VERSION ""

NS_ :

BS_:

BU_: SBZA_R_LS SBZA_L_LS VIS2_LS SDM_LS PEPS_LS UPA_LS PTM_LS MSM_LS HFP_LS EOCM_F_LS ECC_LS DCAC_LS CGM_LS BSM_LS BCM_LS AOS_LS

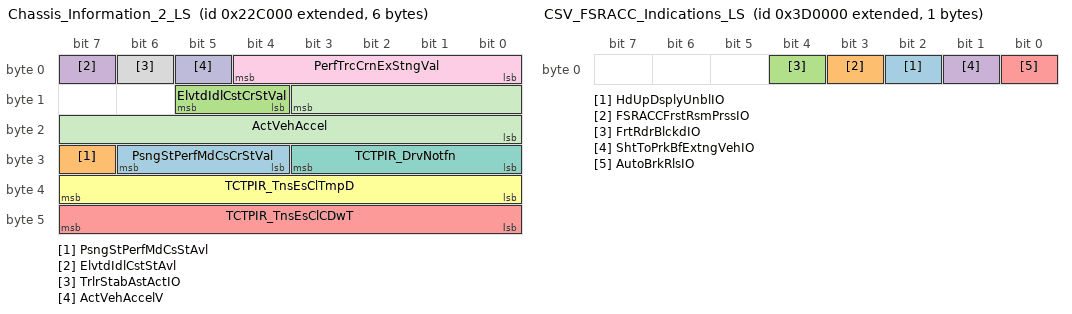
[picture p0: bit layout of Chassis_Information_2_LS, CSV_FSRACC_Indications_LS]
BO_ 2149761024 Chassis_Information_2_LS: 6 BCM_LS
 SG_ PsngStPerfMdCsCrStVal : 30|3@0+ (1,0) [0|7] ""  CGM_LS
 SG_ PsngStPerfMdCsStAvl : 31|1@0+ (1,0) [0|1] ""  CGM_LS
 SG_ ElvtdIdlCstCrStVal : 13|2@0+ (1,0) [0|3] ""  CGM_LS
 SG_ ElvtdIdlCstStAvl : 7|1@0+ (1,0) [0|1] ""  CGM_LS
 SG_ TCTPIR_TnsEsClCDwT : 47|8@0+ (0.392157,0) [0|100.000035] "%"  CGM_LS
 SG_ TCTPIR_TnsEsClTmpD : 39|8@0+ (0.392157,0) [0|100.000035] "%"  CGM_LS
 SG_ TCTPIR_DrvNotfn : 27|4@0+ (1,0) [0|15] ""  CGM_LS
 SG_ TrlrStabAstActIO : 6|1@0+ (1,0) [0|1] ""  CGM_LS
 SG_ PerfTrcCrnExStngVal : 4|5@0+ (1,0) [0|31] ""  CGM_LS
 SG_ ActVehAccelV : 5|1@0+ (1,0) [0|1] ""  CGM_LS
 SG_ ActVehAccel : 11|12@0- (0.01,0) [-20.48|20.47] "m/s^2"  CGM_LS

BO_ 2151481344 CSV_FSRACC_Indications_LS: 1 EOCM_F_LS
 SG_ HdUpDsplyUnblIO : 2|1@0+ (1,0) [0|1] ""  CGM_LS
 SG_ FSRACCFrstRsmPrssIO : 3|1@0+ (1,0) [0|1] ""  CGM_LS
 SG_ FrtRdrBlckdIO : 4|1@0+ (1,0) [0|1] ""  CGM_LS
 SG_ ShtToPrkBfExtngVehIO : 1|1@0+ (1,0) [0|1] ""  CGM_LS
 SG_ AutoBrkRlsIO : 0|1@0+ (1,0) [0|1] ""  CGM_LS

BO_ 2151432192 ACC_Drv_Seat_Vib_Req_IO_LS: 1 EOCM_F_LS
 SG_ ACCHptcStVbnRqSeqN : 1|2@0+ (1,0) [0|3] ""  MSM_LS,CGM_LS
 SG_ ACCHptcStVbnReq : 7|6@0+ (1,0) [0|63] ""  MSM_LS,CGM_LS

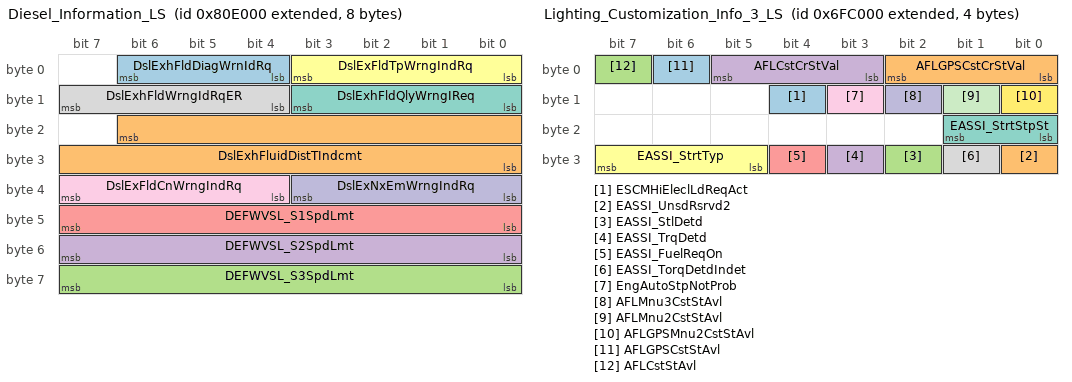
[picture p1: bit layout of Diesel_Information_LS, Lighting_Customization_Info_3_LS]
BO_ 2155929600 Diesel_Information_LS: 8 BCM_LS
 SG_ DslExhFldDiagWrnIdRq : 6|3@0+ (1,0) [0|7] ""  CGM_LS
 SG_ DslExhFluidDistTIndcmt : 22|15@0+ (2,0) [0|65534] "km"  CGM_LS
 SG_ DEFWVSL_S3SpdLmt : 63|8@0+ (1,0) [0|255] "km / h"  CGM_LS
 SG_ DEFWVSL_S2SpdLmt : 55|8@0+ (1,0) [0|255] "km / h"  CGM_LS
 SG_ DEFWVSL_S1SpdLmt : 47|8@0+ (1,0) [0|255] "km / h"  CGM_LS
 SG_ DslExFldTpWrngIndRq : 3|4@0+ (1,0) [0|15] ""  CGM_LS
 SG_ DslExhFldQlyWrngIReq : 11|4@0+ (1,0) [0|15] ""  CGM_LS
 SG_ DslExhFldWrngIdRqER : 15|4@0+ (1,0) [0|15] ""  CGM_LS
 SG_ DslExFldCnWrngIndRq : 39|4@0+ (1,0) [0|15] ""  CGM_LS
 SG_ DslExNxEmWrngIndRq : 35|4@0+ (1,0) [0|15] ""  CGM_LS

BO_ 2154807296 Lighting_Customization_Info_3_LS: 4 BCM_LS
 SG_ ESCMHiEleclLdReqAct : 12|1@0+ (1,0) [0|1] ""  ECC_LS,CGM_LS
 SG_ EASSI_UnsdRsrvd2 : 24|1@0+ (1,0) [0|1] ""  ECC_LS,CGM_LS
 SG_ EASSI_StlDetd : 26|1@0+ (1,0) [0|1] ""  ECC_LS,CGM_LS
 SG_ EASSI_TrqDetd : 27|1@0+ (1,0) [0|1] ""  ECC_LS,CGM_LS
 SG_ EASSI_FuelReqOn : 28|1@0+ (1,0) [0|1] ""  ECC_LS,CGM_LS
 SG_ EASSI_StrtTyp : 31|3@0+ (1,0) [0|7] ""  ECC_LS,CGM_LS
 SG_ EASSI_StrtStpSt : 17|2@0+ (1,0) [0|3] ""  ECC_LS,CGM_LS
 SG_ EASSI_TorqDetdIndet : 25|1@0+ (1,0) [0|1] ""  ECC_LS,CGM_LS
 SG_ EngAutoStpNotProb : 11|1@0+ (1,0) [0|1] ""  ECC_LS,CGM_LS
 SG_ AFLMnu3CstStAvl : 10|1@0+ (1,0) [0|1] ""  CGM_LS
 SG_ AFLMnu2CstStAvl : 9|1@0+ (1,0) [0|1] ""  CGM_LS
 SG_ AFLGPSMnu2CstStAvl : 8|1@0+ (1,0) [0|1] ""  CGM_LS
 SG_ AFLGPSCstStAvl : 6|1@0+ (1,0) [0|1] ""  CGM_LS
 SG_ AFLGPSCstCrStVal : 2|3@0+ (1,0) [0|7] ""  CGM_LS
 SG_ AFLCstStAvl : 7|1@0+ (1,0) [0|1] ""  CGM_LS
 SG_ AFLCstCrStVal : 5|3@0+ (1,0) [0|7] ""  CGM_LS

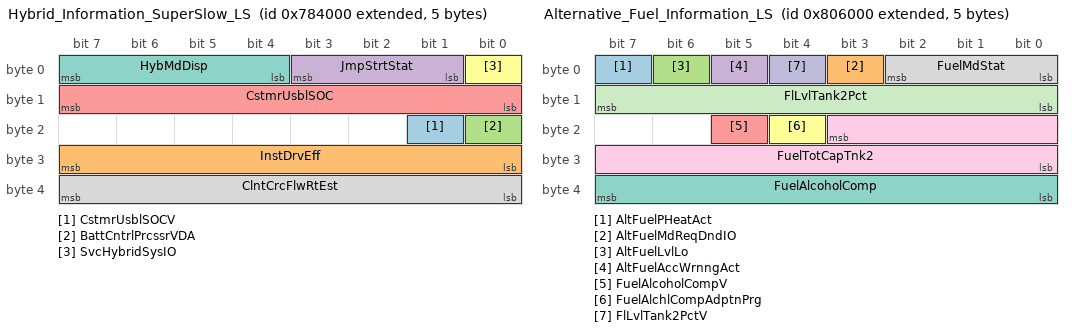
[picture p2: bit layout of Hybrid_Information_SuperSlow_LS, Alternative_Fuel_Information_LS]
BO_ 2155364352 Hybrid_Information_SuperSlow_LS: 5 BCM_LS
 SG_ CstmrUsblSOCV : 17|1@0+ (1,0) [0|1] ""  CGM_LS,BCM_LS
 SG_ InstDrvEff : 31|8@0- (0.78125,0) [-100|99.21875] "%"  CGM_LS
 SG_ BattCntrlPrcssrVDA : 16|1@0+ (1,0) [0|1] ""  CGM_LS
 SG_ JmpStrtStat : 3|3@0+ (1,0) [0|7] ""  CGM_LS
 SG_ CstmrUsblSOC : 15|8@0+ (0.39216,0) [0|100.0008] "%"  CGM_LS,BCM_LS
 SG_ SvcHybridSysIO : 0|1@0+ (1,0) [0|1] ""  CGM_LS
 SG_ HybMdDisp : 7|4@0+ (1,0) [0|15] ""  CGM_LS
 SG_ ClntCrcFlwRtEst : 39|8@0+ (0.392157,0) [0|100.000035] "%"  ECC_LS,CGM_LS

BO_ 2155896832 Alternative_Fuel_Information_LS: 5 BCM_LS
 SG_ AltFuelPHeatAct : 7|1@0+ (1,0) [0|1] ""  CGM_LS
 SG_ AltFuelMdReqDndIO : 3|1@0+ (1,0) [0|1] ""  CGM_LS
 SG_ AltFuelLvlLo : 6|1@0+ (1,0) [0|1] ""  CGM_LS
 SG_ AltFuelAccWrnngAct : 5|1@0+ (1,0) [0|1] ""  CGM_LS
 SG_ FuelAlcoholCompV : 21|1@0+ (1,0) [0|1] ""  CGM_LS
 SG_ FuelAlchlCompAdptnPrg : 20|1@0+ (1,0) [0|1] ""  CGM_LS
 SG_ FuelAlcoholComp : 39|8@0+ (0.392157,0) [0|100.000035] "%"  CGM_LS
 SG_ FuelMdStat : 2|3@0+ (1,0) [0|7] ""  CGM_LS
 SG_ FuelTotCapTnk2 : 19|12@0+ (0.125,0) [0|511.875] "liters"  CGM_LS
 SG_ FlLvlTank2PctV : 4|1@0+ (1,0) [0|1] ""  CGM_LS
 SG_ FlLvlTank2Pct : 15|8@0+ (0.392157,0) [0|100.000035] "%"  CGM_LS

BO_ 2153390080 Manual_Liftgate_Control_LS: 1 BCM_LS
 SG_ RrClosOpenSwAct_2D1V : 3|1@0+ (1,0) [0|1] ""  CGM_LS
 SG_ RrClosOpenSwAct_2D1 : 1|1@0+ (1,0) [0|1] ""  CGM_LS

BO_ 2155175936 CruiseControlGapSwitch_LS: 1 BCM_LS
 SG_ AdptCrsLKALDWSwAct : 2|1@0+ (1,0) [0|1] ""  CGM_LS
 SG_ AdptCrsGapSwAct : 1|2@0+ (1,0) [0|3] ""  CGM_LS

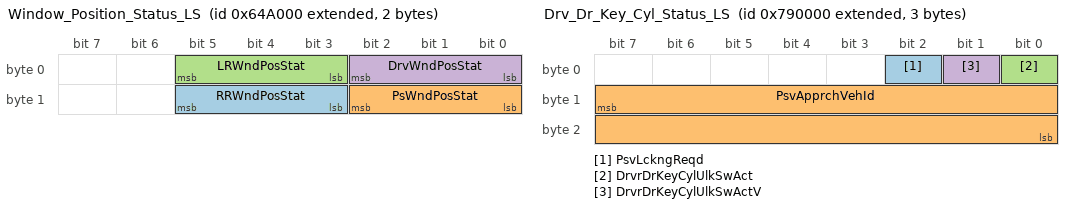
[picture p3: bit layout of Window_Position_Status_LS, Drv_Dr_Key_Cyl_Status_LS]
BO_ 2154078208 Window_Position_Status_LS: 2 BCM_LS
 SG_ RRWndPosStat : 13|3@0+ (1,0) [0|7] ""  PTM_LS,CGM_LS
 SG_ PsWndPosStat : 10|3@0+ (1,0) [0|7] ""  PTM_LS,CGM_LS
 SG_ LRWndPosStat : 5|3@0+ (1,0) [0|7] ""  PTM_LS,CGM_LS
 SG_ DrvWndPosStat : 2|3@0+ (1,0) [0|7] ""  PTM_LS,CGM_LS

BO_ 2155495424 Remote_Start_Seat_Request_LS: 1 BCM_LS
 SG_ RmStrHtdStEnRq : 1|1@0+ (1,0) [0|1] ""  MSM_LS,ECC_LS,CGM_LS
 SG_ RmStrCldStEnReq : 0|1@0+ (1,0) [0|1] ""  MSM_LS,CGM_LS

BO_ 2155413504 Drv_Dr_Key_Cyl_Status_LS: 3 BCM_LS
 SG_ PsvLckngReqd : 2|1@0+ (1,0) [0|1] ""  PEPS_LS,CGM_LS
 SG_ PsvApprchVehId : 15|16@0+ (1,0) [0|65535] ""  PEPS_LS,CGM_LS
 SG_ DrvrDrKeyCylUlkSwAct : 0|1@0+ (1,0) [0|1] ""  PEPS_LS,CGM_LS
 SG_ DrvrDrKeyCylUlkSwActV : 1|1@0+ (1,0) [0|1] ""  PEPS_LS,CGM_LS

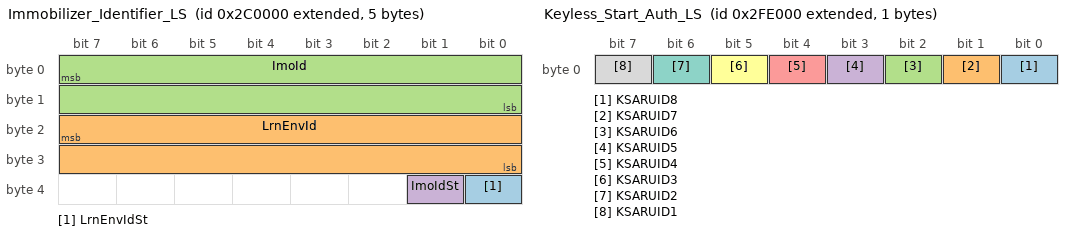
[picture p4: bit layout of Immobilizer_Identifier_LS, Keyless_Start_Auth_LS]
BO_ 2150367232 Immobilizer_Identifier_LS: 5 BCM_LS
 SG_ LrnEnvIdSt : 32|1@0+ (1,0) [0|1] ""  SDM_LS,ECC_LS,CGM_LS
 SG_ LrnEnvId : 23|16@0+ (1,0) [0|65535] ""  SDM_LS,ECC_LS,CGM_LS
 SG_ ImoId : 7|16@0+ (1,0) [0|65535] ""  SDM_LS,ECC_LS,CGM_LS
 SG_ ImoIdSt : 33|1@0+ (1,0) [0|1] ""  SDM_LS,ECC_LS,CGM_LS

BO_ 2150621184 Keyless_Start_Auth_LS: 1 BCM_LS
 SG_ KSARUID8 : 0|1@0+ (1,0) [0|1] ""  PEPS_LS,CGM_LS
 SG_ KSARUID7 : 1|1@0+ (1,0) [0|1] ""  PEPS_LS,CGM_LS
 SG_ KSARUID6 : 2|1@0+ (1,0) [0|1] ""  PEPS_LS,CGM_LS
 SG_ KSARUID5 : 3|1@0+ (1,0) [0|1] ""  PEPS_LS,CGM_LS
 SG_ KSARUID4 : 4|1@0+ (1,0) [0|1] ""  PEPS_LS,CGM_LS
 SG_ KSARUID3 : 5|1@0+ (1,0) [0|1] ""  PEPS_LS,CGM_LS
 SG_ KSARUID2 : 6|1@0+ (1,0) [0|1] ""  PEPS_LS,CGM_LS
 SG_ KSARUID1 : 7|1@0+ (1,0) [0|1] ""  PEPS_LS,CGM_LS

BO_ 2151309312 Inflatable_Restraints_Key_Id_LS: 2 BCM_LS
 SG_ InflRestId : 7|16@0+ (1,0) [0|39321] ""  SDM_LS,CGM_LS

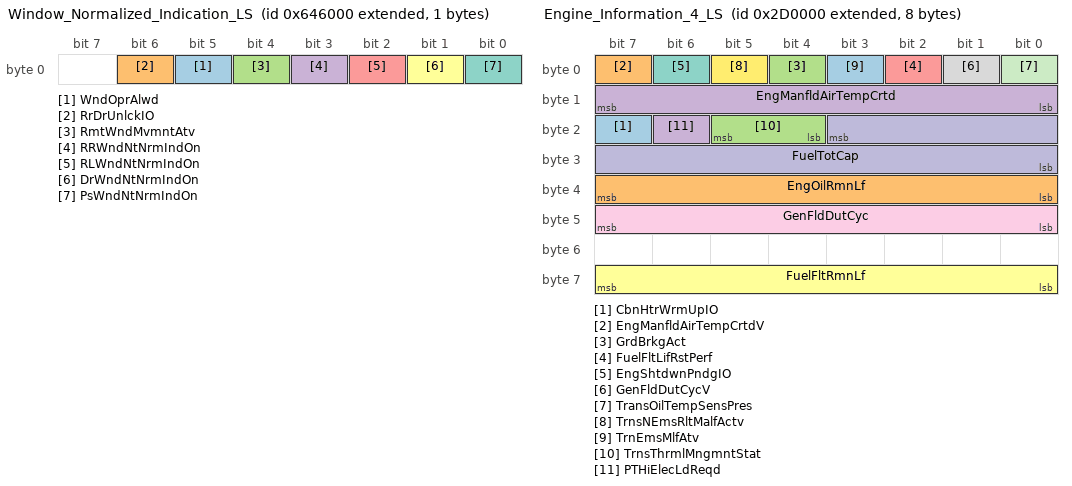
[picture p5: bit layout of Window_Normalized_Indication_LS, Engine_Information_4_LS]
BO_ 2154061824 Window_Normalized_Indication_LS: 1 BCM_LS
 SG_ WndOprAlwd : 5|1@0+ (1,0) [0|1] ""  CGM_LS
 SG_ RrDrUnlckIO : 6|1@0+ (1,0) [0|1] ""  CGM_LS
 SG_ RmtWndMvmntAtv : 4|1@0+ (1,0) [0|1] ""  CGM_LS
 SG_ RRWndNtNrmIndOn : 3|1@0+ (1,0) [0|1] ""  CGM_LS
 SG_ RLWndNtNrmIndOn : 2|1@0+ (1,0) [0|1] ""  CGM_LS
 SG_ DrWndNtNrmIndOn : 1|1@0+ (1,0) [0|1] ""  CGM_LS
 SG_ PsWndNtNrmIndOn : 0|1@0+ (1,0) [0|1] ""  CGM_LS

BO_ 2154512384 Rear_Closure_Rel_Sw_Sta_LS: 1 BCM_LS
 SG_ RrClosRelSwActV : 1|1@0+ (1,0) [0|1] ""  PEPS_LS,CGM_LS
 SG_ RrClosRelSwAct : 0|1@0+ (1,0) [0|1] ""  PEPS_LS,CGM_LS

BO_ 2155347968 HS_Indications_Slow_LS: 8 BCM_LS
 SG_ DrvrStPerfMdCsCrStVal : 62|3@0+ (1,0) [0|7] ""  CGM_LS
 SG_ DrvrStPerfMdCsStAvl : 63|1@0+ (1,0) [0|1] ""  CGM_LS
 SG_ ACCPerfMdCsCrStVal : 58|3@0+ (1,0) [0|7] ""  CGM_LS
 SG_ ACCPerfMdCsStAvl : 59|1@0+ (1,0) [0|1] ""  CGM_LS
 SG_ VehRollAngleV : 55|1@0+ (1,0) [0|1] ""  CGM_LS
 SG_ VehRollAngle : 54|7@0+ (0.703125,-45) [-45|44.296875] "deg"  CGM_LS
 SG_ ActVbnCtrlMlfIO : 0|1@0+ (1,0) [0|1] ""  CGM_LS
 SG_ HillDesCtrlRedVehSpIO : 47|1@0+ (1,0) [0|1] ""  CGM_LS
 SG_ FourWhlDrvIndReq : 42|3@0+ (1,0) [0|7] ""  CGM_LS
 SG_ PedtrnProtVDA : 35|1@0+ (1,0) [0|1] ""  CGM_LS
 SG_ EngRecDwnshftIO : 43|1@0+ (1,0) [0|1] ""  CGM_LS
 SG_ AppCltchAutSrtIO : 36|1@0+ (1,0) [0|1] ""  CGM_LS
 SG_ CPSUnblIO : 32|1@0+ (1,0) [0|1] ""  CGM_LS
 SG_ StBltTgtSetAvl : 37|1@0+ (1,0) [0|1] ""  CGM_LS
 SG_ StBltTgtCrtSetVal : 46|3@0+ (1,0) [0|7] ""  CGM_LS
 SG_ PedtrnProtSysDisbld : 34|1@0+ (1,0) [0|1] ""  CGM_LS
 SG_ PedtrnProtSysDpl : 1|1@0+ (1,0) [0|1] ""  CGM_LS
 SG_ SrvPedtrnProtSysIO : 33|1@0+ (1,0) [0|1] ""  CGM_LS
 SG_ CPSOffIO : 31|1@0+ (1,0) [0|1] ""  CGM_LS
 SG_ SecAxlTmpInhIO : 24|1@0+ (1,0) [0|1] ""  CGM_LS
 SG_ CPSFldIO : 30|1@0+ (1,0) [0|1] ""  CGM_LS
 SG_ CPSAlrtOnlIO : 25|1@0+ (1,0) [0|1] ""  CGM_LS
 SG_ RrAxlTmpInhIO : 23|1@0+ (1,0) [0|1] ""  CGM_LS
 SG_ TirePrsLowIO : 2|1@0+ (1,0) [0|1] ""  SDM_LS,CGM_LS
 SG_ EPBSysStatIndReq : 27|2@0+ (1,0) [0|3] ""  CGM_LS
 SG_ EngOilStrvtnIO : 5|1@0+ (1,0) [0|1] ""  CGM_LS
 SG_ SrvSuspSysIO : 12|1@0+ (1,0) [0|1] ""  CGM_LS
 SG_ ServAdpCrsCtrlIndOn : 11|1@0+ (1,0) [0|1] ""  CGM_LS
 SG_ EngRecmndUpshftIO : 10|1@0+ (1,0) [0|1] ""  CGM_LS
 SG_ BrkSysMalFuncIndOn : 15|1@0+ (1,0) [0|1] ""  VIS2_LS,CGM_LS
 SG_ SecAxlNonEmMalfIO : 6|1@0+ (1,0) [0|1] ""  CGM_LS
 SG_ BrkFldLvlLw : 7|1@0+ (1,0) [0|1] ""  CGM_LS
 SG_ ACCUnavlbleDTWthrIO : 3|1@0+ (1,0) [0|1] ""  CGM_LS
 SG_ ACCTmpUnavlbleIO : 9|1@0+ (1,0) [0|1] ""  CGM_LS
 SG_ EngEmsRelMalfIndReq : 18|3@0+ (1,0) [0|7] ""  CGM_LS
 SG_ DrShftCntrlReqDndIO : 20|1@0+ (1,0) [0|1] ""  CGM_LS
 SG_ BrkPadWrnIO : 13|1@0+ (1,0) [0|1] ""  CGM_LS
 SG_ RrAxlMalfIO : 19|1@0+ (1,0) [0|1] ""  CGM_LS
 SG_ EPBSysWrnIndReq : 29|2@0+ (1,0) [0|3] ""  CGM_LS
 SG_ CompOvrhtIndOn : 21|1@0+ (1,0) [0|1] ""  CGM_LS
 SG_ BrkFldLvlLwV : 4|1@0+ (1,0) [0|1] ""  CGM_LS
 SG_ ACCSnsClnRqdIO : 8|1@0+ (1,0) [0|1] ""  CGM_LS
 SG_ TrnsSkpShftIO : 22|1@0+ (1,0) [0|1] ""  CGM_LS

BO_ 2150432768 Engine_Information_4_LS: 8 BCM_LS
 SG_ CbnHtrWrmUpIO : 23|1@0+ (1,0) [0|1] ""  CGM_LS
 SG_ EngManfldAirTempCrtdV : 7|1@0+ (1,0) [0|1] ""  ECC_LS,CGM_LS
 SG_ GrdBrkgAct : 4|1@0+ (1,0) [0|1] ""  CGM_LS
 SG_ EngManfldAirTempCrtd : 15|8@0+ (1,-40) [-40|215] "deg C"  ECC_LS,CGM_LS
 SG_ FuelFltLifRstPerf : 2|1@0+ (1,0) [0|1] ""  CGM_LS
 SG_ FuelFltRmnLf : 63|8@0+ (0.392157,0) [0|100.000035] "%"  CGM_LS
 SG_ EngShtdwnPndgIO : 6|1@0+ (1,0) [0|1] ""  CGM_LS
 SG_ GenFldDutCycV : 1|1@0+ (1,0) [0|1] ""  ECC_LS,CGM_LS
 SG_ GenFldDutCyc : 47|8@0+ (0.392157,0) [0|100.000035] "%"  ECC_LS,CGM_LS
 SG_ FuelTotCap : 19|12@0+ (0.125,0) [0|511.875] "liters"  CGM_LS
 SG_ TransOilTempSensPres : 0|1@0+ (1,0) [0|1] ""  CGM_LS
 SG_ TrnsNEmsRltMalfActv : 5|1@0+ (1,0) [0|1] ""  CGM_LS
 SG_ TrnEmsMlfAtv : 3|1@0+ (1,0) [0|1] ""  CGM_LS
 SG_ EngOilRmnLf : 39|8@0+ (0.392157,0) [0|100.000035] "%"  CGM_LS
 SG_ TrnsThrmlMngmntStat : 21|2@0+ (1,0) [0|3] ""  CGM_LS
 SG_ PTHiElecLdReqd : 22|1@0+ (1,0) [0|1] ""  ECC_LS,CGM_LS

BO_ 2154938368 Fob_Programming_Mode_Status_LS: 1 BCM_LS
 SG_ FobProgMdStat : 1|2@0+ (1,0) [0|3] ""  CGM_LS

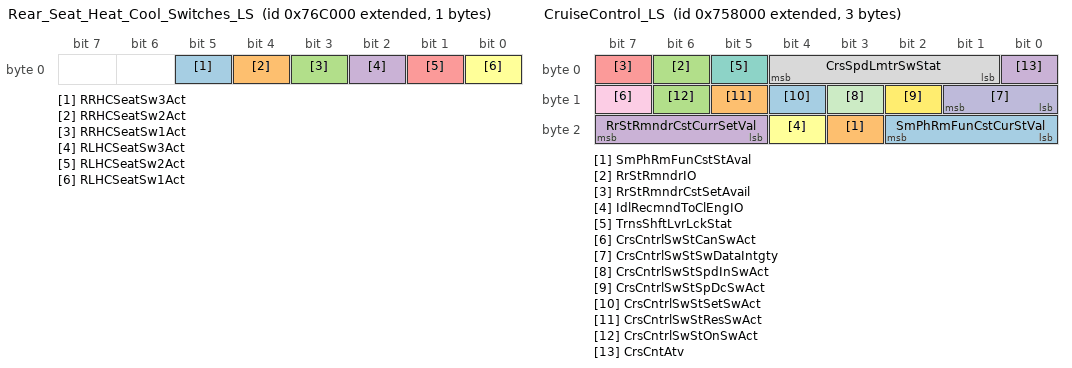
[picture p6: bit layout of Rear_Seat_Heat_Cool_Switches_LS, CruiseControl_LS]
BO_ 2155266048 Rear_Seat_Heat_Cool_Switches_LS: 1 BCM_LS
 SG_ RRHCSeatSw3Act : 5|1@0+ (1,0) [0|1] ""  BCM_LS,CGM_LS
 SG_ RRHCSeatSw2Act : 4|1@0+ (1,0) [0|1] ""  BCM_LS,CGM_LS
 SG_ RRHCSeatSw1Act : 3|1@0+ (1,0) [0|1] ""  BCM_LS,CGM_LS
 SG_ RLHCSeatSw3Act : 2|1@0+ (1,0) [0|1] ""  BCM_LS,CGM_LS
 SG_ RLHCSeatSw2Act : 1|1@0+ (1,0) [0|1] ""  BCM_LS,CGM_LS
 SG_ RLHCSeatSw1Act : 0|1@0+ (1,0) [0|1] ""  BCM_LS,CGM_LS

BO_ 2155249664 Rear_Seat_Heat_Cool_Control_LS: 4 BCM_LS
 SG_ RRHCSMInd3 : 8|1@0+ (1,0) [0|1] ""  ECC_LS,CGM_LS,BCM_LS
 SG_ RRHCSMInd2 : 9|1@0+ (1,0) [0|1] ""  ECC_LS,CGM_LS,BCM_LS
 SG_ RRHCSMInd1 : 10|1@0+ (1,0) [0|1] ""  ECC_LS,CGM_LS,BCM_LS
 SG_ RRHCSMIndReq : 12|2@0+ (1,0) [0|3] ""  ECC_LS,CGM_LS,BCM_LS
 SG_ RRHCSLSeatLev5 : 24|1@0+ (1,0) [0|1] ""  ECC_LS,CGM_LS,BCM_LS
 SG_ RRHCSLSeatLev4 : 25|1@0+ (1,0) [0|1] ""  ECC_LS,CGM_LS,BCM_LS
 SG_ RRHCSLSeatLev3 : 26|1@0+ (1,0) [0|1] ""  ECC_LS,CGM_LS,BCM_LS
 SG_ RRHCSLSeatLev2 : 27|1@0+ (1,0) [0|1] ""  ECC_LS,CGM_LS,BCM_LS
 SG_ RRHCSLSeatLev1 : 28|1@0+ (1,0) [0|1] ""  ECC_LS,CGM_LS,BCM_LS
 SG_ RRHCSLIndReq : 30|2@0+ (1,0) [0|3] ""  ECC_LS,CGM_LS,BCM_LS
 SG_ RLHCSMInd3 : 0|1@0+ (1,0) [0|1] ""  ECC_LS,CGM_LS,BCM_LS
 SG_ RLHCSMInd2 : 1|1@0+ (1,0) [0|1] ""  ECC_LS,CGM_LS,BCM_LS
 SG_ RLHCSMInd1 : 2|1@0+ (1,0) [0|1] ""  ECC_LS,CGM_LS,BCM_LS
 SG_ RLHCSMIndReq : 4|2@0+ (1,0) [0|3] ""  ECC_LS,CGM_LS,BCM_LS
 SG_ RLHCSLSeatLev5 : 16|1@0+ (1,0) [0|1] ""  ECC_LS,CGM_LS,BCM_LS
 SG_ RLHCSLSeatLev4 : 17|1@0+ (1,0) [0|1] ""  ECC_LS,CGM_LS,BCM_LS
 SG_ RLHCSLSeatLev3 : 18|1@0+ (1,0) [0|1] ""  ECC_LS,CGM_LS,BCM_LS
 SG_ RLHCSLSeatLev2 : 19|1@0+ (1,0) [0|1] ""  ECC_LS,CGM_LS,BCM_LS
 SG_ RLHCSLSeatLev1 : 20|1@0+ (1,0) [0|1] ""  ECC_LS,CGM_LS,BCM_LS
 SG_ RLHCSLIndReq : 22|2@0+ (1,0) [0|3] ""  ECC_LS,CGM_LS,BCM_LS

BO_ 2155184128 CruiseControl_LS: 3 BCM_LS
 SG_ SmPhRmFunCstCurStVal : 18|3@0+ (1,0) [0|7] ""  CGM_LS
 SG_ SmPhRmFunCstStAval : 19|1@0+ (1,0) [0|1] ""  CGM_LS
 SG_ RrStRmndrIO : 6|1@0+ (1,0) [0|1] ""  CGM_LS
 SG_ RrStRmndrCstCurrSetVal : 23|3@0+ (1,0) [0|7] ""  CGM_LS
 SG_ RrStRmndrCstSetAvail : 7|1@0+ (1,0) [0|1] ""  CGM_LS
 SG_ IdlRecmndToClEngIO : 20|1@0+ (1,0) [0|1] ""  CGM_LS
 SG_ TrnsShftLvrLckStat : 5|1@0+ (1,0) [0|1] ""  CGM_LS
 SG_ CrsSpdLmtrSwStat : 4|4@0+ (1,0) [0|15] ""  SDM_LS,CGM_LS
 SG_ CrsCntrlSwStCanSwAct : 15|1@0+ (1,0) [0|1] ""  SDM_LS,CGM_LS
 SG_ CrsCntrlSwStSwDataIntgty : 9|2@0+ (1,0) [0|3] ""  SDM_LS,CGM_LS
 SG_ CrsCntrlSwStSpdInSwAct : 11|1@0+ (1,0) [0|1] ""  SDM_LS,CGM_LS
 SG_ CrsCntrlSwStSpDcSwAct : 10|1@0+ (1,0) [0|1] ""  SDM_LS,CGM_LS
 SG_ CrsCntrlSwStSetSwAct : 12|1@0+ (1,0) [0|1] ""  SDM_LS,CGM_LS
 SG_ CrsCntrlSwStResSwAct : 13|1@0+ (1,0) [0|1] ""  SDM_LS,CGM_LS
 SG_ CrsCntrlSwStOnSwAct : 14|1@0+ (1,0) [0|1] ""  SDM_LS,CGM_LS
 SG_ CrsCntAtv : 0|1@0+ (1,0) [0|1] ""  VIS2_LS,SDM_LS,CGM_LS

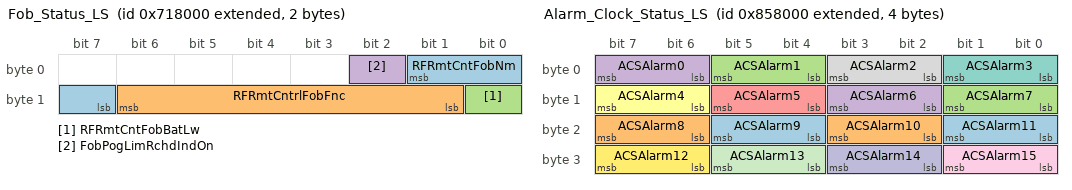
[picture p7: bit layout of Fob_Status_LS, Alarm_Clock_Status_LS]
BO_ 2154921984 Fob_Status_LS: 2 BCM_LS
 SG_ RFRmtCntFobNm : 1|3@0+ (1,0) [0|7] ""  PTM_LS,PEPS_LS,MSM_LS,BSM_LS,CGM_LS
 SG_ RFRmtCntrlFobFnc : 14|6@0+ (1,0) [0|63] ""  PTM_LS,PEPS_LS,MSM_LS,BSM_LS,CGM_LS
 SG_ RFRmtCntFobBatLw : 8|1@0+ (1,0) [0|1] ""  PTM_LS,PEPS_LS,MSM_LS,BSM_LS,CGM_LS
 SG_ FobPogLimRchdIndOn : 2|1@0+ (1,0) [0|1] ""  CGM_LS

BO_ 2154962944 Front_Seat_Heat_Cool_Control_LS: 4 BCM_LS
 SG_ PassHCSMInd3 : 8|1@0+ (1,0) [0|1] ""  ECC_LS,CGM_LS
 SG_ PassHCSMInd2 : 9|1@0+ (1,0) [0|1] ""  ECC_LS,CGM_LS
 SG_ PassHCSMInd1 : 10|1@0+ (1,0) [0|1] ""  ECC_LS,CGM_LS
 SG_ PassHCSMIndReq : 12|2@0+ (1,0) [0|3] ""  ECC_LS,CGM_LS
 SG_ PassHCSLSeatLev5 : 24|1@0+ (1,0) [0|1] ""  ECC_LS,CGM_LS
 SG_ PassHCSLSeatLev4 : 25|1@0+ (1,0) [0|1] ""  ECC_LS,CGM_LS
 SG_ PassHCSLSeatLev3 : 26|1@0+ (1,0) [0|1] ""  ECC_LS,CGM_LS
 SG_ PassHCSLSeatLev2 : 27|1@0+ (1,0) [0|1] ""  ECC_LS,CGM_LS
 SG_ PassHCSLSeatLev1 : 28|1@0+ (1,0) [0|1] ""  ECC_LS,CGM_LS
 SG_ PassHCSLIndReq : 30|2@0+ (1,0) [0|3] ""  ECC_LS,CGM_LS
 SG_ DrvHCSMInd1 : 2|1@0+ (1,0) [0|1] ""  ECC_LS,CGM_LS
 SG_ DrvHCSMIndReq : 4|2@0+ (1,0) [0|3] ""  ECC_LS,CGM_LS
 SG_ DrvHCSMInd3 : 0|1@0+ (1,0) [0|1] ""  ECC_LS,CGM_LS
 SG_ DrvHCSMInd2 : 1|1@0+ (1,0) [0|1] ""  ECC_LS,CGM_LS
 SG_ DrvHCSLSeatLev5 : 16|1@0+ (1,0) [0|1] ""  ECC_LS,CGM_LS
 SG_ DrvHCSLSeatLev4 : 17|1@0+ (1,0) [0|1] ""  ECC_LS,CGM_LS
 SG_ DrvHCSLSeatLev3 : 18|1@0+ (1,0) [0|1] ""  ECC_LS,CGM_LS
 SG_ DrvHCSLSeatLev2 : 19|1@0+ (1,0) [0|1] ""  ECC_LS,CGM_LS
 SG_ DrvHCSLSeatLev1 : 20|1@0+ (1,0) [0|1] ""  ECC_LS,CGM_LS
 SG_ DrvHCSLIndReq : 22|2@0+ (1,0) [0|3] ""  ECC_LS,CGM_LS

BO_ 2156232704 Alarm_Clock_Status_LS: 4 BCM_LS
 SG_ ACSAlarm9 : 21|2@0+ (1,0) [0|3] ""  PTM_LS,ECC_LS,CGM_LS
 SG_ ACSAlarm8 : 23|2@0+ (1,0) [0|3] ""  PTM_LS,ECC_LS,CGM_LS
 SG_ ACSAlarm7 : 9|2@0+ (1,0) [0|3] ""  PTM_LS,ECC_LS,CGM_LS
 SG_ ACSAlarm6 : 11|2@0+ (1,0) [0|3] ""  PTM_LS,ECC_LS,CGM_LS
 SG_ ACSAlarm5 : 13|2@0+ (1,0) [0|3] ""  PTM_LS,ECC_LS,CGM_LS
 SG_ ACSAlarm4 : 15|2@0+ (1,0) [0|3] ""  PTM_LS,ECC_LS,CGM_LS
 SG_ ACSAlarm3 : 1|2@0+ (1,0) [0|3] ""  PTM_LS,ECC_LS,CGM_LS
 SG_ ACSAlarm2 : 3|2@0+ (1,0) [0|3] ""  PTM_LS,ECC_LS,CGM_LS
 SG_ ACSAlarm15 : 25|2@0+ (1,0) [0|3] ""  PTM_LS,ECC_LS,CGM_LS
 SG_ ACSAlarm14 : 27|2@0+ (1,0) [0|3] ""  PTM_LS,ECC_LS,CGM_LS
 SG_ ACSAlarm13 : 29|2@0+ (1,0) [0|3] ""  PTM_LS,ECC_LS,CGM_LS
 SG_ ACSAlarm12 : 31|2@0+ (1,0) [0|3] ""  PTM_LS,ECC_LS,CGM_LS
 SG_ ACSAlarm11 : 17|2@0+ (1,0) [0|3] ""  PTM_LS,ECC_LS,CGM_LS
 SG_ ACSAlarm10 : 19|2@0+ (1,0) [0|3] ""  PTM_LS,ECC_LS,CGM_LS
 SG_ ACSAlarm1 : 5|2@0+ (1,0) [0|3] ""  PTM_LS,ECC_LS,CGM_LS
 SG_ ACSAlarm0 : 7|2@0+ (1,0) [0|3] ""  PTM_LS,ECC_LS,CGM_LS

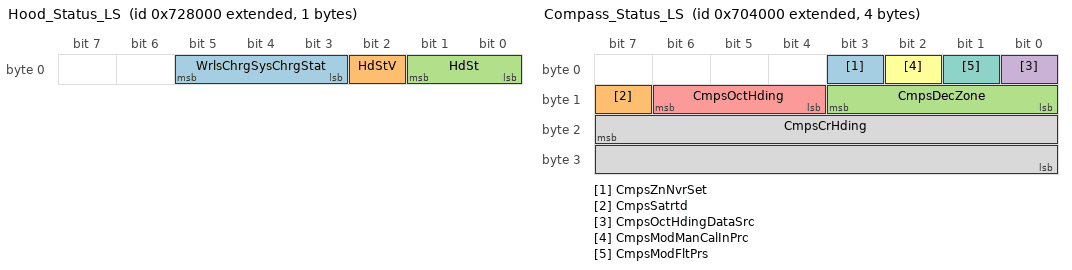
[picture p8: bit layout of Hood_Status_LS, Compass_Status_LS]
BO_ 2154987520 Hood_Status_LS: 1 BCM_LS
 SG_ WrlsChrgSysChrgStat : 5|3@0+ (1,0) [0|7] ""  CGM_LS
 SG_ HdStV : 2|1@0+ (1,0) [0|1] ""  CGM_LS
 SG_ HdSt : 1|2@0+ (1,0) [0|3] ""  CGM_LS

BO_ 2154840064 Compass_Status_LS: 4 BCM_LS
 SG_ CmpsZnNvrSet : 3|1@0+ (1,0) [0|1] ""  CGM_LS
 SG_ CmpsSatrtd : 15|1@0+ (1,0) [0|1] ""  CGM_LS
 SG_ CmpsDecZone : 11|4@0+ (1,0) [0|15] ""  CGM_LS
 SG_ CmpsOctHdingDataSrc : 0|1@0+ (1,0) [0|1] ""  CGM_LS
 SG_ CmpsOctHding : 14|3@0+ (1,0) [0|7] ""  CGM_LS
 SG_ CmpsModManCalInPrc : 2|1@0+ (1,0) [0|1] ""  CGM_LS
 SG_ CmpsModFltPrs : 1|1@0+ (1,0) [0|1] ""  CGM_LS
 SG_ CmpsCrHding : 23|16@0+ (0.0054932,0) [0|359.996862] "deg"  CGM_LS

BO_ 2154905600 Driver_Identifier_LS: 1 BCM_LS
 SG_ DrvSeatPrsMemID : 5|3@0+ (1,0) [0|7] ""  MSM_LS,CGM_LS
 SG_ DrId : 2|3@0+ (1,0) [0|7] ""  VIS2_LS,MSM_LS,EOCM_F_LS,ECC_LS,CGM_LS

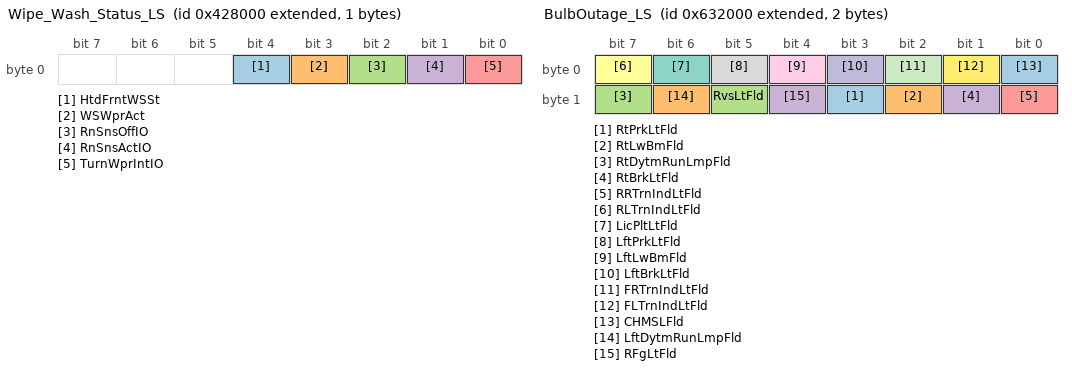
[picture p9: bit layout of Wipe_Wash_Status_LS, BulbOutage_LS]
BO_ 2151841792 Wipe_Wash_Status_LS: 1 BCM_LS
 SG_ HtdFrntWSSt : 4|1@0+ (1,0) [0|1] ""  CGM_LS
 SG_ WSWprAct : 3|1@0+ (1,0) [0|1] ""  SBZA_R_LS,SBZA_L_LS,VIS2_LS,CGM_LS
 SG_ RnSnsOffIO : 2|1@0+ (1,0) [0|1] ""  SBZA_R_LS,SBZA_L_LS,CGM_LS
 SG_ RnSnsActIO : 1|1@0+ (1,0) [0|1] ""  SBZA_R_LS,SBZA_L_LS,CGM_LS
 SG_ TurnWprIntIO : 0|1@0+ (1,0) [0|1] ""  SBZA_R_LS,SBZA_L_LS,CGM_LS

BO_ 2154094592 Adjustable_Pedal_Motion_Inh_LS: 8 BCM_LS
 SG_ IDCTA_ClrTyp21Avl : 49|1@0+ (1,0) [0|1] ""  CGM_LS
 SG_ IDCTA_ClrTyp20Avl : 50|1@0+ (1,0) [0|1] ""  CGM_LS
 SG_ IDCTA_ClrTyp19Avl : 51|1@0+ (1,0) [0|1] ""  CGM_LS
 SG_ IDCTA_ClrTyp18Avl : 52|1@0+ (1,0) [0|1] ""  CGM_LS
 SG_ IDCTA_ClrTyp17Avl : 53|1@0+ (1,0) [0|1] ""  CGM_LS
 SG_ IDCTA_ClrTyp16Avl : 54|1@0+ (1,0) [0|1] ""  CGM_LS
 SG_ IDCTA_ClrTyp15Avl : 55|1@0+ (1,0) [0|1] ""  CGM_LS
 SG_ IDCTA_ClrTyp14Avl : 40|1@0+ (1,0) [0|1] ""  CGM_LS
 SG_ IDCTA_ClrTyp13Avl : 41|1@0+ (1,0) [0|1] ""  CGM_LS
 SG_ IDCTA_ClrTyp12Avl : 42|1@0+ (1,0) [0|1] ""  CGM_LS
 SG_ IDCTA_ClrTyp11Avl : 43|1@0+ (1,0) [0|1] ""  CGM_LS
 SG_ IDCTA_ClrTyp10Avl : 44|1@0+ (1,0) [0|1] ""  CGM_LS
 SG_ IDCTA_ClrTyp9Avl : 45|1@0+ (1,0) [0|1] ""  CGM_LS
 SG_ IDCTA_ClrTyp8Avl : 46|1@0+ (1,0) [0|1] ""  CGM_LS
 SG_ IDCTA_ClrTyp7Avl : 47|1@0+ (1,0) [0|1] ""  CGM_LS
 SG_ IDCTA_ClrTyp6Avl : 32|1@0+ (1,0) [0|1] ""  CGM_LS
 SG_ IDCTA_ClrTyp5Avl : 33|1@0+ (1,0) [0|1] ""  CGM_LS
 SG_ IDCTA_ClrTyp4Avl : 34|1@0+ (1,0) [0|1] ""  CGM_LS
 SG_ IDCTA_ClrTyp3Avl : 35|1@0+ (1,0) [0|1] ""  CGM_LS
 SG_ IDCTA_ClrTyp2Avl : 36|1@0+ (1,0) [0|1] ""  CGM_LS
 SG_ IDCTA_ClrTyp1Avl : 37|1@0+ (1,0) [0|1] ""  CGM_LS
 SG_ IDCTA_OffAvl : 38|1@0+ (1,0) [0|1] ""  CGM_LS
 SG_ IDATA_AnmTyp14Avl : 24|1@0+ (1,0) [0|1] ""  CGM_LS
 SG_ IDATA_AnmTyp13Avl : 25|1@0+ (1,0) [0|1] ""  CGM_LS
 SG_ IDATA_AnmTyp12Avl : 26|1@0+ (1,0) [0|1] ""  CGM_LS
 SG_ IDATA_AnmTyp11Avl : 27|1@0+ (1,0) [0|1] ""  CGM_LS
 SG_ IDATA_AnmTyp10Avl : 28|1@0+ (1,0) [0|1] ""  CGM_LS
 SG_ IDATA_AnmTyp9Avl : 29|1@0+ (1,0) [0|1] ""  CGM_LS
 SG_ IDATA_AnmTyp8Avl : 30|1@0+ (1,0) [0|1] ""  CGM_LS
 SG_ IDATA_AnmTyp7Avl : 31|1@0+ (1,0) [0|1] ""  CGM_LS
 SG_ IDATA_AnmTyp6Avl : 16|1@0+ (1,0) [0|1] ""  CGM_LS
 SG_ IDATA_AnmTyp5Avl : 17|1@0+ (1,0) [0|1] ""  CGM_LS
 SG_ IDATA_AnmTyp4Avl : 18|1@0+ (1,0) [0|1] ""  CGM_LS
 SG_ IDATA_AnmTyp3Avl : 19|1@0+ (1,0) [0|1] ""  CGM_LS
 SG_ IDATA_AnmTyp2Avl : 20|1@0+ (1,0) [0|1] ""  CGM_LS
 SG_ IDATA_AnmTyp1Avl : 21|1@0+ (1,0) [0|1] ""  CGM_LS
 SG_ IDATA_OffAvl : 22|1@0+ (1,0) [0|1] ""  CGM_LS
 SG_ AdjPdlMotInhbtd : 0|1@0+ (1,0) [0|1] ""  MSM_LS,CGM_LS
 SG_ IntDimSeldClrTypStVal : 12|5@0+ (1,0) [0|31] ""  CGM_LS
 SG_ IntDimSeldAnmTypStVal : 4|4@0+ (1,0) [0|15] ""  CGM_LS
 SG_ IDCTA_ClrTyp30Avl : 56|1@0+ (1,0) [0|1] ""  CGM_LS
 SG_ IDCTA_ClrTyp29Avl : 57|1@0+ (1,0) [0|1] ""  CGM_LS
 SG_ IDCTA_ClrTyp28Avl : 58|1@0+ (1,0) [0|1] ""  CGM_LS
 SG_ IDCTA_ClrTyp27Avl : 59|1@0+ (1,0) [0|1] ""  CGM_LS
 SG_ IDCTA_ClrTyp26Avl : 60|1@0+ (1,0) [0|1] ""  CGM_LS
 SG_ IDCTA_ClrTyp25Avl : 61|1@0+ (1,0) [0|1] ""  CGM_LS
 SG_ IDCTA_ClrTyp24Avl : 62|1@0+ (1,0) [0|1] ""  CGM_LS
 SG_ IDCTA_ClrTyp23Avl : 63|1@0+ (1,0) [0|1] ""  CGM_LS
 SG_ IDCTA_ClrTyp22Avl : 48|1@0+ (1,0) [0|1] ""  CGM_LS

BO_ 2153979904 BulbOutage_LS: 2 BCM_LS
 SG_ RtPrkLtFld : 11|1@0+ (1,0) [0|1] ""  CGM_LS
 SG_ RtLwBmFld : 10|1@0+ (1,0) [0|1] ""  CGM_LS
 SG_ RtDytmRunLmpFld : 15|1@0+ (1,0) [0|1] ""  CGM_LS
 SG_ RtBrkLtFld : 9|1@0+ (1,0) [0|1] ""  CGM_LS
 SG_ RRTrnIndLtFld : 8|1@0+ (1,0) [0|1] ""  CGM_LS
 SG_ RLTrnIndLtFld : 7|1@0+ (1,0) [0|1] ""  CGM_LS
 SG_ LicPltLtFld : 6|1@0+ (1,0) [0|1] ""  CGM_LS
 SG_ LftPrkLtFld : 5|1@0+ (1,0) [0|1] ""  CGM_LS
 SG_ LftLwBmFld : 4|1@0+ (1,0) [0|1] ""  CGM_LS
 SG_ LftBrkLtFld : 3|1@0+ (1,0) [0|1] ""  CGM_LS
 SG_ FRTrnIndLtFld : 2|1@0+ (1,0) [0|1] ""  CGM_LS
 SG_ FLTrnIndLtFld : 1|1@0+ (1,0) [0|1] ""  CGM_LS
 SG_ CHMSLFld : 0|1@0+ (1,0) [0|1] ""  CGM_LS
 SG_ LftDytmRunLmpFld : 14|1@0+ (1,0) [0|1] ""  CGM_LS
 SG_ RvsLtFld : 13|1@0+ (1,0) [0|1] ""  CGM_LS
 SG_ RFgLtFld : 12|1@0+ (1,0) [0|1] ""  CGM_LS

BO_ 2150154240 Passive_Entry_Reply_LS: 8 BCM_LS
 SG_ PsvEntVehIdExt : 7|32@0+ (1,0) [0|4294967295] ""  PEPS_LS,CGM_LS
 SG_ PsvEntChlngRply : 39|32@0+ (1,0) [0|4294967295] "passwrd"  PEPS_LS,CGM_LS

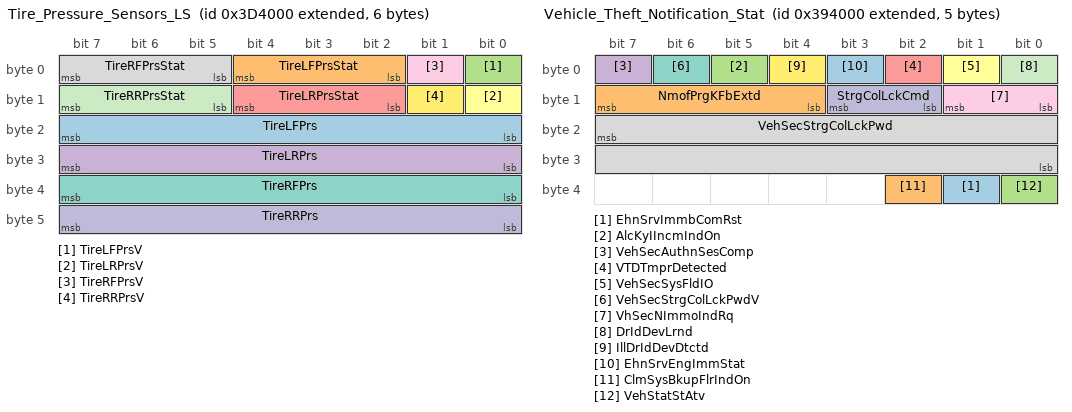
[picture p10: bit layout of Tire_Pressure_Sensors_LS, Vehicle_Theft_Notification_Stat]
BO_ 2151497728 Tire_Pressure_Sensors_LS: 6 BCM_LS
 SG_ TireLFPrs : 23|8@0+ (4,0) [0|1020] "kPaG"  CGM_LS
 SG_ TireLFPrsStat : 4|3@0+ (1,0) [0|7] ""  CGM_LS
 SG_ TireLFPrsV : 0|1@0+ (1,0) [0|1] ""  CGM_LS
 SG_ TireLRPrs : 31|8@0+ (4,0) [0|1020] "kPaG"  CGM_LS
 SG_ TireLRPrsStat : 12|3@0+ (1,0) [0|7] ""  CGM_LS
 SG_ TireLRPrsV : 8|1@0+ (1,0) [0|1] ""  CGM_LS
 SG_ TireRFPrs : 39|8@0+ (4,0) [0|1020] "kPaG"  CGM_LS
 SG_ TireRFPrsStat : 7|3@0+ (1,0) [0|7] ""  CGM_LS
 SG_ TireRFPrsV : 1|1@0+ (1,0) [0|1] ""  CGM_LS
 SG_ TireRRPrs : 47|8@0+ (4,0) [0|1020] "kPaG"  CGM_LS
 SG_ TireRRPrsStat : 15|3@0+ (1,0) [0|7] ""  CGM_LS
 SG_ TireRRPrsV : 9|1@0+ (1,0) [0|1] ""  CGM_LS

BO_ 2151219200 Remote_Start_Status: 1 BCM_LS
 SG_ RemStrtSt : 0|1@0+ (1,0) [0|1] ""  PTM_LS,MSM_LS,ECC_LS,CGM_LS
 SG_ RmVehStrRq : 1|1@0+ (1,0) [0|1] ""  PTM_LS,CGM_LS

BO_ 2151235584 Vehicle_Theft_Notification_Stat: 5 BCM_LS
 SG_ EhnSrvImmbComRst : 33|1@0+ (1,0) [0|1] ""  CGM_LS
 SG_ NmofPrgKFbExtd : 15|4@0+ (1,0) [0|15] ""  PEPS_LS,CGM_LS
 SG_ AlcKyIIncmIndOn : 5|1@0+ (1,0) [0|1] ""  CGM_LS
 SG_ VehSecAuthnSesComp : 7|1@0+ (1,0) [0|1] ""  CGM_LS
 SG_ VTDTmprDetected : 2|1@0+ (1,0) [0|1] ""  CGM_LS
 SG_ VehSecSysFldIO : 1|1@0+ (1,0) [0|1] ""  CGM_LS
 SG_ VehSecStrgColLckPwdV : 6|1@0+ (1,0) [0|1] ""  CGM_LS
 SG_ VehSecStrgColLckPwd : 23|16@0+ (1,0) [0|65535] ""  CGM_LS
 SG_ VhSecNImmoIndRq : 9|2@0+ (1,0) [0|3] ""  CGM_LS
 SG_ StrgColLckCmd : 11|2@0+ (1,0) [0|3] ""  CGM_LS
 SG_ DrIdDevLrnd : 0|1@0+ (1,0) [0|1] ""  CGM_LS
 SG_ IllDrIdDevDtctd : 4|1@0+ (1,0) [0|1] ""  CGM_LS
 SG_ EhnSrvEngImmStat : 3|1@0+ (1,0) [0|1] ""  CGM_LS
 SG_ ClmSysBkupFlrIndOn : 34|1@0+ (1,0) [0|1] ""  CGM_LS
 SG_ VehStatStAtv : 32|1@0+ (1,0) [0|1] ""  PEPS_LS,CGM_LS

BO_TX_BU_ 2155364352 : BSM_LS,BCM_LS;
BO_TX_BU_ 2154512384 : PTM_LS,BCM_LS;
BO_TX_BU_ 2155266048 : ECC_LS,BCM_LS;
BO_TX_BU_ 2154962944 : MSM_LS,BCM_LS;
BO_TX_BU_ 2154840064 : CGM_LS,BCM_LS;
CM_ SG_ 2154840064 CmpsCrHding "i.e., adjusted for declination zone, hysterisis, and filtering)";
CM_ SG_ 2154905600 DrId "Driver 8 changed to Unknown on 3/30/99";
BA_DEF_ SG_  "VNSigDiagnostic" ENUM  "No","Yes","DLCLS","DLCHS","DLCCE","DLCFO";
BA_DEF_ SG_  "VNSigUnused_4" ENUM  "No","Yes","DLCLS","DLCHS","DLCCE","DLCFO";
BA_DEF_ SG_  "VNSigIntermediate" ENUM  "No","Yes","DLCLS","DLCHS","DLCCE","DLCFO";
BA_DEF_ SG_  "VNSigParkedVehicle" ENUM  "No","Yes","DLCLS","DLCHS","DLCCE","DLCFO";
BA_DEF_ SG_  "VNSigRemoteDiagnostics" ENUM  "No","Yes","DLCLS","DLCHS","DLCCE","DLCFO";
BA_DEF_ SG_  "GenSigSendOnInit" ENUM  "Not Initialized","Application","Handler","DLCLS","DLCHS","DLCCE","DLCFO";
BA_DEF_ SG_  "GenSigSendType" ENUM  "not used","not used","not used","not used","not used","not used","not used","NoSigSendType","not used","not used","OnAnyChange","OnChangeIfActive","OnDelta","DLCLS","DLCHS","DLCCE","DLCFO";
BA_DEF_ SG_  "GenSigInactiveValue" INT 0 0;
BA_DEF_ SG_  "GenSigDeltaValue" INT 0 0;
BA_DEF_ SG_  "VNSigAllNodes" ENUM  "No","Yes","DLCLS","DLCHS","DLCCE","DLCFO";
BA_DEF_ SG_  "SignalType" STRING ;
BA_DEF_ SG_  "PacketOrder" INT 0 65535;
BA_DEF_ SG_  "SignalLongName" STRING ;
BA_DEF_ SG_  "GenSigStartValue" INT 0 65535;
BA_DEF_ SG_  "TxSignalSendOnInit" ENUM  "Not Initialized","Application","Handler";
BA_DEF_ BO_  "GenMsgILSupport" ENUM  "No","Yes","DLCLS","DLCHS","DLCCE","DLCFO";
BA_DEF_ BO_  "TpApplType" STRING ;
BA_DEF_ BO_  "Prio" INT 0 7;
BA_DEF_ BO_  "MessageSubnet" ENUM  "LS","MS","HS","CE","PE","HV","FO","S1","HE","LE","HE2","DLCLS","DLCHS","DLCCE","DLCFO","vector_leerstring";
BA_DEF_ BO_  "DiagState" ENUM  "No","Yes";
BA_DEF_ BO_  "GenMsgIlSupport" ENUM  "No","Yes";
BA_DEF_ BO_  "GenMsgStartDelayTime" INT 0 100000;
BA_DEF_ BO_  "GenMsgDelayTime" INT 0 100000;
BA_DEF_ BO_  "GenMsgCycleTime" INT 0 100000;
BA_DEF_ BO_  "GenMsgSendType" ENUM  "cyclicX","spontanX","cyclicIfActiveX","spontanWithDelay","cyclicAndSpontanX","cyclicAndSpontanWithDelay","spontanWithRepitition","cyclicIfActiveAndSpontanWD";
BA_DEF_ BO_  "DiagResponse" ENUM  "No","Yes";
BA_DEF_ BO_  "DiagRequest" ENUM  "No","Yes";
BA_DEF_ BO_  "NmMessage" ENUM  "No","Yes";
BA_DEF_REL_ BU_SG_REL_  "GenSigSuprvResp" ENUM  "None","Notify App","Substitute Default","DLCLS","DLCHS","DLCCE","DLCFO";
BA_DEF_REL_ BU_SG_REL_  "GenSigSuprvRespSubValue" INT 0 65535;
BA_DEF_REL_ BU_SG_REL_  "GenSigRxStartValue" STRING ;
BA_DEF_REL_ BU_SG_REL_  "GenSigVDAFailResp" ENUM  "No","Yes","DLCLS","DLCHS","DLCCE","DLCFO";
BA_DEF_REL_ BU_SG_REL_  "GenSigVDAFailComment" STRING ;
BA_DEF_REL_ BU_SG_REL_  "GenSigVBitRespComment" STRING ;
BA_DEF_REL_ BU_SG_REL_  "GenSigVBitResp" ENUM  "No","Yes","DLCLS","DLCHS","DLCCE","DLCFO";
BA_DEF_REL_ BU_SG_REL_  "GenSigSuprvRespComment" STRING ;
BA_DEF_REL_ BU_SG_REL_  "GenSigTimeoutTime" INT 0 5000;
BA_DEF_DEF_  "VNSigDiagnostic" "No";
BA_DEF_DEF_  "VNSigUnused_4" "No";
BA_DEF_DEF_  "VNSigIntermediate" "No";
BA_DEF_DEF_  "VNSigParkedVehicle" "No";
BA_DEF_DEF_  "VNSigRemoteDiagnostics" "No";
BA_DEF_DEF_  "GenSigSendOnInit" "Not Initialized";
BA_DEF_DEF_  "GenSigSendType" "NoSigSendType";
BA_DEF_DEF_  "GenSigInactiveValue" 0;
BA_DEF_DEF_  "GenSigDeltaValue" 0;
BA_DEF_DEF_  "VNSigAllNodes" "No";
BA_DEF_DEF_  "SignalType" "";
BA_DEF_DEF_  "PacketOrder" 0;
BA_DEF_DEF_  "SignalLongName" "";
BA_DEF_DEF_  "GenSigStartValue" 0;
BA_DEF_DEF_  "TxSignalSendOnInit" "Not Initialized";
BA_DEF_DEF_  "GenMsgILSupport" "Yes";
BA_DEF_DEF_  "TpApplType" "";
BA_DEF_DEF_  "Prio" 0;
BA_DEF_DEF_  "MessageSubnet" "LS";
BA_DEF_DEF_  "DiagState" "No";
BA_DEF_DEF_  "GenMsgIlSupport" "Yes";
BA_DEF_DEF_  "GenMsgStartDelayTime" 0;
BA_DEF_DEF_  "GenMsgDelayTime" 0;
BA_DEF_DEF_  "GenMsgCycleTime" 0;
BA_DEF_DEF_  "GenMsgSendType" "spontanX";
BA_DEF_DEF_  "DiagResponse" "No";
BA_DEF_DEF_  "DiagRequest" "No";
BA_DEF_DEF_  "NmMessage" "No";
BA_DEF_DEF_REL_ "GenSigSuprvResp" "None";
BA_DEF_DEF_REL_ "GenSigSuprvRespSubValue" 0;
BA_DEF_DEF_REL_ "GenSigRxStartValue" "";
BA_DEF_DEF_REL_ "GenSigVDAFailResp" "No";
BA_DEF_DEF_REL_ "GenSigVDAFailComment" "";
BA_DEF_DEF_REL_ "GenSigVBitRespComment" "";
BA_DEF_DEF_REL_ "GenSigVBitResp" "No";
BA_DEF_DEF_REL_ "GenSigSuprvRespComment" "";
BA_DEF_DEF_REL_ "GenSigTimeoutTime" 0;
BA_ "Prio" BO_ 2149761024 4;
BA_ "GenMsgStartDelayTime" BO_ 2149761024 110;
BA_ "GenMsgCycleTime" BO_ 2149761024 250;
BA_ "GenMsgSendType" BO_ 2149761024 0;
BA_ "Prio" BO_ 2151481344 4;
BA_ "GenMsgCycleTime" BO_ 2151481344 200;
BA_ "GenMsgSendType" BO_ 2151481344 0;
BA_ "Prio" BO_ 2151432192 4;
BA_ "GenMsgCycleTime" BO_ 2151432192 200;
BA_ "GenMsgSendType" BO_ 2151432192 0;
BA_ "Prio" BO_ 2155929600 4;
BA_ "GenMsgCycleTime" BO_ 2155929600 1000;
BA_ "GenMsgSendType" BO_ 2155929600 0;
BA_ "Prio" BO_ 2154807296 4;
BA_ "GenMsgDelayTime" BO_ 2154807296 100;
BA_ "Prio" BO_ 2155364352 4;
BA_ "GenMsgStartDelayTime" BO_ 2155364352 10;
BA_ "GenMsgDelayTime" BO_ 2155364352 100;
BA_ "GenMsgCycleTime" BO_ 2155364352 250;
BA_ "GenMsgSendType" BO_ 2155364352 0;
BA_ "Prio" BO_ 2155896832 4;
BA_ "GenMsgStartDelayTime" BO_ 2155896832 170;
BA_ "GenMsgCycleTime" BO_ 2155896832 500;
BA_ "GenMsgSendType" BO_ 2155896832 0;
BA_ "Prio" BO_ 2153390080 4;
BA_ "GenMsgDelayTime" BO_ 2153390080 500;
BA_ "Prio" BO_ 2155175936 4;
BA_ "GenMsgDelayTime" BO_ 2155175936 200;
BA_ "Prio" BO_ 2154078208 4;
BA_ "GenMsgDelayTime" BO_ 2154078208 200;
BA_ "Prio" BO_ 2155495424 4;
BA_ "GenMsgDelayTime" BO_ 2155495424 500;
BA_ "Prio" BO_ 2155413504 4;
BA_ "GenMsgDelayTime" BO_ 2155413504 100;
BA_ "Prio" BO_ 2150367232 4;
BA_ "GenMsgStartDelayTime" BO_ 2150367232 170;
BA_ "GenMsgCycleTime" BO_ 2150367232 300;
BA_ "GenMsgSendType" BO_ 2150367232 0;
BA_ "Prio" BO_ 2150621184 3;
BA_ "GenMsgDelayTime" BO_ 2150621184 100;
BA_ "Prio" BO_ 2151309312 4;
BA_ "GenMsgDelayTime" BO_ 2151309312 100;
BA_ "Prio" BO_ 2154061824 4;
BA_ "GenMsgDelayTime" BO_ 2154061824 100;
BA_ "Prio" BO_ 2154512384 3;
BA_ "GenMsgDelayTime" BO_ 2154512384 100;
BA_ "Prio" BO_ 2155347968 4;
BA_ "GenMsgStartDelayTime" BO_ 2155347968 180;
BA_ "GenMsgCycleTime" BO_ 2155347968 250;
BA_ "GenMsgSendType" BO_ 2155347968 0;
BA_ "Prio" BO_ 2150432768 4;
BA_ "GenMsgStartDelayTime" BO_ 2150432768 150;
BA_ "GenMsgCycleTime" BO_ 2150432768 500;
BA_ "GenMsgSendType" BO_ 2150432768 0;
BA_ "Prio" BO_ 2154938368 4;
BA_ "GenMsgDelayTime" BO_ 2154938368 100;
BA_ "Prio" BO_ 2155266048 4;
BA_ "GenMsgDelayTime" BO_ 2155266048 100;
BA_ "Prio" BO_ 2155249664 4;
BA_ "GenMsgDelayTime" BO_ 2155249664 100;
BA_ "Prio" BO_ 2155184128 4;
BA_ "GenMsgDelayTime" BO_ 2155184128 100;
BA_ "Prio" BO_ 2154921984 3;
BA_ "GenMsgDelayTime" BO_ 2154921984 100;
BA_ "Prio" BO_ 2154962944 4;
BA_ "GenMsgDelayTime" BO_ 2154962944 100;
BA_ "Prio" BO_ 2156232704 4;
BA_ "GenMsgDelayTime" BO_ 2156232704 100;
BA_ "Prio" BO_ 2154987520 4;
BA_ "GenMsgDelayTime" BO_ 2154987520 100;
BA_ "Prio" BO_ 2154840064 4;
BA_ "GenMsgDelayTime" BO_ 2154840064 100;
BA_ "Prio" BO_ 2154905600 3;
BA_ "GenMsgDelayTime" BO_ 2154905600 100;
BA_ "Prio" BO_ 2151841792 4;
BA_ "GenMsgDelayTime" BO_ 2151841792 100;
BA_ "Prio" BO_ 2154094592 4;
BA_ "GenMsgDelayTime" BO_ 2154094592 100;
BA_ "Prio" BO_ 2153979904 4;
BA_ "GenMsgDelayTime" BO_ 2153979904 100;
BA_ "Prio" BO_ 2150154240 3;
BA_ "GenMsgDelayTime" BO_ 2150154240 100;
BA_ "Prio" BO_ 2151497728 4;
BA_ "GenMsgDelayTime" BO_ 2151497728 100;
BA_ "Prio" BO_ 2151219200 4;
BA_ "GenMsgDelayTime" BO_ 2151219200 100;
BA_ "Prio" BO_ 2151235584 3;
BA_ "GenMsgDelayTime" BO_ 2151235584 100;
BA_ "VNSigAllNodes" SG_ 2149761024 PsngStPerfMdCsCrStVal 1;
BA_ "SignalType" SG_ 2149761024 PsngStPerfMdCsCrStVal "ENM";
BA_ "SignalLongName" SG_ 2149761024 PsngStPerfMdCsCrStVal "Passenger Seat Performance Mode Customization Current Setting Value";
BA_ "VNSigAllNodes" SG_ 2149761024 PsngStPerfMdCsStAvl 1;
BA_ "SignalType" SG_ 2149761024 PsngStPerfMdCsStAvl "BLN";
BA_ "SignalLongName" SG_ 2149761024 PsngStPerfMdCsStAvl "Passenger Seat Performance Mode Customization Setting Available";
BA_ "VNSigAllNodes" SG_ 2149761024 ElvtdIdlCstCrStVal 1;
BA_ "SignalType" SG_ 2149761024 ElvtdIdlCstCrStVal "ENM";
BA_ "SignalLongName" SG_ 2149761024 ElvtdIdlCstCrStVal "Elevated Idle Customization Current Setting Value";
BA_ "VNSigAllNodes" SG_ 2149761024 ElvtdIdlCstStAvl 1;
BA_ "SignalType" SG_ 2149761024 ElvtdIdlCstStAvl "BLN";
BA_ "SignalLongName" SG_ 2149761024 ElvtdIdlCstStAvl "Elevated Idle Customization Setting Available";
BA_ "VNSigAllNodes" SG_ 2149761024 TCTPIR_TnsEsClCDwT 1;
BA_ "SignalType" SG_ 2149761024 TCTPIR_TnsEsClCDwT "UNM";
BA_ "PacketOrder" SG_ 2149761024 TCTPIR_TnsEsClCDwT 3;
BA_ "SignalLongName" SG_ 2149761024 TCTPIR_TnsEsClCDwT "Transmission Clutch Thermal Protection Indication Request : Transmission Estimated Clutch Cool-down Temperature Target Display";
BA_ "VNSigAllNodes" SG_ 2149761024 TCTPIR_TnsEsClTmpD 1;
BA_ "SignalType" SG_ 2149761024 TCTPIR_TnsEsClTmpD "UNM";
BA_ "PacketOrder" SG_ 2149761024 TCTPIR_TnsEsClTmpD 2;
BA_ "SignalLongName" SG_ 2149761024 TCTPIR_TnsEsClTmpD "Transmission Clutch Thermal Protection Indication Request : Transmission Estimated Clutch Temperature Display";
BA_ "VNSigAllNodes" SG_ 2149761024 TCTPIR_DrvNotfn 1;
BA_ "SignalType" SG_ 2149761024 TCTPIR_DrvNotfn "ENM";
BA_ "PacketOrder" SG_ 2149761024 TCTPIR_DrvNotfn 1;
BA_ "SignalLongName" SG_ 2149761024 TCTPIR_DrvNotfn "Transmission Clutch Thermal Protection Indication Request : Driver Notification";
BA_ "VNSigAllNodes" SG_ 2149761024 TrlrStabAstActIO 1;
BA_ "SignalType" SG_ 2149761024 TrlrStabAstActIO "BLN";
BA_ "SignalLongName" SG_ 2149761024 TrlrStabAstActIO "Trailer Stability Assist Active Indication On";
BA_ "VNSigAllNodes" SG_ 2149761024 PerfTrcCrnExStngVal 1;
BA_ "SignalType" SG_ 2149761024 PerfTrcCrnExStngVal "ENM";
BA_ "SignalLongName" SG_ 2149761024 PerfTrcCrnExStngVal "Performance Traction Corner Exit Setting Value";
BA_ "VNSigAllNodes" SG_ 2149761024 ActVehAccelV 1;
BA_ "SignalType" SG_ 2149761024 ActVehAccelV "ENM";
BA_ "SignalLongName" SG_ 2149761024 ActVehAccelV "Actual Vehicle Acceleration Validity";
BA_ "VNSigAllNodes" SG_ 2149761024 ActVehAccel 1;
BA_ "SignalType" SG_ 2149761024 ActVehAccel "SNM";
BA_ "SignalLongName" SG_ 2149761024 ActVehAccel "Actual Vehicle Acceleration";
BA_ "GenSigSendType" SG_ 2151481344 HdUpDsplyUnblIO 10;
BA_ "VNSigAllNodes" SG_ 2151481344 HdUpDsplyUnblIO 1;
BA_ "SignalType" SG_ 2151481344 HdUpDsplyUnblIO "BLN";
BA_ "SignalLongName" SG_ 2151481344 HdUpDsplyUnblIO "Head Up Display Unavailable Indication On";
BA_ "GenSigSendType" SG_ 2151481344 FSRACCFrstRsmPrssIO 10;
BA_ "VNSigAllNodes" SG_ 2151481344 FSRACCFrstRsmPrssIO 1;
BA_ "SignalType" SG_ 2151481344 FSRACCFrstRsmPrssIO "BLN";
BA_ "SignalLongName" SG_ 2151481344 FSRACCFrstRsmPrssIO "Full Speed Range Adaptive Cruise Control First Resume Press Indication On";
BA_ "GenSigSendType" SG_ 2151481344 FrtRdrBlckdIO 10;
BA_ "VNSigAllNodes" SG_ 2151481344 FrtRdrBlckdIO 1;
BA_ "SignalType" SG_ 2151481344 FrtRdrBlckdIO "BLN";
BA_ "SignalLongName" SG_ 2151481344 FrtRdrBlckdIO "Front Radar Blocked Indication On";
BA_ "GenSigSendType" SG_ 2151481344 ShtToPrkBfExtngVehIO 10;
BA_ "VNSigAllNodes" SG_ 2151481344 ShtToPrkBfExtngVehIO 1;
BA_ "SignalType" SG_ 2151481344 ShtToPrkBfExtngVehIO "BLN";
BA_ "SignalLongName" SG_ 2151481344 ShtToPrkBfExtngVehIO "Shift to Park Before Exiting Vehicle Indication On";
BA_ "GenSigSendType" SG_ 2151481344 AutoBrkRlsIO 10;
BA_ "VNSigAllNodes" SG_ 2151481344 AutoBrkRlsIO 1;
BA_ "SignalType" SG_ 2151481344 AutoBrkRlsIO "BLN";
BA_ "SignalLongName" SG_ 2151481344 AutoBrkRlsIO "Autonomous Brake Release Indication On";
BA_ "VNSigAllNodes" SG_ 2151432192 ACCHptcStVbnRqSeqN 1;
BA_ "SignalType" SG_ 2151432192 ACCHptcStVbnRqSeqN "UNM";
BA_ "SignalLongName" SG_ 2151432192 ACCHptcStVbnRqSeqN "Adaptive Cruise Control Haptic Seat Vibration Request Sequence Number";
BA_ "VNSigAllNodes" SG_ 2151432192 ACCHptcStVbnReq 1;
BA_ "SignalType" SG_ 2151432192 ACCHptcStVbnReq "UNM";
BA_ "SignalLongName" SG_ 2151432192 ACCHptcStVbnReq "Adaptive Cruise Control Haptic Seat Vibration Request";
BA_ "VNSigAllNodes" SG_ 2155929600 DslExhFldDiagWrnIdRq 1;
BA_ "SignalType" SG_ 2155929600 DslExhFldDiagWrnIdRq "ENM";
BA_ "SignalLongName" SG_ 2155929600 DslExhFldDiagWrnIdRq "Diesel Exhaust Fluid System Diagnostic Warning Indication Request";
BA_ "VNSigAllNodes" SG_ 2155929600 DslExhFluidDistTIndcmt 1;
BA_ "SignalType" SG_ 2155929600 DslExhFluidDistTIndcmt "UNM";
BA_ "SignalLongName" SG_ 2155929600 DslExhFluidDistTIndcmt "Diesel Exhaust Fluid Distance to Inducement";
BA_ "VNSigAllNodes" SG_ 2155929600 DEFWVSL_S3SpdLmt 1;
BA_ "SignalType" SG_ 2155929600 DEFWVSL_S3SpdLmt "UNM";
BA_ "PacketOrder" SG_ 2155929600 DEFWVSL_S3SpdLmt 3;
BA_ "SignalLongName" SG_ 2155929600 DEFWVSL_S3SpdLmt "Diesel Exhaust Fluid Warning Vehicle Speed Limit : Stage 3 Vehicle Speed Limit";
BA_ "VNSigAllNodes" SG_ 2155929600 DEFWVSL_S2SpdLmt 1;
BA_ "SignalType" SG_ 2155929600 DEFWVSL_S2SpdLmt "UNM";
BA_ "PacketOrder" SG_ 2155929600 DEFWVSL_S2SpdLmt 2;
BA_ "SignalLongName" SG_ 2155929600 DEFWVSL_S2SpdLmt "Diesel Exhaust Fluid Warning Vehicle Speed Limit : Stage 2 Vehicle Speed Limit";
BA_ "VNSigAllNodes" SG_ 2155929600 DEFWVSL_S1SpdLmt 1;
BA_ "SignalType" SG_ 2155929600 DEFWVSL_S1SpdLmt "UNM";
BA_ "PacketOrder" SG_ 2155929600 DEFWVSL_S1SpdLmt 1;
BA_ "SignalLongName" SG_ 2155929600 DEFWVSL_S1SpdLmt "Diesel Exhaust Fluid Warning Vehicle Speed Limit : Stage 1 Vehicle Speed Limit";
BA_ "VNSigAllNodes" SG_ 2155929600 DslExFldTpWrngIndRq 1;
BA_ "SignalType" SG_ 2155929600 DslExFldTpWrngIndRq "ENM";
BA_ "SignalLongName" SG_ 2155929600 DslExFldTpWrngIndRq "Diesel Exhaust Fluid Tampering Warning Indication Request";
BA_ "VNSigAllNodes" SG_ 2155929600 DslExhFldQlyWrngIReq 1;
BA_ "SignalType" SG_ 2155929600 DslExhFldQlyWrngIReq "ENM";
BA_ "SignalLongName" SG_ 2155929600 DslExhFldQlyWrngIReq "Diesel Exhaust Fluid Quality Warning Indication Request";
BA_ "VNSigAllNodes" SG_ 2155929600 DslExhFldWrngIdRqER 1;
BA_ "SignalType" SG_ 2155929600 DslExhFldWrngIdRqER "ENM";
BA_ "SignalLongName" SG_ 2155929600 DslExhFldWrngIdRqER "Diesel Exhaust Fluid Level Warning Indication Request Extended Range";
BA_ "VNSigAllNodes" SG_ 2155929600 DslExFldCnWrngIndRq 1;
BA_ "SignalType" SG_ 2155929600 DslExFldCnWrngIndRq "ENM";
BA_ "SignalLongName" SG_ 2155929600 DslExFldCnWrngIndRq "Diesel Exhaust Fluid Consumption Monitoring Warning Indication Request";
BA_ "VNSigAllNodes" SG_ 2155929600 DslExNxEmWrngIndRq 1;
BA_ "SignalType" SG_ 2155929600 DslExNxEmWrngIndRq "ENM";
BA_ "SignalLongName" SG_ 2155929600 DslExNxEmWrngIndRq "Diesel Exhaust NOx Emissions Too High Warning Indication Request";
BA_ "GenSigSendType" SG_ 2154807296 ESCMHiEleclLdReqAct 10;
BA_ "VNSigAllNodes" SG_ 2154807296 ESCMHiEleclLdReqAct 1;
BA_ "SignalType" SG_ 2154807296 ESCMHiEleclLdReqAct "BLN";
BA_ "SignalLongName" SG_ 2154807296 ESCMHiEleclLdReqAct "Energy Storage Control Module High Electrical Load Request Active";
BA_ "GenSigSendType" SG_ 2154807296 EASSI_UnsdRsrvd2 10;
BA_ "VNSigAllNodes" SG_ 2154807296 EASSI_UnsdRsrvd2 1;
BA_ "SignalType" SG_ 2154807296 EASSI_UnsdRsrvd2 "BLN";
BA_ "PacketOrder" SG_ 2154807296 EASSI_UnsdRsrvd2 7;
BA_ "SignalLongName" SG_ 2154807296 EASSI_UnsdRsrvd2 "Engine Auto Start Stop Information : Unused and Reserved 2";
BA_ "GenSigSendType" SG_ 2154807296 EASSI_StlDetd 10;
BA_ "VNSigAllNodes" SG_ 2154807296 EASSI_StlDetd 1;
BA_ "SignalType" SG_ 2154807296 EASSI_StlDetd "BLN";
BA_ "PacketOrder" SG_ 2154807296 EASSI_StlDetd 5;
BA_ "SignalLongName" SG_ 2154807296 EASSI_StlDetd "Engine Auto Start Stop Information : Stall Detected";
BA_ "GenSigSendType" SG_ 2154807296 EASSI_TrqDetd 10;
BA_ "VNSigAllNodes" SG_ 2154807296 EASSI_TrqDetd 1;
BA_ "SignalType" SG_ 2154807296 EASSI_TrqDetd "BLN";
BA_ "PacketOrder" SG_ 2154807296 EASSI_TrqDetd 4;
BA_ "SignalLongName" SG_ 2154807296 EASSI_TrqDetd "Engine Auto Start Stop Information : Torque Detected";
BA_ "GenSigSendType" SG_ 2154807296 EASSI_FuelReqOn 10;
BA_ "VNSigAllNodes" SG_ 2154807296 EASSI_FuelReqOn 1;
BA_ "SignalType" SG_ 2154807296 EASSI_FuelReqOn "BLN";
BA_ "PacketOrder" SG_ 2154807296 EASSI_FuelReqOn 3;
BA_ "SignalLongName" SG_ 2154807296 EASSI_FuelReqOn "Engine Auto Start Stop Information : Fuel Requested On";
BA_ "GenSigSendType" SG_ 2154807296 EASSI_StrtTyp 10;
BA_ "VNSigAllNodes" SG_ 2154807296 EASSI_StrtTyp 1;
BA_ "SignalType" SG_ 2154807296 EASSI_StrtTyp "ENM";
BA_ "PacketOrder" SG_ 2154807296 EASSI_StrtTyp 2;
BA_ "SignalLongName" SG_ 2154807296 EASSI_StrtTyp "Engine Auto Start Stop Information : Start Type";
BA_ "GenSigSendType" SG_ 2154807296 EASSI_StrtStpSt 10;
BA_ "VNSigAllNodes" SG_ 2154807296 EASSI_StrtStpSt 1;
BA_ "SignalType" SG_ 2154807296 EASSI_StrtStpSt "ENM";
BA_ "PacketOrder" SG_ 2154807296 EASSI_StrtStpSt 1;
BA_ "SignalLongName" SG_ 2154807296 EASSI_StrtStpSt "Engine Auto Start Stop Information : Start Stop State";
BA_ "GenSigSendType" SG_ 2154807296 EASSI_TorqDetdIndet 10;
BA_ "VNSigAllNodes" SG_ 2154807296 EASSI_TorqDetdIndet 1;
BA_ "SignalType" SG_ 2154807296 EASSI_TorqDetdIndet "BLN";
BA_ "PacketOrder" SG_ 2154807296 EASSI_TorqDetdIndet 6;
BA_ "SignalLongName" SG_ 2154807296 EASSI_TorqDetdIndet "Engine Auto Start Stop Information : Torque Detected Indeterminate";
BA_ "GenSigSendType" SG_ 2154807296 EngAutoStpNotProb 10;
BA_ "VNSigAllNodes" SG_ 2154807296 EngAutoStpNotProb 1;
BA_ "SignalType" SG_ 2154807296 EngAutoStpNotProb "BLN";
BA_ "SignalLongName" SG_ 2154807296 EngAutoStpNotProb "Engine Auto Stop Not Probable";
BA_ "GenSigSendOnInit" SG_ 2154807296 AFLMnu3CstStAvl 2;
BA_ "GenSigSendType" SG_ 2154807296 AFLMnu3CstStAvl 10;
BA_ "VNSigAllNodes" SG_ 2154807296 AFLMnu3CstStAvl 1;
BA_ "SignalType" SG_ 2154807296 AFLMnu3CstStAvl "BLN";
BA_ "SignalLongName" SG_ 2154807296 AFLMnu3CstStAvl "Adaptive Forward Lighting Menu 3 Customization Setting Available";
BA_ "GenSigSendOnInit" SG_ 2154807296 AFLMnu2CstStAvl 2;
BA_ "GenSigSendType" SG_ 2154807296 AFLMnu2CstStAvl 10;
BA_ "VNSigAllNodes" SG_ 2154807296 AFLMnu2CstStAvl 1;
BA_ "SignalType" SG_ 2154807296 AFLMnu2CstStAvl "BLN";
BA_ "SignalLongName" SG_ 2154807296 AFLMnu2CstStAvl "Adaptive Forward Lighting Menu 2 Customization Setting Available";
BA_ "GenSigSendOnInit" SG_ 2154807296 AFLGPSMnu2CstStAvl 2;
BA_ "GenSigSendType" SG_ 2154807296 AFLGPSMnu2CstStAvl 10;
BA_ "VNSigAllNodes" SG_ 2154807296 AFLGPSMnu2CstStAvl 1;
BA_ "SignalType" SG_ 2154807296 AFLGPSMnu2CstStAvl "BLN";
BA_ "SignalLongName" SG_ 2154807296 AFLGPSMnu2CstStAvl "Adaptive Forward Lighting With GPS Menu 2 Customization Setting Avail";
BA_ "GenSigSendOnInit" SG_ 2154807296 AFLGPSCstStAvl 2;
BA_ "GenSigSendType" SG_ 2154807296 AFLGPSCstStAvl 10;
BA_ "VNSigAllNodes" SG_ 2154807296 AFLGPSCstStAvl 1;
BA_ "SignalType" SG_ 2154807296 AFLGPSCstStAvl "BLN";
BA_ "SignalLongName" SG_ 2154807296 AFLGPSCstStAvl "Adaptive Forward Lighting With GPS Customization Setting Available";
BA_ "GenSigSendOnInit" SG_ 2154807296 AFLGPSCstCrStVal 2;
BA_ "GenSigSendType" SG_ 2154807296 AFLGPSCstCrStVal 10;
BA_ "VNSigAllNodes" SG_ 2154807296 AFLGPSCstCrStVal 1;
BA_ "SignalType" SG_ 2154807296 AFLGPSCstCrStVal "ENM";
BA_ "SignalLongName" SG_ 2154807296 AFLGPSCstCrStVal "Adaptive Forward Lighting With GPS Customization Current Setting Value";
BA_ "GenSigSendOnInit" SG_ 2154807296 AFLCstStAvl 2;
BA_ "GenSigSendType" SG_ 2154807296 AFLCstStAvl 10;
BA_ "VNSigAllNodes" SG_ 2154807296 AFLCstStAvl 1;
BA_ "SignalType" SG_ 2154807296 AFLCstStAvl "BLN";
BA_ "SignalLongName" SG_ 2154807296 AFLCstStAvl "Adaptive Forward Lighting Customization Setting Available";
BA_ "GenSigSendOnInit" SG_ 2154807296 AFLCstCrStVal 2;
BA_ "GenSigSendType" SG_ 2154807296 AFLCstCrStVal 10;
BA_ "VNSigAllNodes" SG_ 2154807296 AFLCstCrStVal 1;
BA_ "SignalType" SG_ 2154807296 AFLCstCrStVal "ENM";
BA_ "SignalLongName" SG_ 2154807296 AFLCstCrStVal "Adaptive Forward Lighting Customization Current Setting Value";
BA_ "GenSigSendOnInit" SG_ 2155364352 CstmrUsblSOCV 1;
BA_ "GenSigSendType" SG_ 2155364352 CstmrUsblSOCV 10;
BA_ "VNSigAllNodes" SG_ 2155364352 CstmrUsblSOCV 1;
BA_ "SignalType" SG_ 2155364352 CstmrUsblSOCV "ENM";
BA_ "SignalLongName" SG_ 2155364352 CstmrUsblSOCV "Customer Usable State of Charge Validity";
BA_ "GenSigSendOnInit" SG_ 2155364352 InstDrvEff 1;
BA_ "GenSigSendType" SG_ 2155364352 InstDrvEff 12;
BA_ "GenSigDeltaValue" SG_ 2155364352 InstDrvEff 1;
BA_ "VNSigAllNodes" SG_ 2155364352 InstDrvEff 1;
BA_ "SignalType" SG_ 2155364352 InstDrvEff "SNM";
BA_ "SignalLongName" SG_ 2155364352 InstDrvEff "Instantaneous Drive Efficiency";
BA_ "GenSigSendOnInit" SG_ 2155364352 BattCntrlPrcssrVDA 1;
BA_ "GenSigSendType" SG_ 2155364352 BattCntrlPrcssrVDA 10;
BA_ "VNSigAllNodes" SG_ 2155364352 BattCntrlPrcssrVDA 1;
BA_ "SignalType" SG_ 2155364352 BattCntrlPrcssrVDA "ENM";
BA_ "SignalLongName" SG_ 2155364352 BattCntrlPrcssrVDA "Battery Control Processor Virtual Device Availability";
BA_ "GenSigStartValue" SG_ 2155364352 BattCntrlPrcssrVDA 1;
BA_ "GenSigSendOnInit" SG_ 2155364352 JmpStrtStat 1;
BA_ "GenSigSendType" SG_ 2155364352 JmpStrtStat 10;
BA_ "VNSigAllNodes" SG_ 2155364352 JmpStrtStat 1;
BA_ "SignalType" SG_ 2155364352 JmpStrtStat "ENM";
BA_ "SignalLongName" SG_ 2155364352 JmpStrtStat "Jump Start Status";
BA_ "GenSigSendOnInit" SG_ 2155364352 CstmrUsblSOC 1;
BA_ "GenSigSendType" SG_ 2155364352 CstmrUsblSOC 12;
BA_ "GenSigDeltaValue" SG_ 2155364352 CstmrUsblSOC 1;
BA_ "VNSigAllNodes" SG_ 2155364352 CstmrUsblSOC 1;
BA_ "SignalType" SG_ 2155364352 CstmrUsblSOC "UNM";
BA_ "SignalLongName" SG_ 2155364352 CstmrUsblSOC "Customer Usable State of Charge";
BA_ "GenSigSendOnInit" SG_ 2155364352 SvcHybridSysIO 1;
BA_ "GenSigSendType" SG_ 2155364352 SvcHybridSysIO 10;
BA_ "VNSigAllNodes" SG_ 2155364352 SvcHybridSysIO 1;
BA_ "SignalType" SG_ 2155364352 SvcHybridSysIO "BLN";
BA_ "SignalLongName" SG_ 2155364352 SvcHybridSysIO "Service Hybrid System Indication On";
BA_ "GenSigSendOnInit" SG_ 2155364352 HybMdDisp 1;
BA_ "GenSigSendType" SG_ 2155364352 HybMdDisp 10;
BA_ "VNSigAllNodes" SG_ 2155364352 HybMdDisp 1;
BA_ "SignalType" SG_ 2155364352 HybMdDisp "ENM";
BA_ "SignalLongName" SG_ 2155364352 HybMdDisp "Hybrid Mode Display";
BA_ "GenSigSendOnInit" SG_ 2155364352 ClntCrcFlwRtEst 1;
BA_ "GenSigSendType" SG_ 2155364352 ClntCrcFlwRtEst 12;
BA_ "GenSigDeltaValue" SG_ 2155364352 ClntCrcFlwRtEst 1;
BA_ "VNSigAllNodes" SG_ 2155364352 ClntCrcFlwRtEst 1;
BA_ "SignalType" SG_ 2155364352 ClntCrcFlwRtEst "UNM";
BA_ "SignalLongName" SG_ 2155364352 ClntCrcFlwRtEst "Coolant Circulation Flow Rate Estimated";
BA_ "VNSigAllNodes" SG_ 2155896832 AltFuelPHeatAct 1;
BA_ "SignalType" SG_ 2155896832 AltFuelPHeatAct "BLN";
BA_ "SignalLongName" SG_ 2155896832 AltFuelPHeatAct "Alternative Fuel Pre-heating Active";
BA_ "VNSigAllNodes" SG_ 2155896832 AltFuelMdReqDndIO 1;
BA_ "SignalType" SG_ 2155896832 AltFuelMdReqDndIO "BLN";
BA_ "SignalLongName" SG_ 2155896832 AltFuelMdReqDndIO "Alternative Fuel Mode Request Denied Indication On";
BA_ "VNSigAllNodes" SG_ 2155896832 AltFuelLvlLo 1;
BA_ "SignalType" SG_ 2155896832 AltFuelLvlLo "BLN";
BA_ "SignalLongName" SG_ 2155896832 AltFuelLvlLo "Alternative Fuel Level Low";
BA_ "VNSigAllNodes" SG_ 2155896832 AltFuelAccWrnngAct 1;
BA_ "SignalType" SG_ 2155896832 AltFuelAccWrnngAct "BLN";
BA_ "SignalLongName" SG_ 2155896832 AltFuelAccWrnngAct "Alternative Fuel Acceleration Warning Active";
BA_ "VNSigAllNodes" SG_ 2155896832 FuelAlcoholCompV 1;
BA_ "SignalType" SG_ 2155896832 FuelAlcoholCompV "ENM";
BA_ "SignalLongName" SG_ 2155896832 FuelAlcoholCompV "Fuel Alcohol Composition Validity";
BA_ "VNSigAllNodes" SG_ 2155896832 FuelAlchlCompAdptnPrg 1;
BA_ "SignalType" SG_ 2155896832 FuelAlchlCompAdptnPrg "BLN";
BA_ "SignalLongName" SG_ 2155896832 FuelAlchlCompAdptnPrg "Fuel Alcohol Composition Adaptation in Progress";
BA_ "VNSigAllNodes" SG_ 2155896832 FuelAlcoholComp 1;
BA_ "SignalType" SG_ 2155896832 FuelAlcoholComp "UNM";
BA_ "SignalLongName" SG_ 2155896832 FuelAlcoholComp "Fuel Alcohol Composition";
BA_ "VNSigAllNodes" SG_ 2155896832 FuelMdStat 1;
BA_ "SignalType" SG_ 2155896832 FuelMdStat "ENM";
BA_ "SignalLongName" SG_ 2155896832 FuelMdStat "Fuel Mode Status";
BA_ "VNSigAllNodes" SG_ 2155896832 FuelTotCapTnk2 1;
BA_ "SignalType" SG_ 2155896832 FuelTotCapTnk2 "UNM";
BA_ "SignalLongName" SG_ 2155896832 FuelTotCapTnk2 "Fuel Total Capacity Tank 2";
BA_ "VNSigAllNodes" SG_ 2155896832 FlLvlTank2PctV 1;
BA_ "SignalType" SG_ 2155896832 FlLvlTank2PctV "ENM";
BA_ "SignalLongName" SG_ 2155896832 FlLvlTank2PctV "Fuel Level Tank 2 Percent Validity";
BA_ "VNSigAllNodes" SG_ 2155896832 FlLvlTank2Pct 1;
BA_ "SignalType" SG_ 2155896832 FlLvlTank2Pct "UNM";
BA_ "SignalLongName" SG_ 2155896832 FlLvlTank2Pct "Fuel Level Tank 2 Percent";
BA_ "GenSigSendType" SG_ 2153390080 RrClosOpenSwAct_2D1V 10;
BA_ "VNSigAllNodes" SG_ 2153390080 RrClosOpenSwAct_2D1V 1;
BA_ "SignalType" SG_ 2153390080 RrClosOpenSwAct_2D1V "ENM";
BA_ "SignalLongName" SG_ 2153390080 RrClosOpenSwAct_2D1V "Rear Closure Open Switch Active 2D1 Validity";
BA_ "GenSigSendOnInit" SG_ 2153390080 RrClosOpenSwAct_2D1 2;
BA_ "GenSigSendType" SG_ 2153390080 RrClosOpenSwAct_2D1 10;
BA_ "VNSigAllNodes" SG_ 2153390080 RrClosOpenSwAct_2D1 1;
BA_ "SignalType" SG_ 2153390080 RrClosOpenSwAct_2D1 "BLN";
BA_ "SignalLongName" SG_ 2153390080 RrClosOpenSwAct_2D1 "Rear Closure Open Switch Active 2D1";
BA_ "GenSigSendType" SG_ 2155175936 AdptCrsLKALDWSwAct 10;
BA_ "VNSigAllNodes" SG_ 2155175936 AdptCrsLKALDWSwAct 1;
BA_ "SignalType" SG_ 2155175936 AdptCrsLKALDWSwAct "BLN";
BA_ "SignalLongName" SG_ 2155175936 AdptCrsLKALDWSwAct "Adaptive Cruise LKA LDW Switch Active";
BA_ "GenSigSendType" SG_ 2155175936 AdptCrsGapSwAct 10;
BA_ "VNSigAllNodes" SG_ 2155175936 AdptCrsGapSwAct 1;
BA_ "SignalType" SG_ 2155175936 AdptCrsGapSwAct "ENM";
BA_ "SignalLongName" SG_ 2155175936 AdptCrsGapSwAct "Adaptive Cruise Control Gap Switch Activation";
BA_ "GenSigSendOnInit" SG_ 2154078208 RRWndPosStat 2;
BA_ "GenSigSendType" SG_ 2154078208 RRWndPosStat 10;
BA_ "VNSigAllNodes" SG_ 2154078208 RRWndPosStat 1;
BA_ "SignalType" SG_ 2154078208 RRWndPosStat "ENM";
BA_ "SignalLongName" SG_ 2154078208 RRWndPosStat "Right Rear Window Position Status";
BA_ "GenSigSendOnInit" SG_ 2154078208 PsWndPosStat 2;
BA_ "GenSigSendType" SG_ 2154078208 PsWndPosStat 10;
BA_ "VNSigAllNodes" SG_ 2154078208 PsWndPosStat 1;
BA_ "SignalType" SG_ 2154078208 PsWndPosStat "ENM";
BA_ "SignalLongName" SG_ 2154078208 PsWndPosStat "Passenger Window Position Status";
BA_ "GenSigSendOnInit" SG_ 2154078208 LRWndPosStat 2;
BA_ "GenSigSendType" SG_ 2154078208 LRWndPosStat 10;
BA_ "VNSigAllNodes" SG_ 2154078208 LRWndPosStat 1;
BA_ "SignalType" SG_ 2154078208 LRWndPosStat "ENM";
BA_ "SignalLongName" SG_ 2154078208 LRWndPosStat "Left Rear Window Position Status";
BA_ "GenSigSendOnInit" SG_ 2154078208 DrvWndPosStat 2;
BA_ "GenSigSendType" SG_ 2154078208 DrvWndPosStat 10;
BA_ "VNSigAllNodes" SG_ 2154078208 DrvWndPosStat 1;
BA_ "SignalType" SG_ 2154078208 DrvWndPosStat "ENM";
BA_ "SignalLongName" SG_ 2154078208 DrvWndPosStat "Driver Window Position Status";
BA_ "GenSigSendType" SG_ 2155495424 RmStrHtdStEnRq 10;
BA_ "VNSigAllNodes" SG_ 2155495424 RmStrHtdStEnRq 1;
BA_ "SignalType" SG_ 2155495424 RmStrHtdStEnRq "ENM";
BA_ "SignalLongName" SG_ 2155495424 RmStrHtdStEnRq "Remote Start Heated Seat Enable Request";
BA_ "GenSigSendType" SG_ 2155495424 RmStrCldStEnReq 10;
BA_ "VNSigAllNodes" SG_ 2155495424 RmStrCldStEnReq 1;
BA_ "SignalType" SG_ 2155495424 RmStrCldStEnReq "ENM";
BA_ "SignalLongName" SG_ 2155495424 RmStrCldStEnReq "Remote Start Cooled Seat Enable Request";
BA_ "GenSigSendType" SG_ 2155413504 PsvLckngReqd 10;
BA_ "VNSigAllNodes" SG_ 2155413504 PsvLckngReqd 1;
BA_ "SignalType" SG_ 2155413504 PsvLckngReqd "BLN";
BA_ "SignalLongName" SG_ 2155413504 PsvLckngReqd "Passive Locking Requested";
BA_ "GenSigSendType" SG_ 2155413504 PsvApprchVehId 12;
BA_ "GenSigDeltaValue" SG_ 2155413504 PsvApprchVehId 1;
BA_ "VNSigAllNodes" SG_ 2155413504 PsvApprchVehId 1;
BA_ "SignalType" SG_ 2155413504 PsvApprchVehId "UNM";
BA_ "SignalLongName" SG_ 2155413504 PsvApprchVehId "Passive Approach Vehicle Identifier";
BA_ "GenSigSendType" SG_ 2155413504 DrvrDrKeyCylUlkSwAct 10;
BA_ "VNSigAllNodes" SG_ 2155413504 DrvrDrKeyCylUlkSwAct 1;
BA_ "SignalType" SG_ 2155413504 DrvrDrKeyCylUlkSwAct "BLN";
BA_ "SignalLongName" SG_ 2155413504 DrvrDrKeyCylUlkSwAct "Driver Door Key Cylinder Unlock Switch Active";
BA_ "GenSigSendType" SG_ 2155413504 DrvrDrKeyCylUlkSwActV 10;
BA_ "VNSigAllNodes" SG_ 2155413504 DrvrDrKeyCylUlkSwActV 1;
BA_ "SignalType" SG_ 2155413504 DrvrDrKeyCylUlkSwActV "ENM";
BA_ "SignalLongName" SG_ 2155413504 DrvrDrKeyCylUlkSwActV "Driver Door Key Cylinder Unlock Switch Active Validity";
BA_ "GenSigSendOnInit" SG_ 2150367232 LrnEnvIdSt 2;
BA_ "VNSigAllNodes" SG_ 2150367232 LrnEnvIdSt 1;
BA_ "SignalType" SG_ 2150367232 LrnEnvIdSt "ENM";
BA_ "SignalLongName" SG_ 2150367232 LrnEnvIdSt "Learn Environment Identification Status";
BA_ "GenSigSendOnInit" SG_ 2150367232 LrnEnvId 2;
BA_ "VNSigAllNodes" SG_ 2150367232 LrnEnvId 1;
BA_ "SignalType" SG_ 2150367232 LrnEnvId "UNM";
BA_ "SignalLongName" SG_ 2150367232 LrnEnvId "Learn Environment Identification";
BA_ "GenSigSendOnInit" SG_ 2150367232 ImoId 2;
BA_ "VNSigAllNodes" SG_ 2150367232 ImoId 1;
BA_ "SignalType" SG_ 2150367232 ImoId "UNM";
BA_ "SignalLongName" SG_ 2150367232 ImoId "Immobilizer Identifier";
BA_ "GenSigSendOnInit" SG_ 2150367232 ImoIdSt 2;
BA_ "VNSigAllNodes" SG_ 2150367232 ImoIdSt 1;
BA_ "SignalType" SG_ 2150367232 ImoIdSt "ENM";
BA_ "SignalLongName" SG_ 2150367232 ImoIdSt "Immobilizer Identifier Status";
BA_ "GenSigSendType" SG_ 2150621184 KSARUID8 10;
BA_ "VNSigAllNodes" SG_ 2150621184 KSARUID8 1;
BA_ "SignalType" SG_ 2150621184 KSARUID8 "ENM";
BA_ "PacketOrder" SG_ 2150621184 KSARUID8 8;
BA_ "SignalLongName" SG_ 2150621184 KSARUID8 "Keyless Start Authentification Result : UserIdentity8";
BA_ "GenSigSendType" SG_ 2150621184 KSARUID7 10;
BA_ "VNSigAllNodes" SG_ 2150621184 KSARUID7 1;
BA_ "SignalType" SG_ 2150621184 KSARUID7 "ENM";
BA_ "PacketOrder" SG_ 2150621184 KSARUID7 7;
BA_ "SignalLongName" SG_ 2150621184 KSARUID7 "Keyless Start Authentification Result : UserIdentity7";
BA_ "GenSigSendType" SG_ 2150621184 KSARUID6 10;
BA_ "VNSigAllNodes" SG_ 2150621184 KSARUID6 1;
BA_ "SignalType" SG_ 2150621184 KSARUID6 "ENM";
BA_ "PacketOrder" SG_ 2150621184 KSARUID6 6;
BA_ "SignalLongName" SG_ 2150621184 KSARUID6 "Keyless Start Authentification Result : UserIdentity6";
BA_ "GenSigSendType" SG_ 2150621184 KSARUID5 10;
BA_ "VNSigAllNodes" SG_ 2150621184 KSARUID5 1;
BA_ "SignalType" SG_ 2150621184 KSARUID5 "ENM";
BA_ "PacketOrder" SG_ 2150621184 KSARUID5 5;
BA_ "SignalLongName" SG_ 2150621184 KSARUID5 "Keyless Start Authentification Result : UserIdentity5";
BA_ "GenSigSendType" SG_ 2150621184 KSARUID4 10;
BA_ "VNSigAllNodes" SG_ 2150621184 KSARUID4 1;
BA_ "SignalType" SG_ 2150621184 KSARUID4 "ENM";
BA_ "PacketOrder" SG_ 2150621184 KSARUID4 4;
BA_ "SignalLongName" SG_ 2150621184 KSARUID4 "Keyless Start Authentification Result : UserIdentity4";
BA_ "GenSigSendType" SG_ 2150621184 KSARUID3 10;
BA_ "VNSigAllNodes" SG_ 2150621184 KSARUID3 1;
BA_ "SignalType" SG_ 2150621184 KSARUID3 "ENM";
BA_ "PacketOrder" SG_ 2150621184 KSARUID3 3;
BA_ "SignalLongName" SG_ 2150621184 KSARUID3 "Keyless Start Authentification Result : UserIdentity3";
BA_ "GenSigSendType" SG_ 2150621184 KSARUID2 10;
BA_ "VNSigAllNodes" SG_ 2150621184 KSARUID2 1;
BA_ "SignalType" SG_ 2150621184 KSARUID2 "ENM";
BA_ "PacketOrder" SG_ 2150621184 KSARUID2 2;
BA_ "SignalLongName" SG_ 2150621184 KSARUID2 "Keyless Start Authentification Result : UserIdentity2";
BA_ "GenSigSendType" SG_ 2150621184 KSARUID1 10;
BA_ "VNSigAllNodes" SG_ 2150621184 KSARUID1 1;
BA_ "SignalType" SG_ 2150621184 KSARUID1 "ENM";
BA_ "PacketOrder" SG_ 2150621184 KSARUID1 1;
BA_ "SignalLongName" SG_ 2150621184 KSARUID1 "Keyless Start Authentification Result : UserIdentity1";
BA_ "GenSigSendOnInit" SG_ 2151309312 InflRestId 2;
BA_ "GenSigSendType" SG_ 2151309312 InflRestId 10;
BA_ "VNSigAllNodes" SG_ 2151309312 InflRestId 1;
BA_ "SignalType" SG_ 2151309312 InflRestId "BCD";
BA_ "SignalLongName" SG_ 2151309312 InflRestId "Inflatable Restraints Keying Identifier";
BA_ "GenSigSendType" SG_ 2154061824 WndOprAlwd 10;
BA_ "VNSigAllNodes" SG_ 2154061824 WndOprAlwd 1;
BA_ "SignalType" SG_ 2154061824 WndOprAlwd "BLN";
BA_ "SignalLongName" SG_ 2154061824 WndOprAlwd "Window Operation Allowed";
BA_ "GenSigSendType" SG_ 2154061824 RrDrUnlckIO 10;
BA_ "VNSigAllNodes" SG_ 2154061824 RrDrUnlckIO 1;
BA_ "SignalType" SG_ 2154061824 RrDrUnlckIO "BLN";
BA_ "SignalLongName" SG_ 2154061824 RrDrUnlckIO "Rear Door Unlock Indication On";
BA_ "GenSigSendType" SG_ 2154061824 RmtWndMvmntAtv 10;
BA_ "VNSigAllNodes" SG_ 2154061824 RmtWndMvmntAtv 1;
BA_ "SignalType" SG_ 2154061824 RmtWndMvmntAtv "BLN";
BA_ "SignalLongName" SG_ 2154061824 RmtWndMvmntAtv "Remote Window Movement Active";
BA_ "GenSigSendType" SG_ 2154061824 RRWndNtNrmIndOn 10;
BA_ "VNSigAllNodes" SG_ 2154061824 RRWndNtNrmIndOn 1;
BA_ "SignalType" SG_ 2154061824 RRWndNtNrmIndOn "BLN";
BA_ "SignalLongName" SG_ 2154061824 RRWndNtNrmIndOn "Rear Right Window Not Normalized Indication On";
BA_ "GenSigSendType" SG_ 2154061824 RLWndNtNrmIndOn 10;
BA_ "VNSigAllNodes" SG_ 2154061824 RLWndNtNrmIndOn 1;
BA_ "SignalType" SG_ 2154061824 RLWndNtNrmIndOn "BLN";
BA_ "SignalLongName" SG_ 2154061824 RLWndNtNrmIndOn "Rear Left Window Not Normalized Indication On";
BA_ "GenSigSendOnInit" SG_ 2154061824 DrWndNtNrmIndOn 2;
BA_ "GenSigSendType" SG_ 2154061824 DrWndNtNrmIndOn 10;
BA_ "VNSigAllNodes" SG_ 2154061824 DrWndNtNrmIndOn 1;
BA_ "SignalType" SG_ 2154061824 DrWndNtNrmIndOn "BLN";
BA_ "SignalLongName" SG_ 2154061824 DrWndNtNrmIndOn "Driver Window Not Normalized Indication On";
BA_ "GenSigSendType" SG_ 2154061824 PsWndNtNrmIndOn 10;
BA_ "VNSigAllNodes" SG_ 2154061824 PsWndNtNrmIndOn 1;
BA_ "SignalType" SG_ 2154061824 PsWndNtNrmIndOn "BLN";
BA_ "SignalLongName" SG_ 2154061824 PsWndNtNrmIndOn "Passenger Window Not Normalized Indication On";
BA_ "GenSigSendOnInit" SG_ 2154512384 RrClosRelSwActV 1;
BA_ "GenSigSendType" SG_ 2154512384 RrClosRelSwActV 10;
BA_ "VNSigAllNodes" SG_ 2154512384 RrClosRelSwActV 1;
BA_ "SignalType" SG_ 2154512384 RrClosRelSwActV "ENM";
BA_ "SignalLongName" SG_ 2154512384 RrClosRelSwActV "Rear Closure Release Switch Active Validity";
BA_ "GenSigSendOnInit" SG_ 2154512384 RrClosRelSwAct 1;
BA_ "GenSigSendType" SG_ 2154512384 RrClosRelSwAct 10;
BA_ "VNSigAllNodes" SG_ 2154512384 RrClosRelSwAct 1;
BA_ "SignalType" SG_ 2154512384 RrClosRelSwAct "BLN";
BA_ "SignalLongName" SG_ 2154512384 RrClosRelSwAct "Rear Closure Release Switch Active";
BA_ "VNSigAllNodes" SG_ 2155347968 DrvrStPerfMdCsCrStVal 1;
BA_ "SignalType" SG_ 2155347968 DrvrStPerfMdCsCrStVal "ENM";
BA_ "SignalLongName" SG_ 2155347968 DrvrStPerfMdCsCrStVal "Driver Seat Performance Mode Customization Current Setting Value";
BA_ "VNSigAllNodes" SG_ 2155347968 DrvrStPerfMdCsStAvl 1;
BA_ "SignalType" SG_ 2155347968 DrvrStPerfMdCsStAvl "BLN";
BA_ "SignalLongName" SG_ 2155347968 DrvrStPerfMdCsStAvl "Driver Seat Performance Mode Customization Setting Available";
BA_ "VNSigAllNodes" SG_ 2155347968 ACCPerfMdCsCrStVal 1;
BA_ "SignalType" SG_ 2155347968 ACCPerfMdCsCrStVal "ENM";
BA_ "SignalLongName" SG_ 2155347968 ACCPerfMdCsCrStVal "Adaptive Cruise Control Performance Mode Customization Current Setting Value";
BA_ "VNSigAllNodes" SG_ 2155347968 ACCPerfMdCsStAvl 1;
BA_ "SignalType" SG_ 2155347968 ACCPerfMdCsStAvl "BLN";
BA_ "SignalLongName" SG_ 2155347968 ACCPerfMdCsStAvl "Adaptive Cruise Control Performance Mode Customization Setting Available";
BA_ "VNSigAllNodes" SG_ 2155347968 VehRollAngleV 1;
BA_ "SignalType" SG_ 2155347968 VehRollAngleV "ENM";
BA_ "SignalLongName" SG_ 2155347968 VehRollAngleV "Vehicle Roll Angle Validity";
BA_ "VNSigAllNodes" SG_ 2155347968 VehRollAngle 1;
BA_ "SignalType" SG_ 2155347968 VehRollAngle "UNM";
BA_ "SignalLongName" SG_ 2155347968 VehRollAngle "Vehicle Roll Angle";
BA_ "VNSigAllNodes" SG_ 2155347968 ActVbnCtrlMlfIO 1;
BA_ "SignalType" SG_ 2155347968 ActVbnCtrlMlfIO "BLN";
BA_ "SignalLongName" SG_ 2155347968 ActVbnCtrlMlfIO "Active Vibration Control Malfunction Indication On";
BA_ "VNSigAllNodes" SG_ 2155347968 HillDesCtrlRedVehSpIO 1;
BA_ "SignalType" SG_ 2155347968 HillDesCtrlRedVehSpIO "BLN";
BA_ "SignalLongName" SG_ 2155347968 HillDesCtrlRedVehSpIO "Hill Descent Control Reduce Vehicle Speed Indication On";
BA_ "VNSigAllNodes" SG_ 2155347968 FourWhlDrvIndReq 1;
BA_ "SignalType" SG_ 2155347968 FourWhlDrvIndReq "ENM";
BA_ "SignalLongName" SG_ 2155347968 FourWhlDrvIndReq "Four Wheel Drive Indication Request";
BA_ "VNSigAllNodes" SG_ 2155347968 PedtrnProtVDA 1;
BA_ "SignalType" SG_ 2155347968 PedtrnProtVDA "ENM";
BA_ "SignalLongName" SG_ 2155347968 PedtrnProtVDA "Pedestrian Protection Virtual Device Availability";
BA_ "GenSigStartValue" SG_ 2155347968 PedtrnProtVDA 1;
BA_ "VNSigAllNodes" SG_ 2155347968 EngRecDwnshftIO 1;
BA_ "SignalType" SG_ 2155347968 EngRecDwnshftIO "BLN";
BA_ "SignalLongName" SG_ 2155347968 EngRecDwnshftIO "Engine Recommended Downshift Indication On";
BA_ "VNSigAllNodes" SG_ 2155347968 AppCltchAutSrtIO 1;
BA_ "SignalType" SG_ 2155347968 AppCltchAutSrtIO "BLN";
BA_ "SignalLongName" SG_ 2155347968 AppCltchAutSrtIO "Apply Clutch For Automatic Start Indication On";
BA_ "VNSigAllNodes" SG_ 2155347968 CPSUnblIO 1;
BA_ "SignalType" SG_ 2155347968 CPSUnblIO "BLN";
BA_ "SignalLongName" SG_ 2155347968 CPSUnblIO "Collision Preparation System Unavailable Indication On";
BA_ "VNSigAllNodes" SG_ 2155347968 StBltTgtSetAvl 1;
BA_ "SignalType" SG_ 2155347968 StBltTgtSetAvl "BLN";
BA_ "SignalLongName" SG_ 2155347968 StBltTgtSetAvl "Seat Belt Tightening Settings Available";
BA_ "VNSigAllNodes" SG_ 2155347968 StBltTgtCrtSetVal 1;
BA_ "SignalType" SG_ 2155347968 StBltTgtCrtSetVal "ENM";
BA_ "SignalLongName" SG_ 2155347968 StBltTgtCrtSetVal "Seat Belt Tightening Current Setting Value";
BA_ "VNSigAllNodes" SG_ 2155347968 PedtrnProtSysDisbld 1;
BA_ "SignalType" SG_ 2155347968 PedtrnProtSysDisbld "BLN";
BA_ "SignalLongName" SG_ 2155347968 PedtrnProtSysDisbld "Pedestrian Protection System Disabled";
BA_ "VNSigAllNodes" SG_ 2155347968 PedtrnProtSysDpl 1;
BA_ "SignalType" SG_ 2155347968 PedtrnProtSysDpl "BLN";
BA_ "SignalLongName" SG_ 2155347968 PedtrnProtSysDpl "Pedestrian Protection System Deployed";
BA_ "VNSigAllNodes" SG_ 2155347968 SrvPedtrnProtSysIO 1;
BA_ "SignalType" SG_ 2155347968 SrvPedtrnProtSysIO "BLN";
BA_ "SignalLongName" SG_ 2155347968 SrvPedtrnProtSysIO "Service Pedestrian Protection System Indication On";
BA_ "VNSigAllNodes" SG_ 2155347968 CPSOffIO 1;
BA_ "SignalType" SG_ 2155347968 CPSOffIO "BLN";
BA_ "SignalLongName" SG_ 2155347968 CPSOffIO "Collision Preparation System Off Indication On";
BA_ "VNSigAllNodes" SG_ 2155347968 SecAxlTmpInhIO 1;
BA_ "SignalType" SG_ 2155347968 SecAxlTmpInhIO "BLN";
BA_ "SignalLongName" SG_ 2155347968 SecAxlTmpInhIO "Secondary Axle Temporary Inhibit Indication On";
BA_ "VNSigAllNodes" SG_ 2155347968 CPSFldIO 1;
BA_ "SignalType" SG_ 2155347968 CPSFldIO "BLN";
BA_ "SignalLongName" SG_ 2155347968 CPSFldIO "Collision Preparation System Failed Indication On";
BA_ "VNSigAllNodes" SG_ 2155347968 CPSAlrtOnlIO 1;
BA_ "SignalType" SG_ 2155347968 CPSAlrtOnlIO "BLN";
BA_ "SignalLongName" SG_ 2155347968 CPSAlrtOnlIO "Collision Preparation System Alert Only Indication On";
BA_ "VNSigAllNodes" SG_ 2155347968 RrAxlTmpInhIO 1;
BA_ "SignalType" SG_ 2155347968 RrAxlTmpInhIO "BLN";
BA_ "SignalLongName" SG_ 2155347968 RrAxlTmpInhIO "Rear Axle Temporary Inhibit Indication On";
BA_ "VNSigAllNodes" SG_ 2155347968 TirePrsLowIO 1;
BA_ "SignalType" SG_ 2155347968 TirePrsLowIO "BLN";
BA_ "SignalLongName" SG_ 2155347968 TirePrsLowIO "Tire Pressure Low Indication On";
BA_ "VNSigAllNodes" SG_ 2155347968 EPBSysStatIndReq 1;
BA_ "SignalType" SG_ 2155347968 EPBSysStatIndReq "ENM";
BA_ "SignalLongName" SG_ 2155347968 EPBSysStatIndReq "Electric Park Brake System Status Indication Request";
BA_ "VNSigAllNodes" SG_ 2155347968 EngOilStrvtnIO 1;
BA_ "SignalType" SG_ 2155347968 EngOilStrvtnIO "BLN";
BA_ "SignalLongName" SG_ 2155347968 EngOilStrvtnIO "Engine Oil Starvation Indication On";
BA_ "VNSigAllNodes" SG_ 2155347968 SrvSuspSysIO 1;
BA_ "SignalType" SG_ 2155347968 SrvSuspSysIO "BLN";
BA_ "SignalLongName" SG_ 2155347968 SrvSuspSysIO "Service Suspension System Indication On";
BA_ "VNSigAllNodes" SG_ 2155347968 ServAdpCrsCtrlIndOn 1;
BA_ "SignalType" SG_ 2155347968 ServAdpCrsCtrlIndOn "BLN";
BA_ "SignalLongName" SG_ 2155347968 ServAdpCrsCtrlIndOn "Service Adaptive Cruise Control Indication On";
BA_ "VNSigAllNodes" SG_ 2155347968 EngRecmndUpshftIO 1;
BA_ "SignalType" SG_ 2155347968 EngRecmndUpshftIO "BLN";
BA_ "SignalLongName" SG_ 2155347968 EngRecmndUpshftIO "Engine Recommended Upshift Indication On";
BA_ "VNSigAllNodes" SG_ 2155347968 BrkSysMalFuncIndOn 1;
BA_ "SignalType" SG_ 2155347968 BrkSysMalFuncIndOn "BLN";
BA_ "SignalLongName" SG_ 2155347968 BrkSysMalFuncIndOn "Brake System Malfunction Indication On";
BA_ "VNSigAllNodes" SG_ 2155347968 SecAxlNonEmMalfIO 1;
BA_ "SignalType" SG_ 2155347968 SecAxlNonEmMalfIO "BLN";
BA_ "SignalLongName" SG_ 2155347968 SecAxlNonEmMalfIO "Secondary Axle Non-emissions Malf Ind On";
BA_ "VNSigAllNodes" SG_ 2155347968 BrkFldLvlLw 1;
BA_ "SignalType" SG_ 2155347968 BrkFldLvlLw "BLN";
BA_ "SignalLongName" SG_ 2155347968 BrkFldLvlLw "Brake Fluid Level Low";
BA_ "VNSigAllNodes" SG_ 2155347968 ACCUnavlbleDTWthrIO 1;
BA_ "SignalType" SG_ 2155347968 ACCUnavlbleDTWthrIO "BLN";
BA_ "SignalLongName" SG_ 2155347968 ACCUnavlbleDTWthrIO "Adaptive Cruise Unavailable Due To Weather Indication On";
BA_ "VNSigAllNodes" SG_ 2155347968 ACCTmpUnavlbleIO 1;
BA_ "SignalType" SG_ 2155347968 ACCTmpUnavlbleIO "BLN";
BA_ "SignalLongName" SG_ 2155347968 ACCTmpUnavlbleIO "Adaptive Cruise Control Temporarily Unavailable Indication On";
BA_ "VNSigAllNodes" SG_ 2155347968 EngEmsRelMalfIndReq 1;
BA_ "SignalType" SG_ 2155347968 EngEmsRelMalfIndReq "ENM";
BA_ "SignalLongName" SG_ 2155347968 EngEmsRelMalfIndReq "Engine Emissions Related Malfunction Indication Request";
BA_ "VNSigAllNodes" SG_ 2155347968 DrShftCntrlReqDndIO 1;
BA_ "SignalType" SG_ 2155347968 DrShftCntrlReqDndIO "BLN";
BA_ "SignalLongName" SG_ 2155347968 DrShftCntrlReqDndIO "Driver Shift Control Request Denied Indication On";
BA_ "VNSigAllNodes" SG_ 2155347968 BrkPadWrnIO 1;
BA_ "SignalType" SG_ 2155347968 BrkPadWrnIO "BLN";
BA_ "SignalLongName" SG_ 2155347968 BrkPadWrnIO "Brake Pad Worn Indication On";
BA_ "VNSigAllNodes" SG_ 2155347968 RrAxlMalfIO 1;
BA_ "SignalType" SG_ 2155347968 RrAxlMalfIO "BLN";
BA_ "SignalLongName" SG_ 2155347968 RrAxlMalfIO "Rear Axle Malfunction Indication On";
BA_ "VNSigAllNodes" SG_ 2155347968 EPBSysWrnIndReq 1;
BA_ "SignalType" SG_ 2155347968 EPBSysWrnIndReq "ENM";
BA_ "SignalLongName" SG_ 2155347968 EPBSysWrnIndReq "Electric Park Brake System Warning Indication Request";
BA_ "VNSigAllNodes" SG_ 2155347968 CompOvrhtIndOn 1;
BA_ "SignalType" SG_ 2155347968 CompOvrhtIndOn "BLN";
BA_ "SignalLongName" SG_ 2155347968 CompOvrhtIndOn "Compressor Overheated Indication On";
BA_ "VNSigAllNodes" SG_ 2155347968 BrkFldLvlLwV 1;
BA_ "SignalType" SG_ 2155347968 BrkFldLvlLwV "ENM";
BA_ "SignalLongName" SG_ 2155347968 BrkFldLvlLwV "Brake Fluid Level Low Validity";
BA_ "VNSigAllNodes" SG_ 2155347968 ACCSnsClnRqdIO 1;
BA_ "SignalType" SG_ 2155347968 ACCSnsClnRqdIO "BLN";
BA_ "SignalLongName" SG_ 2155347968 ACCSnsClnRqdIO "Adaptive Cruise Control Sensor Cleaning Required Indication On";
BA_ "VNSigAllNodes" SG_ 2155347968 TrnsSkpShftIO 1;
BA_ "SignalType" SG_ 2155347968 TrnsSkpShftIO "BLN";
BA_ "SignalLongName" SG_ 2155347968 TrnsSkpShftIO "Transmission Skip Shift Indication On";
BA_ "VNSigAllNodes" SG_ 2150432768 CbnHtrWrmUpIO 1;
BA_ "SignalType" SG_ 2150432768 CbnHtrWrmUpIO "BLN";
BA_ "SignalLongName" SG_ 2150432768 CbnHtrWrmUpIO "Cabin Heater Warm Up Indication On";
BA_ "VNSigAllNodes" SG_ 2150432768 EngManfldAirTempCrtdV 1;
BA_ "SignalType" SG_ 2150432768 EngManfldAirTempCrtdV "ENM";
BA_ "SignalLongName" SG_ 2150432768 EngManfldAirTempCrtdV "Engine Manifold Air Temperature Corrected Validity";
BA_ "VNSigAllNodes" SG_ 2150432768 GrdBrkgAct 1;
BA_ "SignalType" SG_ 2150432768 GrdBrkgAct "BLN";
BA_ "SignalLongName" SG_ 2150432768 GrdBrkgAct "Grade Braking Active";
BA_ "VNSigAllNodes" SG_ 2150432768 EngManfldAirTempCrtd 1;
BA_ "SignalType" SG_ 2150432768 EngManfldAirTempCrtd "UNM";
BA_ "SignalLongName" SG_ 2150432768 EngManfldAirTempCrtd "Engine Manifold Air Temperature Corrected";
BA_ "VNSigAllNodes" SG_ 2150432768 FuelFltLifRstPerf 1;
BA_ "SignalType" SG_ 2150432768 FuelFltLifRstPerf "BLN";
BA_ "SignalLongName" SG_ 2150432768 FuelFltLifRstPerf "Fuel Filter Life Reset Performed";
BA_ "VNSigAllNodes" SG_ 2150432768 FuelFltRmnLf 1;
BA_ "SignalType" SG_ 2150432768 FuelFltRmnLf "UNM";
BA_ "SignalLongName" SG_ 2150432768 FuelFltRmnLf "Fuel Filter Remaining Life";
BA_ "VNSigAllNodes" SG_ 2150432768 EngShtdwnPndgIO 1;
BA_ "SignalType" SG_ 2150432768 EngShtdwnPndgIO "BLN";
BA_ "SignalLongName" SG_ 2150432768 EngShtdwnPndgIO "Engine Shutdown Pending Indication On";
BA_ "VNSigAllNodes" SG_ 2150432768 GenFldDutCycV 1;
BA_ "SignalType" SG_ 2150432768 GenFldDutCycV "ENM";
BA_ "SignalLongName" SG_ 2150432768 GenFldDutCycV "Generator Field Duty Cycle Validity";
BA_ "VNSigAllNodes" SG_ 2150432768 GenFldDutCyc 1;
BA_ "SignalType" SG_ 2150432768 GenFldDutCyc "UNM";
BA_ "SignalLongName" SG_ 2150432768 GenFldDutCyc "Generator Field Duty Cycle";
BA_ "GenSigSendOnInit" SG_ 2150432768 FuelTotCap 1;
BA_ "VNSigAllNodes" SG_ 2150432768 FuelTotCap 1;
BA_ "SignalType" SG_ 2150432768 FuelTotCap "UNM";
BA_ "SignalLongName" SG_ 2150432768 FuelTotCap "Fuel Total Capacity";
BA_ "VNSigAllNodes" SG_ 2150432768 TransOilTempSensPres 1;
BA_ "SignalType" SG_ 2150432768 TransOilTempSensPres "BLN";
BA_ "SignalLongName" SG_ 2150432768 TransOilTempSensPres "Transmission Oil Temperature Sensor Present";
BA_ "VNSigAllNodes" SG_ 2150432768 TrnsNEmsRltMalfActv 1;
BA_ "SignalType" SG_ 2150432768 TrnsNEmsRltMalfActv "BLN";
BA_ "SignalLongName" SG_ 2150432768 TrnsNEmsRltMalfActv "Transmission Non Emissions Related Malfunction Active";
BA_ "VNSigAllNodes" SG_ 2150432768 TrnEmsMlfAtv 1;
BA_ "SignalType" SG_ 2150432768 TrnEmsMlfAtv "BLN";
BA_ "SignalLongName" SG_ 2150432768 TrnEmsMlfAtv "Transmission Emissions Related Malfunction Active";
BA_ "VNSigAllNodes" SG_ 2150432768 EngOilRmnLf 1;
BA_ "SignalType" SG_ 2150432768 EngOilRmnLf "UNM";
BA_ "SignalLongName" SG_ 2150432768 EngOilRmnLf "Engine Oil Remaining Life";
BA_ "VNSigAllNodes" SG_ 2150432768 TrnsThrmlMngmntStat 1;
BA_ "SignalType" SG_ 2150432768 TrnsThrmlMngmntStat "ENM";
BA_ "SignalLongName" SG_ 2150432768 TrnsThrmlMngmntStat "Transmission Thermal Management Status";
BA_ "VNSigAllNodes" SG_ 2150432768 PTHiElecLdReqd 1;
BA_ "SignalType" SG_ 2150432768 PTHiElecLdReqd "BLN";
BA_ "SignalLongName" SG_ 2150432768 PTHiElecLdReqd "Powertrain High Electrical Load Requested";
BA_ "GenSigSendType" SG_ 2154938368 FobProgMdStat 10;
BA_ "VNSigAllNodes" SG_ 2154938368 FobProgMdStat 1;
BA_ "SignalType" SG_ 2154938368 FobProgMdStat "ENM";
BA_ "SignalLongName" SG_ 2154938368 FobProgMdStat "Fob Programming Mode Status";
BA_ "GenSigSendOnInit" SG_ 2155266048 RRHCSeatSw3Act 2;
BA_ "GenSigSendType" SG_ 2155266048 RRHCSeatSw3Act 10;
BA_ "VNSigAllNodes" SG_ 2155266048 RRHCSeatSw3Act 1;
BA_ "SignalType" SG_ 2155266048 RRHCSeatSw3Act "BLN";
BA_ "SignalLongName" SG_ 2155266048 RRHCSeatSw3Act "Rear Right Heated/Cooled Seat Switch #3 Active";
BA_ "GenSigSendOnInit" SG_ 2155266048 RRHCSeatSw2Act 2;
BA_ "GenSigSendType" SG_ 2155266048 RRHCSeatSw2Act 10;
BA_ "VNSigAllNodes" SG_ 2155266048 RRHCSeatSw2Act 1;
BA_ "SignalType" SG_ 2155266048 RRHCSeatSw2Act "BLN";
BA_ "SignalLongName" SG_ 2155266048 RRHCSeatSw2Act "Rear Right Heated/Cooled Seat Switch #2 Active";
BA_ "GenSigSendOnInit" SG_ 2155266048 RRHCSeatSw1Act 2;
BA_ "GenSigSendType" SG_ 2155266048 RRHCSeatSw1Act 10;
BA_ "VNSigAllNodes" SG_ 2155266048 RRHCSeatSw1Act 1;
BA_ "SignalType" SG_ 2155266048 RRHCSeatSw1Act "BLN";
BA_ "SignalLongName" SG_ 2155266048 RRHCSeatSw1Act "Rear Right Heated/Cooled Seat Switch #1 Active";
BA_ "GenSigSendOnInit" SG_ 2155266048 RLHCSeatSw3Act 2;
BA_ "GenSigSendType" SG_ 2155266048 RLHCSeatSw3Act 10;
BA_ "VNSigAllNodes" SG_ 2155266048 RLHCSeatSw3Act 1;
BA_ "SignalType" SG_ 2155266048 RLHCSeatSw3Act "BLN";
BA_ "SignalLongName" SG_ 2155266048 RLHCSeatSw3Act "Rear Left Heated/Cooled Seat Switch #3 Active";
BA_ "GenSigSendOnInit" SG_ 2155266048 RLHCSeatSw2Act 2;
BA_ "GenSigSendType" SG_ 2155266048 RLHCSeatSw2Act 10;
BA_ "VNSigAllNodes" SG_ 2155266048 RLHCSeatSw2Act 1;
BA_ "SignalType" SG_ 2155266048 RLHCSeatSw2Act "BLN";
BA_ "SignalLongName" SG_ 2155266048 RLHCSeatSw2Act "Rear Left Heated/Cooled Seat Switch #2 Active";
BA_ "GenSigSendOnInit" SG_ 2155266048 RLHCSeatSw1Act 2;
BA_ "GenSigSendType" SG_ 2155266048 RLHCSeatSw1Act 10;
BA_ "VNSigAllNodes" SG_ 2155266048 RLHCSeatSw1Act 1;
BA_ "SignalType" SG_ 2155266048 RLHCSeatSw1Act "BLN";
BA_ "SignalLongName" SG_ 2155266048 RLHCSeatSw1Act "Rear Left Heated/Cooled Seat Switch #1 Active";
BA_ "GenSigSendOnInit" SG_ 2155249664 RRHCSMInd3 1;
BA_ "GenSigSendType" SG_ 2155249664 RRHCSMInd3 10;
BA_ "VNSigAllNodes" SG_ 2155249664 RRHCSMInd3 1;
BA_ "SignalType" SG_ 2155249664 RRHCSMInd3 "BLN";
BA_ "PacketOrder" SG_ 2155249664 RRHCSMInd3 4;
BA_ "SignalLongName" SG_ 2155249664 RRHCSMInd3 "Rear Right Heated/Cooled Seat Mode Indication Control : Seat Mode Indication 3";
BA_ "GenSigSendOnInit" SG_ 2155249664 RRHCSMInd2 1;
BA_ "GenSigSendType" SG_ 2155249664 RRHCSMInd2 10;
BA_ "VNSigAllNodes" SG_ 2155249664 RRHCSMInd2 1;
BA_ "SignalType" SG_ 2155249664 RRHCSMInd2 "BLN";
BA_ "PacketOrder" SG_ 2155249664 RRHCSMInd2 3;
BA_ "SignalLongName" SG_ 2155249664 RRHCSMInd2 "Rear Right Heated/Cooled Seat Mode Indication Control : Seat Mode Indication 2";
BA_ "GenSigSendOnInit" SG_ 2155249664 RRHCSMInd1 1;
BA_ "GenSigSendType" SG_ 2155249664 RRHCSMInd1 10;
BA_ "VNSigAllNodes" SG_ 2155249664 RRHCSMInd1 1;
BA_ "SignalType" SG_ 2155249664 RRHCSMInd1 "BLN";
BA_ "PacketOrder" SG_ 2155249664 RRHCSMInd1 2;
BA_ "SignalLongName" SG_ 2155249664 RRHCSMInd1 "Rear Right Heated/Cooled Seat Mode Indication Control : Seat Mode Indication 1";
BA_ "GenSigSendOnInit" SG_ 2155249664 RRHCSMIndReq 1;
BA_ "GenSigSendType" SG_ 2155249664 RRHCSMIndReq 10;
BA_ "VNSigAllNodes" SG_ 2155249664 RRHCSMIndReq 1;
BA_ "SignalType" SG_ 2155249664 RRHCSMIndReq "ENM";
BA_ "PacketOrder" SG_ 2155249664 RRHCSMIndReq 1;
BA_ "SignalLongName" SG_ 2155249664 RRHCSMIndReq "Rear Right Heated/Cooled Seat Mode Indication Control : Indication Request";
BA_ "GenSigSendOnInit" SG_ 2155249664 RRHCSLSeatLev5 1;
BA_ "GenSigSendType" SG_ 2155249664 RRHCSLSeatLev5 10;
BA_ "VNSigAllNodes" SG_ 2155249664 RRHCSLSeatLev5 1;
BA_ "SignalType" SG_ 2155249664 RRHCSLSeatLev5 "BLN";
BA_ "PacketOrder" SG_ 2155249664 RRHCSLSeatLev5 6;
BA_ "SignalLongName" SG_ 2155249664 RRHCSLSeatLev5 "Rear Right Heated/Cooled Seat Level Indication Control : Seat Level 5";
BA_ "GenSigSendOnInit" SG_ 2155249664 RRHCSLSeatLev4 1;
BA_ "GenSigSendType" SG_ 2155249664 RRHCSLSeatLev4 10;
BA_ "VNSigAllNodes" SG_ 2155249664 RRHCSLSeatLev4 1;
BA_ "SignalType" SG_ 2155249664 RRHCSLSeatLev4 "BLN";
BA_ "PacketOrder" SG_ 2155249664 RRHCSLSeatLev4 5;
BA_ "SignalLongName" SG_ 2155249664 RRHCSLSeatLev4 "Rear Right Heated/Cooled Seat Level Indication Control : Seat Level 4";
BA_ "GenSigSendOnInit" SG_ 2155249664 RRHCSLSeatLev3 1;
BA_ "GenSigSendType" SG_ 2155249664 RRHCSLSeatLev3 10;
BA_ "VNSigAllNodes" SG_ 2155249664 RRHCSLSeatLev3 1;
BA_ "SignalType" SG_ 2155249664 RRHCSLSeatLev3 "BLN";
BA_ "PacketOrder" SG_ 2155249664 RRHCSLSeatLev3 4;
BA_ "SignalLongName" SG_ 2155249664 RRHCSLSeatLev3 "Rear Right Heated/Cooled Seat Level Indication Control : Seat Level 3";
BA_ "GenSigSendOnInit" SG_ 2155249664 RRHCSLSeatLev2 1;
BA_ "GenSigSendType" SG_ 2155249664 RRHCSLSeatLev2 10;
BA_ "VNSigAllNodes" SG_ 2155249664 RRHCSLSeatLev2 1;
BA_ "SignalType" SG_ 2155249664 RRHCSLSeatLev2 "BLN";
BA_ "PacketOrder" SG_ 2155249664 RRHCSLSeatLev2 3;
BA_ "SignalLongName" SG_ 2155249664 RRHCSLSeatLev2 "Rear Right Heated/Cooled Seat Level Indication Control : Seat Level 2";
BA_ "GenSigSendOnInit" SG_ 2155249664 RRHCSLSeatLev1 1;
BA_ "GenSigSendType" SG_ 2155249664 RRHCSLSeatLev1 10;
BA_ "VNSigAllNodes" SG_ 2155249664 RRHCSLSeatLev1 1;
BA_ "SignalType" SG_ 2155249664 RRHCSLSeatLev1 "BLN";
BA_ "PacketOrder" SG_ 2155249664 RRHCSLSeatLev1 2;
BA_ "SignalLongName" SG_ 2155249664 RRHCSLSeatLev1 "Rear Right Heated/Cooled Seat Level Indication Control : Seat Level 1";
BA_ "GenSigSendOnInit" SG_ 2155249664 RRHCSLIndReq 1;
BA_ "GenSigSendType" SG_ 2155249664 RRHCSLIndReq 10;
BA_ "VNSigAllNodes" SG_ 2155249664 RRHCSLIndReq 1;
BA_ "SignalType" SG_ 2155249664 RRHCSLIndReq "ENM";
BA_ "PacketOrder" SG_ 2155249664 RRHCSLIndReq 1;
BA_ "SignalLongName" SG_ 2155249664 RRHCSLIndReq "Rear Right Heated/Cooled Seat Level Indication Control : Indication Request";
BA_ "GenSigSendOnInit" SG_ 2155249664 RLHCSMInd3 1;
BA_ "GenSigSendType" SG_ 2155249664 RLHCSMInd3 10;
BA_ "VNSigAllNodes" SG_ 2155249664 RLHCSMInd3 1;
BA_ "SignalType" SG_ 2155249664 RLHCSMInd3 "BLN";
BA_ "PacketOrder" SG_ 2155249664 RLHCSMInd3 4;
BA_ "SignalLongName" SG_ 2155249664 RLHCSMInd3 "Rear Left Heated/Cooled Seat Mode Indication Control : Seat Mode Indication 3";
BA_ "GenSigSendOnInit" SG_ 2155249664 RLHCSMInd2 1;
BA_ "GenSigSendType" SG_ 2155249664 RLHCSMInd2 10;
BA_ "VNSigAllNodes" SG_ 2155249664 RLHCSMInd2 1;
BA_ "SignalType" SG_ 2155249664 RLHCSMInd2 "BLN";
BA_ "PacketOrder" SG_ 2155249664 RLHCSMInd2 3;
BA_ "SignalLongName" SG_ 2155249664 RLHCSMInd2 "Rear Left Heated/Cooled Seat Mode Indication Control : Seat Mode Indication 2";
BA_ "GenSigSendOnInit" SG_ 2155249664 RLHCSMInd1 1;
BA_ "GenSigSendType" SG_ 2155249664 RLHCSMInd1 10;
BA_ "VNSigAllNodes" SG_ 2155249664 RLHCSMInd1 1;
BA_ "SignalType" SG_ 2155249664 RLHCSMInd1 "BLN";
BA_ "PacketOrder" SG_ 2155249664 RLHCSMInd1 2;
BA_ "SignalLongName" SG_ 2155249664 RLHCSMInd1 "Rear Left Heated/Cooled Seat Mode Indication Control : Seat Mode Indication 1";
BA_ "GenSigSendOnInit" SG_ 2155249664 RLHCSMIndReq 1;
BA_ "GenSigSendType" SG_ 2155249664 RLHCSMIndReq 10;
BA_ "VNSigAllNodes" SG_ 2155249664 RLHCSMIndReq 1;
BA_ "SignalType" SG_ 2155249664 RLHCSMIndReq "ENM";
BA_ "PacketOrder" SG_ 2155249664 RLHCSMIndReq 1;
BA_ "SignalLongName" SG_ 2155249664 RLHCSMIndReq "Rear Left Heated/Cooled Seat Mode Indication Control : Indication Request";
BA_ "GenSigSendOnInit" SG_ 2155249664 RLHCSLSeatLev5 1;
BA_ "GenSigSendType" SG_ 2155249664 RLHCSLSeatLev5 10;
BA_ "VNSigAllNodes" SG_ 2155249664 RLHCSLSeatLev5 1;
BA_ "SignalType" SG_ 2155249664 RLHCSLSeatLev5 "BLN";
BA_ "PacketOrder" SG_ 2155249664 RLHCSLSeatLev5 6;
BA_ "SignalLongName" SG_ 2155249664 RLHCSLSeatLev5 "Rear Left Heated/Cooled Seat Level Indication Control : Seat Level 5";
BA_ "GenSigSendOnInit" SG_ 2155249664 RLHCSLSeatLev4 1;
BA_ "GenSigSendType" SG_ 2155249664 RLHCSLSeatLev4 10;
BA_ "VNSigAllNodes" SG_ 2155249664 RLHCSLSeatLev4 1;
BA_ "SignalType" SG_ 2155249664 RLHCSLSeatLev4 "BLN";
BA_ "PacketOrder" SG_ 2155249664 RLHCSLSeatLev4 5;
BA_ "SignalLongName" SG_ 2155249664 RLHCSLSeatLev4 "Rear Left Heated/Cooled Seat Level Indication Control : Seat Level 4";
BA_ "GenSigSendOnInit" SG_ 2155249664 RLHCSLSeatLev3 1;
BA_ "GenSigSendType" SG_ 2155249664 RLHCSLSeatLev3 10;
BA_ "VNSigAllNodes" SG_ 2155249664 RLHCSLSeatLev3 1;
BA_ "SignalType" SG_ 2155249664 RLHCSLSeatLev3 "BLN";
BA_ "PacketOrder" SG_ 2155249664 RLHCSLSeatLev3 4;
BA_ "SignalLongName" SG_ 2155249664 RLHCSLSeatLev3 "Rear Left Heated/Cooled Seat Level Indication Control : Seat Level 3";
BA_ "GenSigSendOnInit" SG_ 2155249664 RLHCSLSeatLev2 1;
BA_ "GenSigSendType" SG_ 2155249664 RLHCSLSeatLev2 10;
BA_ "VNSigAllNodes" SG_ 2155249664 RLHCSLSeatLev2 1;
BA_ "SignalType" SG_ 2155249664 RLHCSLSeatLev2 "BLN";
BA_ "PacketOrder" SG_ 2155249664 RLHCSLSeatLev2 3;
BA_ "SignalLongName" SG_ 2155249664 RLHCSLSeatLev2 "Rear Left Heated/Cooled Seat Level Indication Control : Seat Level 2";
BA_ "GenSigSendOnInit" SG_ 2155249664 RLHCSLSeatLev1 1;
BA_ "GenSigSendType" SG_ 2155249664 RLHCSLSeatLev1 10;
BA_ "VNSigAllNodes" SG_ 2155249664 RLHCSLSeatLev1 1;
BA_ "SignalType" SG_ 2155249664 RLHCSLSeatLev1 "BLN";
BA_ "PacketOrder" SG_ 2155249664 RLHCSLSeatLev1 2;
BA_ "SignalLongName" SG_ 2155249664 RLHCSLSeatLev1 "Rear Left Heated/Cooled Seat Level Indication Control : Seat Level 1";
BA_ "GenSigSendOnInit" SG_ 2155249664 RLHCSLIndReq 1;
BA_ "GenSigSendType" SG_ 2155249664 RLHCSLIndReq 10;
BA_ "VNSigAllNodes" SG_ 2155249664 RLHCSLIndReq 1;
BA_ "SignalType" SG_ 2155249664 RLHCSLIndReq "ENM";
BA_ "PacketOrder" SG_ 2155249664 RLHCSLIndReq 1;
BA_ "SignalLongName" SG_ 2155249664 RLHCSLIndReq "Rear Left Heated/Cooled Seat Level Indication Control : Indication Request";
BA_ "GenSigSendOnInit" SG_ 2155184128 SmPhRmFunCstCurStVal 2;
BA_ "GenSigSendType" SG_ 2155184128 SmPhRmFunCstCurStVal 10;
BA_ "VNSigAllNodes" SG_ 2155184128 SmPhRmFunCstCurStVal 1;
BA_ "SignalType" SG_ 2155184128 SmPhRmFunCstCurStVal "ENM";
BA_ "SignalLongName" SG_ 2155184128 SmPhRmFunCstCurStVal "Smart Phone Remote Function Customization Current Setting Value";
BA_ "GenSigSendOnInit" SG_ 2155184128 SmPhRmFunCstStAval 2;
BA_ "GenSigSendType" SG_ 2155184128 SmPhRmFunCstStAval 10;
BA_ "VNSigAllNodes" SG_ 2155184128 SmPhRmFunCstStAval 1;
BA_ "SignalType" SG_ 2155184128 SmPhRmFunCstStAval "BLN";
BA_ "SignalLongName" SG_ 2155184128 SmPhRmFunCstStAval "Smart Phone Remote Function Customization Setting Available";
BA_ "GenSigSendOnInit" SG_ 2155184128 RrStRmndrIO 2;
BA_ "GenSigSendType" SG_ 2155184128 RrStRmndrIO 10;
BA_ "VNSigAllNodes" SG_ 2155184128 RrStRmndrIO 1;
BA_ "SignalType" SG_ 2155184128 RrStRmndrIO "BLN";
BA_ "SignalLongName" SG_ 2155184128 RrStRmndrIO "Rear Seat Reminder Indication On";
BA_ "GenSigSendOnInit" SG_ 2155184128 RrStRmndrCstCurrSetVal 2;
BA_ "GenSigSendType" SG_ 2155184128 RrStRmndrCstCurrSetVal 10;
BA_ "VNSigAllNodes" SG_ 2155184128 RrStRmndrCstCurrSetVal 1;
BA_ "SignalType" SG_ 2155184128 RrStRmndrCstCurrSetVal "ENM";
BA_ "SignalLongName" SG_ 2155184128 RrStRmndrCstCurrSetVal "Rear Seat Reminder Customization Current Setting Value";
BA_ "GenSigSendOnInit" SG_ 2155184128 RrStRmndrCstSetAvail 2;
BA_ "GenSigSendType" SG_ 2155184128 RrStRmndrCstSetAvail 10;
BA_ "VNSigAllNodes" SG_ 2155184128 RrStRmndrCstSetAvail 1;
BA_ "SignalType" SG_ 2155184128 RrStRmndrCstSetAvail "BLN";
BA_ "SignalLongName" SG_ 2155184128 RrStRmndrCstSetAvail "Rear Seat Reminder Customization Setting Available";
BA_ "GenSigSendType" SG_ 2155184128 IdlRecmndToClEngIO 10;
BA_ "VNSigAllNodes" SG_ 2155184128 IdlRecmndToClEngIO 1;
BA_ "SignalType" SG_ 2155184128 IdlRecmndToClEngIO "BLN";
BA_ "SignalLongName" SG_ 2155184128 IdlRecmndToClEngIO "Idle Recommended to Cool Engine Indication On";
BA_ "GenSigSendType" SG_ 2155184128 TrnsShftLvrLckStat 10;
BA_ "VNSigAllNodes" SG_ 2155184128 TrnsShftLvrLckStat 1;
BA_ "SignalType" SG_ 2155184128 TrnsShftLvrLckStat "ENM";
BA_ "SignalLongName" SG_ 2155184128 TrnsShftLvrLckStat "Transmission Shift Lever Lock Status";
BA_ "GenSigSendType" SG_ 2155184128 CrsSpdLmtrSwStat 10;
BA_ "VNSigAllNodes" SG_ 2155184128 CrsSpdLmtrSwStat 1;
BA_ "SignalType" SG_ 2155184128 CrsSpdLmtrSwStat "ENM";
BA_ "SignalLongName" SG_ 2155184128 CrsSpdLmtrSwStat "Cruise and Speed Limiter Switch Status";
BA_ "GenSigSendOnInit" SG_ 2155184128 CrsCntrlSwStCanSwAct 2;
BA_ "GenSigSendType" SG_ 2155184128 CrsCntrlSwStCanSwAct 10;
BA_ "VNSigAllNodes" SG_ 2155184128 CrsCntrlSwStCanSwAct 1;
BA_ "SignalType" SG_ 2155184128 CrsCntrlSwStCanSwAct "BLN";
BA_ "PacketOrder" SG_ 2155184128 CrsCntrlSwStCanSwAct 1;
BA_ "SignalLongName" SG_ 2155184128 CrsCntrlSwStCanSwAct "Cruise Control Switch Status : Cancel Switch Active";
BA_ "GenSigSendOnInit" SG_ 2155184128 CrsCntrlSwStSwDataIntgty 2;
BA_ "GenSigSendType" SG_ 2155184128 CrsCntrlSwStSwDataIntgty 10;
BA_ "VNSigAllNodes" SG_ 2155184128 CrsCntrlSwStSwDataIntgty 1;
BA_ "SignalType" SG_ 2155184128 CrsCntrlSwStSwDataIntgty "ENM";
BA_ "PacketOrder" SG_ 2155184128 CrsCntrlSwStSwDataIntgty 7;
BA_ "SignalLongName" SG_ 2155184128 CrsCntrlSwStSwDataIntgty "Cruise Control Switch Status : Switch Data Integrity";
BA_ "GenSigSendOnInit" SG_ 2155184128 CrsCntrlSwStSpdInSwAct 2;
BA_ "GenSigSendType" SG_ 2155184128 CrsCntrlSwStSpdInSwAct 10;
BA_ "VNSigAllNodes" SG_ 2155184128 CrsCntrlSwStSpdInSwAct 1;
BA_ "SignalType" SG_ 2155184128 CrsCntrlSwStSpdInSwAct "BLN";
BA_ "PacketOrder" SG_ 2155184128 CrsCntrlSwStSpdInSwAct 5;
BA_ "SignalLongName" SG_ 2155184128 CrsCntrlSwStSpdInSwAct "Cruise Control Switch Status : Speed Increase Switch Active";
BA_ "GenSigSendOnInit" SG_ 2155184128 CrsCntrlSwStSpDcSwAct 2;
BA_ "GenSigSendType" SG_ 2155184128 CrsCntrlSwStSpDcSwAct 10;
BA_ "VNSigAllNodes" SG_ 2155184128 CrsCntrlSwStSpDcSwAct 1;
BA_ "SignalType" SG_ 2155184128 CrsCntrlSwStSpDcSwAct "BLN";
BA_ "PacketOrder" SG_ 2155184128 CrsCntrlSwStSpDcSwAct 6;
BA_ "SignalLongName" SG_ 2155184128 CrsCntrlSwStSpDcSwAct "Cruise Control Switch Status : Speed Decrease Switch Active";
BA_ "GenSigSendOnInit" SG_ 2155184128 CrsCntrlSwStSetSwAct 2;
BA_ "GenSigSendType" SG_ 2155184128 CrsCntrlSwStSetSwAct 10;
BA_ "VNSigAllNodes" SG_ 2155184128 CrsCntrlSwStSetSwAct 1;
BA_ "SignalType" SG_ 2155184128 CrsCntrlSwStSetSwAct "BLN";
BA_ "PacketOrder" SG_ 2155184128 CrsCntrlSwStSetSwAct 4;
BA_ "SignalLongName" SG_ 2155184128 CrsCntrlSwStSetSwAct "Cruise Control Switch Status : Set Switch Active";
BA_ "GenSigSendOnInit" SG_ 2155184128 CrsCntrlSwStResSwAct 2;
BA_ "GenSigSendType" SG_ 2155184128 CrsCntrlSwStResSwAct 10;
BA_ "VNSigAllNodes" SG_ 2155184128 CrsCntrlSwStResSwAct 1;
BA_ "SignalType" SG_ 2155184128 CrsCntrlSwStResSwAct "BLN";
BA_ "PacketOrder" SG_ 2155184128 CrsCntrlSwStResSwAct 3;
BA_ "SignalLongName" SG_ 2155184128 CrsCntrlSwStResSwAct "Cruise Control Switch Status : Resume Switch Active";
BA_ "GenSigSendOnInit" SG_ 2155184128 CrsCntrlSwStOnSwAct 2;
BA_ "GenSigSendType" SG_ 2155184128 CrsCntrlSwStOnSwAct 10;
BA_ "VNSigAllNodes" SG_ 2155184128 CrsCntrlSwStOnSwAct 1;
BA_ "SignalType" SG_ 2155184128 CrsCntrlSwStOnSwAct "BLN";
BA_ "PacketOrder" SG_ 2155184128 CrsCntrlSwStOnSwAct 2;
BA_ "SignalLongName" SG_ 2155184128 CrsCntrlSwStOnSwAct "Cruise Control Switch Status : On Switch Active";
BA_ "GenSigSendOnInit" SG_ 2155184128 CrsCntAtv 2;
BA_ "GenSigSendType" SG_ 2155184128 CrsCntAtv 10;
BA_ "VNSigAllNodes" SG_ 2155184128 CrsCntAtv 1;
BA_ "SignalType" SG_ 2155184128 CrsCntAtv "BLN";
BA_ "SignalLongName" SG_ 2155184128 CrsCntAtv "Cruise Control Active";
BA_ "GenSigSendType" SG_ 2154921984 RFRmtCntFobNm 10;
BA_ "VNSigAllNodes" SG_ 2154921984 RFRmtCntFobNm 1;
BA_ "SignalType" SG_ 2154921984 RFRmtCntFobNm "ENM";
BA_ "PacketOrder" SG_ 2154921984 RFRmtCntFobNm 1;
BA_ "SignalLongName" SG_ 2154921984 RFRmtCntFobNm "RFA Function : Remote Control Fob Number";
BA_ "GenSigSendType" SG_ 2154921984 RFRmtCntrlFobFnc 10;
BA_ "VNSigAllNodes" SG_ 2154921984 RFRmtCntrlFobFnc 1;
BA_ "SignalType" SG_ 2154921984 RFRmtCntrlFobFnc "ENM";
BA_ "PacketOrder" SG_ 2154921984 RFRmtCntrlFobFnc 2;
BA_ "SignalLongName" SG_ 2154921984 RFRmtCntrlFobFnc "RFA Function : Remote Control Fob Function";
BA_ "GenSigSendType" SG_ 2154921984 RFRmtCntFobBatLw 10;
BA_ "VNSigAllNodes" SG_ 2154921984 RFRmtCntFobBatLw 1;
BA_ "SignalType" SG_ 2154921984 RFRmtCntFobBatLw "BLN";
BA_ "PacketOrder" SG_ 2154921984 RFRmtCntFobBatLw 3;
BA_ "SignalLongName" SG_ 2154921984 RFRmtCntFobBatLw "RFA Function : Remote Control Fob Battery Low";
BA_ "GenSigSendType" SG_ 2154921984 FobPogLimRchdIndOn 10;
BA_ "VNSigAllNodes" SG_ 2154921984 FobPogLimRchdIndOn 1;
BA_ "SignalType" SG_ 2154921984 FobPogLimRchdIndOn "BLN";
BA_ "SignalLongName" SG_ 2154921984 FobPogLimRchdIndOn "Fob Programming Limit Reached Indication On";
BA_ "GenSigSendOnInit" SG_ 2154962944 PassHCSMInd3 1;
BA_ "GenSigSendType" SG_ 2154962944 PassHCSMInd3 10;
BA_ "VNSigAllNodes" SG_ 2154962944 PassHCSMInd3 1;
BA_ "SignalType" SG_ 2154962944 PassHCSMInd3 "BLN";
BA_ "PacketOrder" SG_ 2154962944 PassHCSMInd3 4;
BA_ "SignalLongName" SG_ 2154962944 PassHCSMInd3 "Passenger Heated/Cooled Seat Mode Indication Control : Seat Mode Indication 3";
BA_ "GenSigSendOnInit" SG_ 2154962944 PassHCSMInd2 1;
BA_ "GenSigSendType" SG_ 2154962944 PassHCSMInd2 10;
BA_ "VNSigAllNodes" SG_ 2154962944 PassHCSMInd2 1;
BA_ "SignalType" SG_ 2154962944 PassHCSMInd2 "BLN";
BA_ "PacketOrder" SG_ 2154962944 PassHCSMInd2 3;
BA_ "SignalLongName" SG_ 2154962944 PassHCSMInd2 "Passenger Heated/Cooled Seat Mode Indication Control : Seat Mode Indication 2";
BA_ "GenSigSendOnInit" SG_ 2154962944 PassHCSMInd1 1;
BA_ "GenSigSendType" SG_ 2154962944 PassHCSMInd1 10;
BA_ "VNSigAllNodes" SG_ 2154962944 PassHCSMInd1 1;
BA_ "SignalType" SG_ 2154962944 PassHCSMInd1 "BLN";
BA_ "PacketOrder" SG_ 2154962944 PassHCSMInd1 2;
BA_ "SignalLongName" SG_ 2154962944 PassHCSMInd1 "Passenger Heated/Cooled Seat Mode Indication Control : Seat Mode Indication 1";
BA_ "GenSigSendOnInit" SG_ 2154962944 PassHCSMIndReq 1;
BA_ "GenSigSendType" SG_ 2154962944 PassHCSMIndReq 10;
BA_ "VNSigAllNodes" SG_ 2154962944 PassHCSMIndReq 1;
BA_ "SignalType" SG_ 2154962944 PassHCSMIndReq "ENM";
BA_ "PacketOrder" SG_ 2154962944 PassHCSMIndReq 1;
BA_ "SignalLongName" SG_ 2154962944 PassHCSMIndReq "Passenger Heated/Cooled Seat Mode Indication Control : Indication Request";
BA_ "GenSigSendOnInit" SG_ 2154962944 PassHCSLSeatLev5 1;
BA_ "GenSigSendType" SG_ 2154962944 PassHCSLSeatLev5 10;
BA_ "VNSigAllNodes" SG_ 2154962944 PassHCSLSeatLev5 1;
BA_ "SignalType" SG_ 2154962944 PassHCSLSeatLev5 "BLN";
BA_ "PacketOrder" SG_ 2154962944 PassHCSLSeatLev5 6;
BA_ "SignalLongName" SG_ 2154962944 PassHCSLSeatLev5 "Passenger Heated/Cooled Seat Level Indication Control : Seat Level 5";
BA_ "GenSigSendOnInit" SG_ 2154962944 PassHCSLSeatLev4 1;
BA_ "GenSigSendType" SG_ 2154962944 PassHCSLSeatLev4 10;
BA_ "VNSigAllNodes" SG_ 2154962944 PassHCSLSeatLev4 1;
BA_ "SignalType" SG_ 2154962944 PassHCSLSeatLev4 "BLN";
BA_ "PacketOrder" SG_ 2154962944 PassHCSLSeatLev4 5;
BA_ "SignalLongName" SG_ 2154962944 PassHCSLSeatLev4 "Passenger Heated/Cooled Seat Level Indication Control : Seat Level 4";
BA_ "GenSigSendOnInit" SG_ 2154962944 PassHCSLSeatLev3 1;
BA_ "GenSigSendType" SG_ 2154962944 PassHCSLSeatLev3 10;
BA_ "VNSigAllNodes" SG_ 2154962944 PassHCSLSeatLev3 1;
BA_ "SignalType" SG_ 2154962944 PassHCSLSeatLev3 "BLN";
BA_ "PacketOrder" SG_ 2154962944 PassHCSLSeatLev3 4;
BA_ "SignalLongName" SG_ 2154962944 PassHCSLSeatLev3 "Passenger Heated/Cooled Seat Level Indication Control : Seat Level 3";
BA_ "GenSigSendOnInit" SG_ 2154962944 PassHCSLSeatLev2 1;
BA_ "GenSigSendType" SG_ 2154962944 PassHCSLSeatLev2 10;
BA_ "VNSigAllNodes" SG_ 2154962944 PassHCSLSeatLev2 1;
BA_ "SignalType" SG_ 2154962944 PassHCSLSeatLev2 "BLN";
BA_ "PacketOrder" SG_ 2154962944 PassHCSLSeatLev2 3;
BA_ "SignalLongName" SG_ 2154962944 PassHCSLSeatLev2 "Passenger Heated/Cooled Seat Level Indication Control : Seat Level 2";
BA_ "GenSigSendOnInit" SG_ 2154962944 PassHCSLSeatLev1 1;
BA_ "GenSigSendType" SG_ 2154962944 PassHCSLSeatLev1 10;
BA_ "VNSigAllNodes" SG_ 2154962944 PassHCSLSeatLev1 1;
BA_ "SignalType" SG_ 2154962944 PassHCSLSeatLev1 "BLN";
BA_ "PacketOrder" SG_ 2154962944 PassHCSLSeatLev1 2;
BA_ "SignalLongName" SG_ 2154962944 PassHCSLSeatLev1 "Passenger Heated/Cooled Seat Level Indication Control : Seat Level 1";
BA_ "GenSigSendOnInit" SG_ 2154962944 PassHCSLIndReq 1;
BA_ "GenSigSendType" SG_ 2154962944 PassHCSLIndReq 10;
BA_ "VNSigAllNodes" SG_ 2154962944 PassHCSLIndReq 1;
BA_ "SignalType" SG_ 2154962944 PassHCSLIndReq "ENM";
BA_ "PacketOrder" SG_ 2154962944 PassHCSLIndReq 1;
BA_ "SignalLongName" SG_ 2154962944 PassHCSLIndReq "Passenger Heated/Cooled Seat Level Indication Control : Indication Request";
BA_ "GenSigSendOnInit" SG_ 2154962944 DrvHCSMInd1 1;
BA_ "GenSigSendType" SG_ 2154962944 DrvHCSMInd1 10;
BA_ "VNSigAllNodes" SG_ 2154962944 DrvHCSMInd1 1;
BA_ "SignalType" SG_ 2154962944 DrvHCSMInd1 "BLN";
BA_ "PacketOrder" SG_ 2154962944 DrvHCSMInd1 2;
BA_ "SignalLongName" SG_ 2154962944 DrvHCSMInd1 "Driver Heated/Cooled Seat Mode Indication Control : Seat Mode Indication 1";
BA_ "GenSigSendOnInit" SG_ 2154962944 DrvHCSMIndReq 1;
BA_ "GenSigSendType" SG_ 2154962944 DrvHCSMIndReq 10;
BA_ "VNSigAllNodes" SG_ 2154962944 DrvHCSMIndReq 1;
BA_ "SignalType" SG_ 2154962944 DrvHCSMIndReq "ENM";
BA_ "PacketOrder" SG_ 2154962944 DrvHCSMIndReq 1;
BA_ "SignalLongName" SG_ 2154962944 DrvHCSMIndReq "Driver Heated/Cooled Seat Mode Indication Control : Indication Request";
BA_ "GenSigSendOnInit" SG_ 2154962944 DrvHCSMInd3 1;
BA_ "GenSigSendType" SG_ 2154962944 DrvHCSMInd3 10;
BA_ "VNSigAllNodes" SG_ 2154962944 DrvHCSMInd3 1;
BA_ "SignalType" SG_ 2154962944 DrvHCSMInd3 "BLN";
BA_ "PacketOrder" SG_ 2154962944 DrvHCSMInd3 4;
BA_ "SignalLongName" SG_ 2154962944 DrvHCSMInd3 "Driver Heated/Cooled Seat Mode Indication Control : Seat Mode Indication 3";
BA_ "GenSigSendOnInit" SG_ 2154962944 DrvHCSMInd2 1;
BA_ "GenSigSendType" SG_ 2154962944 DrvHCSMInd2 10;
BA_ "VNSigAllNodes" SG_ 2154962944 DrvHCSMInd2 1;
BA_ "SignalType" SG_ 2154962944 DrvHCSMInd2 "BLN";
BA_ "PacketOrder" SG_ 2154962944 DrvHCSMInd2 3;
BA_ "SignalLongName" SG_ 2154962944 DrvHCSMInd2 "Driver Heated/Cooled Seat Mode Indication Control : Seat Mode Indication 2";
BA_ "GenSigSendOnInit" SG_ 2154962944 DrvHCSLSeatLev5 1;
BA_ "GenSigSendType" SG_ 2154962944 DrvHCSLSeatLev5 10;
BA_ "VNSigAllNodes" SG_ 2154962944 DrvHCSLSeatLev5 1;
BA_ "SignalType" SG_ 2154962944 DrvHCSLSeatLev5 "BLN";
BA_ "PacketOrder" SG_ 2154962944 DrvHCSLSeatLev5 6;
BA_ "SignalLongName" SG_ 2154962944 DrvHCSLSeatLev5 "Driver Heated/Cooled Seat Level Indication Control : Seat Level 5";
BA_ "GenSigSendOnInit" SG_ 2154962944 DrvHCSLSeatLev4 1;
BA_ "GenSigSendType" SG_ 2154962944 DrvHCSLSeatLev4 10;
BA_ "VNSigAllNodes" SG_ 2154962944 DrvHCSLSeatLev4 1;
BA_ "SignalType" SG_ 2154962944 DrvHCSLSeatLev4 "BLN";
BA_ "PacketOrder" SG_ 2154962944 DrvHCSLSeatLev4 5;
BA_ "SignalLongName" SG_ 2154962944 DrvHCSLSeatLev4 "Driver Heated/Cooled Seat Level Indication Control : Seat Level 4";
BA_ "GenSigSendOnInit" SG_ 2154962944 DrvHCSLSeatLev3 1;
BA_ "GenSigSendType" SG_ 2154962944 DrvHCSLSeatLev3 10;
BA_ "VNSigAllNodes" SG_ 2154962944 DrvHCSLSeatLev3 1;
BA_ "SignalType" SG_ 2154962944 DrvHCSLSeatLev3 "BLN";
BA_ "PacketOrder" SG_ 2154962944 DrvHCSLSeatLev3 4;
BA_ "SignalLongName" SG_ 2154962944 DrvHCSLSeatLev3 "Driver Heated/Cooled Seat Level Indication Control : Seat Level 3";
BA_ "GenSigSendOnInit" SG_ 2154962944 DrvHCSLSeatLev2 1;
BA_ "GenSigSendType" SG_ 2154962944 DrvHCSLSeatLev2 10;
BA_ "VNSigAllNodes" SG_ 2154962944 DrvHCSLSeatLev2 1;
BA_ "SignalType" SG_ 2154962944 DrvHCSLSeatLev2 "BLN";
BA_ "PacketOrder" SG_ 2154962944 DrvHCSLSeatLev2 3;
BA_ "SignalLongName" SG_ 2154962944 DrvHCSLSeatLev2 "Driver Heated/Cooled Seat Level Indication Control : Seat Level 2";
BA_ "GenSigSendOnInit" SG_ 2154962944 DrvHCSLSeatLev1 1;
BA_ "GenSigSendType" SG_ 2154962944 DrvHCSLSeatLev1 10;
BA_ "VNSigAllNodes" SG_ 2154962944 DrvHCSLSeatLev1 1;
BA_ "SignalType" SG_ 2154962944 DrvHCSLSeatLev1 "BLN";
BA_ "PacketOrder" SG_ 2154962944 DrvHCSLSeatLev1 2;
BA_ "SignalLongName" SG_ 2154962944 DrvHCSLSeatLev1 "Driver Heated/Cooled Seat Level Indication Control : Seat Level 1";
BA_ "GenSigSendOnInit" SG_ 2154962944 DrvHCSLIndReq 1;
BA_ "GenSigSendType" SG_ 2154962944 DrvHCSLIndReq 10;
BA_ "VNSigAllNodes" SG_ 2154962944 DrvHCSLIndReq 1;
BA_ "SignalType" SG_ 2154962944 DrvHCSLIndReq "ENM";
BA_ "PacketOrder" SG_ 2154962944 DrvHCSLIndReq 1;
BA_ "SignalLongName" SG_ 2154962944 DrvHCSLIndReq "Driver Heated/Cooled Seat Level Indication Control : Indication Request";
BA_ "GenSigSendType" SG_ 2156232704 ACSAlarm9 10;
BA_ "VNSigAllNodes" SG_ 2156232704 ACSAlarm9 1;
BA_ "SignalType" SG_ 2156232704 ACSAlarm9 "ENM";
BA_ "PacketOrder" SG_ 2156232704 ACSAlarm9 10;
BA_ "SignalLongName" SG_ 2156232704 ACSAlarm9 "Alarm Clock Status : Alarm 9";
BA_ "GenSigSendType" SG_ 2156232704 ACSAlarm8 10;
BA_ "VNSigAllNodes" SG_ 2156232704 ACSAlarm8 1;
BA_ "SignalType" SG_ 2156232704 ACSAlarm8 "ENM";
BA_ "PacketOrder" SG_ 2156232704 ACSAlarm8 9;
BA_ "SignalLongName" SG_ 2156232704 ACSAlarm8 "Alarm Clock Status : Alarm 8";
BA_ "GenSigSendType" SG_ 2156232704 ACSAlarm7 10;
BA_ "VNSigAllNodes" SG_ 2156232704 ACSAlarm7 1;
BA_ "SignalType" SG_ 2156232704 ACSAlarm7 "ENM";
BA_ "PacketOrder" SG_ 2156232704 ACSAlarm7 8;
BA_ "SignalLongName" SG_ 2156232704 ACSAlarm7 "Alarm Clock Status : Alarm 7";
BA_ "GenSigSendType" SG_ 2156232704 ACSAlarm6 10;
BA_ "VNSigAllNodes" SG_ 2156232704 ACSAlarm6 1;
BA_ "SignalType" SG_ 2156232704 ACSAlarm6 "ENM";
BA_ "PacketOrder" SG_ 2156232704 ACSAlarm6 7;
BA_ "SignalLongName" SG_ 2156232704 ACSAlarm6 "Alarm Clock Status : Alarm 6";
BA_ "GenSigSendType" SG_ 2156232704 ACSAlarm5 10;
BA_ "VNSigAllNodes" SG_ 2156232704 ACSAlarm5 1;
BA_ "SignalType" SG_ 2156232704 ACSAlarm5 "ENM";
BA_ "PacketOrder" SG_ 2156232704 ACSAlarm5 6;
BA_ "SignalLongName" SG_ 2156232704 ACSAlarm5 "Alarm Clock Status : Alarm 5";
BA_ "GenSigSendType" SG_ 2156232704 ACSAlarm4 10;
BA_ "VNSigAllNodes" SG_ 2156232704 ACSAlarm4 1;
BA_ "SignalType" SG_ 2156232704 ACSAlarm4 "ENM";
BA_ "PacketOrder" SG_ 2156232704 ACSAlarm4 5;
BA_ "SignalLongName" SG_ 2156232704 ACSAlarm4 "Alarm Clock Status : Alarm 4";
BA_ "GenSigSendType" SG_ 2156232704 ACSAlarm3 10;
BA_ "VNSigAllNodes" SG_ 2156232704 ACSAlarm3 1;
BA_ "SignalType" SG_ 2156232704 ACSAlarm3 "ENM";
BA_ "PacketOrder" SG_ 2156232704 ACSAlarm3 4;
BA_ "SignalLongName" SG_ 2156232704 ACSAlarm3 "Alarm Clock Status : Alarm 3";
BA_ "GenSigSendType" SG_ 2156232704 ACSAlarm2 10;
BA_ "VNSigAllNodes" SG_ 2156232704 ACSAlarm2 1;
BA_ "SignalType" SG_ 2156232704 ACSAlarm2 "ENM";
BA_ "PacketOrder" SG_ 2156232704 ACSAlarm2 3;
BA_ "SignalLongName" SG_ 2156232704 ACSAlarm2 "Alarm Clock Status : Alarm 2";
BA_ "GenSigSendType" SG_ 2156232704 ACSAlarm15 10;
BA_ "VNSigAllNodes" SG_ 2156232704 ACSAlarm15 1;
BA_ "SignalType" SG_ 2156232704 ACSAlarm15 "ENM";
BA_ "PacketOrder" SG_ 2156232704 ACSAlarm15 16;
BA_ "SignalLongName" SG_ 2156232704 ACSAlarm15 "Alarm Clock Status : Alarm 15";
BA_ "GenSigSendType" SG_ 2156232704 ACSAlarm14 10;
BA_ "VNSigAllNodes" SG_ 2156232704 ACSAlarm14 1;
BA_ "SignalType" SG_ 2156232704 ACSAlarm14 "ENM";
BA_ "PacketOrder" SG_ 2156232704 ACSAlarm14 15;
BA_ "SignalLongName" SG_ 2156232704 ACSAlarm14 "Alarm Clock Status : Alarm 14";
BA_ "GenSigSendType" SG_ 2156232704 ACSAlarm13 10;
BA_ "VNSigAllNodes" SG_ 2156232704 ACSAlarm13 1;
BA_ "SignalType" SG_ 2156232704 ACSAlarm13 "ENM";
BA_ "PacketOrder" SG_ 2156232704 ACSAlarm13 14;
BA_ "SignalLongName" SG_ 2156232704 ACSAlarm13 "Alarm Clock Status : Alarm 13";
BA_ "GenSigSendType" SG_ 2156232704 ACSAlarm12 10;
BA_ "VNSigAllNodes" SG_ 2156232704 ACSAlarm12 1;
BA_ "SignalType" SG_ 2156232704 ACSAlarm12 "ENM";
BA_ "PacketOrder" SG_ 2156232704 ACSAlarm12 13;
BA_ "SignalLongName" SG_ 2156232704 ACSAlarm12 "Alarm Clock Status : Alarm 12";
BA_ "GenSigSendType" SG_ 2156232704 ACSAlarm11 10;
BA_ "VNSigAllNodes" SG_ 2156232704 ACSAlarm11 1;
BA_ "SignalType" SG_ 2156232704 ACSAlarm11 "ENM";
BA_ "PacketOrder" SG_ 2156232704 ACSAlarm11 12;
BA_ "SignalLongName" SG_ 2156232704 ACSAlarm11 "Alarm Clock Status : Alarm 11";
BA_ "GenSigSendType" SG_ 2156232704 ACSAlarm10 10;
BA_ "VNSigAllNodes" SG_ 2156232704 ACSAlarm10 1;
BA_ "SignalType" SG_ 2156232704 ACSAlarm10 "ENM";
BA_ "PacketOrder" SG_ 2156232704 ACSAlarm10 11;
BA_ "SignalLongName" SG_ 2156232704 ACSAlarm10 "Alarm Clock Status : Alarm 10";
BA_ "GenSigSendType" SG_ 2156232704 ACSAlarm1 10;
BA_ "VNSigAllNodes" SG_ 2156232704 ACSAlarm1 1;
BA_ "SignalType" SG_ 2156232704 ACSAlarm1 "ENM";
BA_ "PacketOrder" SG_ 2156232704 ACSAlarm1 2;
BA_ "SignalLongName" SG_ 2156232704 ACSAlarm1 "Alarm Clock Status : Alarm 1";
BA_ "GenSigSendType" SG_ 2156232704 ACSAlarm0 10;
BA_ "VNSigAllNodes" SG_ 2156232704 ACSAlarm0 1;
BA_ "SignalType" SG_ 2156232704 ACSAlarm0 "ENM";
BA_ "PacketOrder" SG_ 2156232704 ACSAlarm0 1;
BA_ "SignalLongName" SG_ 2156232704 ACSAlarm0 "Alarm Clock Status : Alarm 0";
BA_ "GenSigSendOnInit" SG_ 2154987520 WrlsChrgSysChrgStat 2;
BA_ "GenSigSendType" SG_ 2154987520 WrlsChrgSysChrgStat 10;
BA_ "VNSigAllNodes" SG_ 2154987520 WrlsChrgSysChrgStat 1;
BA_ "SignalType" SG_ 2154987520 WrlsChrgSysChrgStat "ENM";
BA_ "SignalLongName" SG_ 2154987520 WrlsChrgSysChrgStat "Wireless Charging System Charging Status";
BA_ "GenSigSendType" SG_ 2154987520 HdStV 10;
BA_ "VNSigAllNodes" SG_ 2154987520 HdStV 1;
BA_ "SignalType" SG_ 2154987520 HdStV "ENM";
BA_ "SignalLongName" SG_ 2154987520 HdStV "Hood Status Validity";
BA_ "GenSigSendOnInit" SG_ 2154987520 HdSt 2;
BA_ "GenSigSendType" SG_ 2154987520 HdSt 10;
BA_ "VNSigAllNodes" SG_ 2154987520 HdSt 1;
BA_ "SignalType" SG_ 2154987520 HdSt "ENM";
BA_ "SignalLongName" SG_ 2154987520 HdSt "Hood Status";
BA_ "GenSigSendOnInit" SG_ 2154840064 CmpsZnNvrSet 1;
BA_ "GenSigSendType" SG_ 2154840064 CmpsZnNvrSet 10;
BA_ "VNSigAllNodes" SG_ 2154840064 CmpsZnNvrSet 1;
BA_ "SignalType" SG_ 2154840064 CmpsZnNvrSet "BLN";
BA_ "SignalLongName" SG_ 2154840064 CmpsZnNvrSet "Compass Zone Never Set";
BA_ "GenSigSendOnInit" SG_ 2154840064 CmpsSatrtd 1;
BA_ "GenSigSendType" SG_ 2154840064 CmpsSatrtd 10;
BA_ "VNSigAllNodes" SG_ 2154840064 CmpsSatrtd 1;
BA_ "SignalType" SG_ 2154840064 CmpsSatrtd "BLN";
BA_ "SignalLongName" SG_ 2154840064 CmpsSatrtd "Compass Saturated";
BA_ "GenSigSendOnInit" SG_ 2154840064 CmpsDecZone 1;
BA_ "GenSigSendType" SG_ 2154840064 CmpsDecZone 10;
BA_ "VNSigAllNodes" SG_ 2154840064 CmpsDecZone 1;
BA_ "SignalType" SG_ 2154840064 CmpsDecZone "ENM";
BA_ "SignalLongName" SG_ 2154840064 CmpsDecZone "Compass Declination Zone";
BA_ "GenSigSendOnInit" SG_ 2154840064 CmpsOctHdingDataSrc 1;
BA_ "GenSigSendType" SG_ 2154840064 CmpsOctHdingDataSrc 10;
BA_ "VNSigAllNodes" SG_ 2154840064 CmpsOctHdingDataSrc 1;
BA_ "SignalType" SG_ 2154840064 CmpsOctHdingDataSrc "ENM";
BA_ "SignalLongName" SG_ 2154840064 CmpsOctHdingDataSrc "Compass Octant Heading Data Source";
BA_ "GenSigSendOnInit" SG_ 2154840064 CmpsOctHding 1;
BA_ "GenSigSendType" SG_ 2154840064 CmpsOctHding 10;
BA_ "VNSigAllNodes" SG_ 2154840064 CmpsOctHding 1;
BA_ "SignalType" SG_ 2154840064 CmpsOctHding "ENM";
BA_ "SignalLongName" SG_ 2154840064 CmpsOctHding "Compass Octant Heading";
BA_ "GenSigSendOnInit" SG_ 2154840064 CmpsModManCalInPrc 1;
BA_ "GenSigSendType" SG_ 2154840064 CmpsModManCalInPrc 10;
BA_ "VNSigAllNodes" SG_ 2154840064 CmpsModManCalInPrc 1;
BA_ "SignalType" SG_ 2154840064 CmpsModManCalInPrc "BLN";
BA_ "SignalLongName" SG_ 2154840064 CmpsModManCalInPrc "Compass Module Manual Calibration In Process";
BA_ "GenSigSendOnInit" SG_ 2154840064 CmpsModFltPrs 1;
BA_ "GenSigSendType" SG_ 2154840064 CmpsModFltPrs 10;
BA_ "VNSigAllNodes" SG_ 2154840064 CmpsModFltPrs 1;
BA_ "SignalType" SG_ 2154840064 CmpsModFltPrs "BLN";
BA_ "SignalLongName" SG_ 2154840064 CmpsModFltPrs "Compass Module Fault Present";
BA_ "GenSigSendOnInit" SG_ 2154840064 CmpsCrHding 1;
BA_ "GenSigSendType" SG_ 2154840064 CmpsCrHding 12;
BA_ "GenSigDeltaValue" SG_ 2154840064 CmpsCrHding 1;
BA_ "VNSigAllNodes" SG_ 2154840064 CmpsCrHding 1;
BA_ "SignalType" SG_ 2154840064 CmpsCrHding "UNM";
BA_ "SignalLongName" SG_ 2154840064 CmpsCrHding "Compass Corrected Heading";
BA_ "GenSigSendType" SG_ 2154905600 DrvSeatPrsMemID 10;
BA_ "VNSigAllNodes" SG_ 2154905600 DrvSeatPrsMemID 1;
BA_ "SignalType" SG_ 2154905600 DrvSeatPrsMemID "ENM";
BA_ "SignalLongName" SG_ 2154905600 DrvSeatPrsMemID "Driver Seat Personalization Memory ID";
BA_ "GenSigStartValue" SG_ 2154905600 DrvSeatPrsMemID 7;
BA_ "GenSigSendOnInit" SG_ 2154905600 DrId 1;
BA_ "GenSigSendType" SG_ 2154905600 DrId 10;
BA_ "VNSigAllNodes" SG_ 2154905600 DrId 1;
BA_ "SignalType" SG_ 2154905600 DrId "ENM";
BA_ "SignalLongName" SG_ 2154905600 DrId "Driver Identifier";
BA_ "GenSigStartValue" SG_ 2154905600 DrId 7;
BA_ "GenSigSendOnInit" SG_ 2151841792 HtdFrntWSSt 2;
BA_ "GenSigSendType" SG_ 2151841792 HtdFrntWSSt 10;
BA_ "VNSigAllNodes" SG_ 2151841792 HtdFrntWSSt 1;
BA_ "SignalType" SG_ 2151841792 HtdFrntWSSt "ENM";
BA_ "SignalLongName" SG_ 2151841792 HtdFrntWSSt "Heated Front Windshield Status";
BA_ "GenSigSendType" SG_ 2151841792 WSWprAct 10;
BA_ "VNSigAllNodes" SG_ 2151841792 WSWprAct 1;
BA_ "SignalType" SG_ 2151841792 WSWprAct "BLN";
BA_ "SignalLongName" SG_ 2151841792 WSWprAct "Windshield Wiper Active";
BA_ "GenSigSendOnInit" SG_ 2151841792 RnSnsOffIO 2;
BA_ "GenSigSendType" SG_ 2151841792 RnSnsOffIO 10;
BA_ "VNSigAllNodes" SG_ 2151841792 RnSnsOffIO 1;
BA_ "SignalType" SG_ 2151841792 RnSnsOffIO "BLN";
BA_ "SignalLongName" SG_ 2151841792 RnSnsOffIO "Rain Sensor Off Indication On";
BA_ "GenSigSendType" SG_ 2151841792 RnSnsActIO 10;
BA_ "VNSigAllNodes" SG_ 2151841792 RnSnsActIO 1;
BA_ "SignalType" SG_ 2151841792 RnSnsActIO "BLN";
BA_ "SignalLongName" SG_ 2151841792 RnSnsActIO "Rain Sensor Active Indication On";
BA_ "GenSigSendType" SG_ 2151841792 TurnWprIntIO 10;
BA_ "VNSigAllNodes" SG_ 2151841792 TurnWprIntIO 1;
BA_ "SignalType" SG_ 2151841792 TurnWprIntIO "BLN";
BA_ "SignalLongName" SG_ 2151841792 TurnWprIntIO "Turn Wiper Control To Intermittent First Indication On";
BA_ "GenSigSendOnInit" SG_ 2154094592 IDCTA_ClrTyp21Avl 1;
BA_ "GenSigSendType" SG_ 2154094592 IDCTA_ClrTyp21Avl 10;
BA_ "VNSigAllNodes" SG_ 2154094592 IDCTA_ClrTyp21Avl 1;
BA_ "SignalType" SG_ 2154094592 IDCTA_ClrTyp21Avl "BLN";
BA_ "PacketOrder" SG_ 2154094592 IDCTA_ClrTyp21Avl 22;
BA_ "SignalLongName" SG_ 2154094592 IDCTA_ClrTyp21Avl "Interior Dimming Color Type Available : Color Type 21 Available";
BA_ "GenSigSendOnInit" SG_ 2154094592 IDCTA_ClrTyp20Avl 1;
BA_ "GenSigSendType" SG_ 2154094592 IDCTA_ClrTyp20Avl 10;
BA_ "VNSigAllNodes" SG_ 2154094592 IDCTA_ClrTyp20Avl 1;
BA_ "SignalType" SG_ 2154094592 IDCTA_ClrTyp20Avl "BLN";
BA_ "PacketOrder" SG_ 2154094592 IDCTA_ClrTyp20Avl 21;
BA_ "SignalLongName" SG_ 2154094592 IDCTA_ClrTyp20Avl "Interior Dimming Color Type Available : Color Type 20 Available";
BA_ "GenSigSendOnInit" SG_ 2154094592 IDCTA_ClrTyp19Avl 1;
BA_ "GenSigSendType" SG_ 2154094592 IDCTA_ClrTyp19Avl 10;
BA_ "VNSigAllNodes" SG_ 2154094592 IDCTA_ClrTyp19Avl 1;
BA_ "SignalType" SG_ 2154094592 IDCTA_ClrTyp19Avl "BLN";
BA_ "PacketOrder" SG_ 2154094592 IDCTA_ClrTyp19Avl 20;
BA_ "SignalLongName" SG_ 2154094592 IDCTA_ClrTyp19Avl "Interior Dimming Color Type Available : Color Type 19 Available";
BA_ "GenSigSendOnInit" SG_ 2154094592 IDCTA_ClrTyp18Avl 1;
BA_ "GenSigSendType" SG_ 2154094592 IDCTA_ClrTyp18Avl 10;
BA_ "VNSigAllNodes" SG_ 2154094592 IDCTA_ClrTyp18Avl 1;
BA_ "SignalType" SG_ 2154094592 IDCTA_ClrTyp18Avl "BLN";
BA_ "PacketOrder" SG_ 2154094592 IDCTA_ClrTyp18Avl 19;
BA_ "SignalLongName" SG_ 2154094592 IDCTA_ClrTyp18Avl "Interior Dimming Color Type Available : Color Type 18 Available";
BA_ "GenSigSendOnInit" SG_ 2154094592 IDCTA_ClrTyp17Avl 1;
BA_ "GenSigSendType" SG_ 2154094592 IDCTA_ClrTyp17Avl 10;
BA_ "VNSigAllNodes" SG_ 2154094592 IDCTA_ClrTyp17Avl 1;
BA_ "SignalType" SG_ 2154094592 IDCTA_ClrTyp17Avl "BLN";
BA_ "PacketOrder" SG_ 2154094592 IDCTA_ClrTyp17Avl 18;
BA_ "SignalLongName" SG_ 2154094592 IDCTA_ClrTyp17Avl "Interior Dimming Color Type Available : Color Type 17 Available";
BA_ "GenSigSendOnInit" SG_ 2154094592 IDCTA_ClrTyp16Avl 1;
BA_ "GenSigSendType" SG_ 2154094592 IDCTA_ClrTyp16Avl 10;
BA_ "VNSigAllNodes" SG_ 2154094592 IDCTA_ClrTyp16Avl 1;
BA_ "SignalType" SG_ 2154094592 IDCTA_ClrTyp16Avl "BLN";
BA_ "PacketOrder" SG_ 2154094592 IDCTA_ClrTyp16Avl 17;
BA_ "SignalLongName" SG_ 2154094592 IDCTA_ClrTyp16Avl "Interior Dimming Color Type Available : Color Type 16 Available";
BA_ "GenSigSendOnInit" SG_ 2154094592 IDCTA_ClrTyp15Avl 1;
BA_ "GenSigSendType" SG_ 2154094592 IDCTA_ClrTyp15Avl 10;
BA_ "VNSigAllNodes" SG_ 2154094592 IDCTA_ClrTyp15Avl 1;
BA_ "SignalType" SG_ 2154094592 IDCTA_ClrTyp15Avl "BLN";
BA_ "PacketOrder" SG_ 2154094592 IDCTA_ClrTyp15Avl 16;
BA_ "SignalLongName" SG_ 2154094592 IDCTA_ClrTyp15Avl "Interior Dimming Color Type Available : Color Type 15 Available";
BA_ "GenSigSendOnInit" SG_ 2154094592 IDCTA_ClrTyp14Avl 1;
BA_ "GenSigSendType" SG_ 2154094592 IDCTA_ClrTyp14Avl 10;
BA_ "VNSigAllNodes" SG_ 2154094592 IDCTA_ClrTyp14Avl 1;
BA_ "SignalType" SG_ 2154094592 IDCTA_ClrTyp14Avl "BLN";
BA_ "PacketOrder" SG_ 2154094592 IDCTA_ClrTyp14Avl 15;
BA_ "SignalLongName" SG_ 2154094592 IDCTA_ClrTyp14Avl "Interior Dimming Color Type Available : Color Type 14 Available";
BA_ "GenSigSendOnInit" SG_ 2154094592 IDCTA_ClrTyp13Avl 1;
BA_ "GenSigSendType" SG_ 2154094592 IDCTA_ClrTyp13Avl 10;
BA_ "VNSigAllNodes" SG_ 2154094592 IDCTA_ClrTyp13Avl 1;
BA_ "SignalType" SG_ 2154094592 IDCTA_ClrTyp13Avl "BLN";
BA_ "PacketOrder" SG_ 2154094592 IDCTA_ClrTyp13Avl 14;
BA_ "SignalLongName" SG_ 2154094592 IDCTA_ClrTyp13Avl "Interior Dimming Color Type Available : Color Type 13 Available";
BA_ "GenSigSendOnInit" SG_ 2154094592 IDCTA_ClrTyp12Avl 1;
BA_ "GenSigSendType" SG_ 2154094592 IDCTA_ClrTyp12Avl 10;
BA_ "VNSigAllNodes" SG_ 2154094592 IDCTA_ClrTyp12Avl 1;
BA_ "SignalType" SG_ 2154094592 IDCTA_ClrTyp12Avl "BLN";
BA_ "PacketOrder" SG_ 2154094592 IDCTA_ClrTyp12Avl 13;
BA_ "SignalLongName" SG_ 2154094592 IDCTA_ClrTyp12Avl "Interior Dimming Color Type Available : Color Type 12 Available";
BA_ "GenSigSendOnInit" SG_ 2154094592 IDCTA_ClrTyp11Avl 1;
BA_ "GenSigSendType" SG_ 2154094592 IDCTA_ClrTyp11Avl 10;
BA_ "VNSigAllNodes" SG_ 2154094592 IDCTA_ClrTyp11Avl 1;
BA_ "SignalType" SG_ 2154094592 IDCTA_ClrTyp11Avl "BLN";
BA_ "PacketOrder" SG_ 2154094592 IDCTA_ClrTyp11Avl 12;
BA_ "SignalLongName" SG_ 2154094592 IDCTA_ClrTyp11Avl "Interior Dimming Color Type Available : Color Type 11 Available";
BA_ "GenSigSendOnInit" SG_ 2154094592 IDCTA_ClrTyp10Avl 1;
BA_ "GenSigSendType" SG_ 2154094592 IDCTA_ClrTyp10Avl 10;
BA_ "VNSigAllNodes" SG_ 2154094592 IDCTA_ClrTyp10Avl 1;
BA_ "SignalType" SG_ 2154094592 IDCTA_ClrTyp10Avl "BLN";
BA_ "PacketOrder" SG_ 2154094592 IDCTA_ClrTyp10Avl 11;
BA_ "SignalLongName" SG_ 2154094592 IDCTA_ClrTyp10Avl "Interior Dimming Color Type Available : Color Type 10 Available";
BA_ "GenSigSendOnInit" SG_ 2154094592 IDCTA_ClrTyp9Avl 1;
BA_ "GenSigSendType" SG_ 2154094592 IDCTA_ClrTyp9Avl 10;
BA_ "VNSigAllNodes" SG_ 2154094592 IDCTA_ClrTyp9Avl 1;
BA_ "SignalType" SG_ 2154094592 IDCTA_ClrTyp9Avl "BLN";
BA_ "PacketOrder" SG_ 2154094592 IDCTA_ClrTyp9Avl 10;
BA_ "SignalLongName" SG_ 2154094592 IDCTA_ClrTyp9Avl "Interior Dimming Color Type Available : Color Type 9 Available";
BA_ "GenSigSendOnInit" SG_ 2154094592 IDCTA_ClrTyp8Avl 1;
BA_ "GenSigSendType" SG_ 2154094592 IDCTA_ClrTyp8Avl 10;
BA_ "VNSigAllNodes" SG_ 2154094592 IDCTA_ClrTyp8Avl 1;
BA_ "SignalType" SG_ 2154094592 IDCTA_ClrTyp8Avl "BLN";
BA_ "PacketOrder" SG_ 2154094592 IDCTA_ClrTyp8Avl 9;
BA_ "SignalLongName" SG_ 2154094592 IDCTA_ClrTyp8Avl "Interior Dimming Color Type Available : Color Type 8 Available";
BA_ "GenSigSendOnInit" SG_ 2154094592 IDCTA_ClrTyp7Avl 1;
BA_ "GenSigSendType" SG_ 2154094592 IDCTA_ClrTyp7Avl 10;
BA_ "VNSigAllNodes" SG_ 2154094592 IDCTA_ClrTyp7Avl 1;
BA_ "SignalType" SG_ 2154094592 IDCTA_ClrTyp7Avl "BLN";
BA_ "PacketOrder" SG_ 2154094592 IDCTA_ClrTyp7Avl 8;
BA_ "SignalLongName" SG_ 2154094592 IDCTA_ClrTyp7Avl "Interior Dimming Color Type Available : Color Type 7 Available";
BA_ "GenSigSendOnInit" SG_ 2154094592 IDCTA_ClrTyp6Avl 1;
BA_ "GenSigSendType" SG_ 2154094592 IDCTA_ClrTyp6Avl 10;
BA_ "VNSigAllNodes" SG_ 2154094592 IDCTA_ClrTyp6Avl 1;
BA_ "SignalType" SG_ 2154094592 IDCTA_ClrTyp6Avl "BLN";
BA_ "PacketOrder" SG_ 2154094592 IDCTA_ClrTyp6Avl 7;
BA_ "SignalLongName" SG_ 2154094592 IDCTA_ClrTyp6Avl "Interior Dimming Color Type Available : Color Type 6 Available";
BA_ "GenSigSendOnInit" SG_ 2154094592 IDCTA_ClrTyp5Avl 1;
BA_ "GenSigSendType" SG_ 2154094592 IDCTA_ClrTyp5Avl 10;
BA_ "VNSigAllNodes" SG_ 2154094592 IDCTA_ClrTyp5Avl 1;
BA_ "SignalType" SG_ 2154094592 IDCTA_ClrTyp5Avl "BLN";
BA_ "PacketOrder" SG_ 2154094592 IDCTA_ClrTyp5Avl 6;
BA_ "SignalLongName" SG_ 2154094592 IDCTA_ClrTyp5Avl "Interior Dimming Color Type Available : Color Type 5 Available";
BA_ "GenSigSendOnInit" SG_ 2154094592 IDCTA_ClrTyp4Avl 1;
BA_ "GenSigSendType" SG_ 2154094592 IDCTA_ClrTyp4Avl 10;
BA_ "VNSigAllNodes" SG_ 2154094592 IDCTA_ClrTyp4Avl 1;
BA_ "SignalType" SG_ 2154094592 IDCTA_ClrTyp4Avl "BLN";
BA_ "PacketOrder" SG_ 2154094592 IDCTA_ClrTyp4Avl 5;
BA_ "SignalLongName" SG_ 2154094592 IDCTA_ClrTyp4Avl "Interior Dimming Color Type Available : Color Type 4 Available";
BA_ "GenSigSendOnInit" SG_ 2154094592 IDCTA_ClrTyp3Avl 1;
BA_ "GenSigSendType" SG_ 2154094592 IDCTA_ClrTyp3Avl 10;
BA_ "VNSigAllNodes" SG_ 2154094592 IDCTA_ClrTyp3Avl 1;
BA_ "SignalType" SG_ 2154094592 IDCTA_ClrTyp3Avl "BLN";
BA_ "PacketOrder" SG_ 2154094592 IDCTA_ClrTyp3Avl 4;
BA_ "SignalLongName" SG_ 2154094592 IDCTA_ClrTyp3Avl "Interior Dimming Color Type Available : Color Type 3 Available";
BA_ "GenSigSendOnInit" SG_ 2154094592 IDCTA_ClrTyp2Avl 1;
BA_ "GenSigSendType" SG_ 2154094592 IDCTA_ClrTyp2Avl 10;
BA_ "VNSigAllNodes" SG_ 2154094592 IDCTA_ClrTyp2Avl 1;
BA_ "SignalType" SG_ 2154094592 IDCTA_ClrTyp2Avl "BLN";
BA_ "PacketOrder" SG_ 2154094592 IDCTA_ClrTyp2Avl 3;
BA_ "SignalLongName" SG_ 2154094592 IDCTA_ClrTyp2Avl "Interior Dimming Color Type Available : Color Type 2 Available";
BA_ "GenSigSendOnInit" SG_ 2154094592 IDCTA_ClrTyp1Avl 1;
BA_ "GenSigSendType" SG_ 2154094592 IDCTA_ClrTyp1Avl 10;
BA_ "VNSigAllNodes" SG_ 2154094592 IDCTA_ClrTyp1Avl 1;
BA_ "SignalType" SG_ 2154094592 IDCTA_ClrTyp1Avl "BLN";
BA_ "PacketOrder" SG_ 2154094592 IDCTA_ClrTyp1Avl 2;
BA_ "SignalLongName" SG_ 2154094592 IDCTA_ClrTyp1Avl "Interior Dimming Color Type Available : Color Type 1 Available";
BA_ "GenSigSendOnInit" SG_ 2154094592 IDCTA_OffAvl 1;
BA_ "GenSigSendType" SG_ 2154094592 IDCTA_OffAvl 10;
BA_ "VNSigAllNodes" SG_ 2154094592 IDCTA_OffAvl 1;
BA_ "SignalType" SG_ 2154094592 IDCTA_OffAvl "BLN";
BA_ "PacketOrder" SG_ 2154094592 IDCTA_OffAvl 1;
BA_ "SignalLongName" SG_ 2154094592 IDCTA_OffAvl "Interior Dimming Color Type Available : Off Available";
BA_ "GenSigSendOnInit" SG_ 2154094592 IDATA_AnmTyp14Avl 1;
BA_ "GenSigSendType" SG_ 2154094592 IDATA_AnmTyp14Avl 10;
BA_ "VNSigAllNodes" SG_ 2154094592 IDATA_AnmTyp14Avl 1;
BA_ "SignalType" SG_ 2154094592 IDATA_AnmTyp14Avl "BLN";
BA_ "PacketOrder" SG_ 2154094592 IDATA_AnmTyp14Avl 15;
BA_ "SignalLongName" SG_ 2154094592 IDATA_AnmTyp14Avl "Interior Dimming Animation Type Available : Animation Type 14 Available";
BA_ "GenSigSendOnInit" SG_ 2154094592 IDATA_AnmTyp13Avl 1;
BA_ "GenSigSendType" SG_ 2154094592 IDATA_AnmTyp13Avl 10;
BA_ "VNSigAllNodes" SG_ 2154094592 IDATA_AnmTyp13Avl 1;
BA_ "SignalType" SG_ 2154094592 IDATA_AnmTyp13Avl "BLN";
BA_ "PacketOrder" SG_ 2154094592 IDATA_AnmTyp13Avl 14;
BA_ "SignalLongName" SG_ 2154094592 IDATA_AnmTyp13Avl "Interior Dimming Animation Type Available : Animation Type 13 Available";
BA_ "GenSigSendOnInit" SG_ 2154094592 IDATA_AnmTyp12Avl 1;
BA_ "GenSigSendType" SG_ 2154094592 IDATA_AnmTyp12Avl 10;
BA_ "VNSigAllNodes" SG_ 2154094592 IDATA_AnmTyp12Avl 1;
BA_ "SignalType" SG_ 2154094592 IDATA_AnmTyp12Avl "BLN";
BA_ "PacketOrder" SG_ 2154094592 IDATA_AnmTyp12Avl 13;
BA_ "SignalLongName" SG_ 2154094592 IDATA_AnmTyp12Avl "Interior Dimming Animation Type Available : Animation Type 12 Available";
BA_ "GenSigSendOnInit" SG_ 2154094592 IDATA_AnmTyp11Avl 1;
BA_ "GenSigSendType" SG_ 2154094592 IDATA_AnmTyp11Avl 10;
BA_ "VNSigAllNodes" SG_ 2154094592 IDATA_AnmTyp11Avl 1;
BA_ "SignalType" SG_ 2154094592 IDATA_AnmTyp11Avl "BLN";
BA_ "PacketOrder" SG_ 2154094592 IDATA_AnmTyp11Avl 12;
BA_ "SignalLongName" SG_ 2154094592 IDATA_AnmTyp11Avl "Interior Dimming Animation Type Available : Animation Type 11 Available";
BA_ "GenSigSendOnInit" SG_ 2154094592 IDATA_AnmTyp10Avl 1;
BA_ "GenSigSendType" SG_ 2154094592 IDATA_AnmTyp10Avl 10;
BA_ "VNSigAllNodes" SG_ 2154094592 IDATA_AnmTyp10Avl 1;
BA_ "SignalType" SG_ 2154094592 IDATA_AnmTyp10Avl "BLN";
BA_ "PacketOrder" SG_ 2154094592 IDATA_AnmTyp10Avl 11;
BA_ "SignalLongName" SG_ 2154094592 IDATA_AnmTyp10Avl "Interior Dimming Animation Type Available : Animation Type 10 Available";
BA_ "GenSigSendOnInit" SG_ 2154094592 IDATA_AnmTyp9Avl 1;
BA_ "GenSigSendType" SG_ 2154094592 IDATA_AnmTyp9Avl 10;
BA_ "VNSigAllNodes" SG_ 2154094592 IDATA_AnmTyp9Avl 1;
BA_ "SignalType" SG_ 2154094592 IDATA_AnmTyp9Avl "BLN";
BA_ "PacketOrder" SG_ 2154094592 IDATA_AnmTyp9Avl 10;
BA_ "SignalLongName" SG_ 2154094592 IDATA_AnmTyp9Avl "Interior Dimming Animation Type Available : Animation Type 9 Available";
BA_ "GenSigSendOnInit" SG_ 2154094592 IDATA_AnmTyp8Avl 1;
BA_ "GenSigSendType" SG_ 2154094592 IDATA_AnmTyp8Avl 10;
BA_ "VNSigAllNodes" SG_ 2154094592 IDATA_AnmTyp8Avl 1;
BA_ "SignalType" SG_ 2154094592 IDATA_AnmTyp8Avl "BLN";
BA_ "PacketOrder" SG_ 2154094592 IDATA_AnmTyp8Avl 9;
BA_ "SignalLongName" SG_ 2154094592 IDATA_AnmTyp8Avl "Interior Dimming Animation Type Available : Animation Type 8 Available";
BA_ "GenSigSendOnInit" SG_ 2154094592 IDATA_AnmTyp7Avl 1;
BA_ "GenSigSendType" SG_ 2154094592 IDATA_AnmTyp7Avl 10;
BA_ "VNSigAllNodes" SG_ 2154094592 IDATA_AnmTyp7Avl 1;
BA_ "SignalType" SG_ 2154094592 IDATA_AnmTyp7Avl "BLN";
BA_ "PacketOrder" SG_ 2154094592 IDATA_AnmTyp7Avl 8;
BA_ "SignalLongName" SG_ 2154094592 IDATA_AnmTyp7Avl "Interior Dimming Animation Type Available : Animation Type 7 Available";
BA_ "GenSigSendOnInit" SG_ 2154094592 IDATA_AnmTyp6Avl 1;
BA_ "GenSigSendType" SG_ 2154094592 IDATA_AnmTyp6Avl 10;
BA_ "VNSigAllNodes" SG_ 2154094592 IDATA_AnmTyp6Avl 1;
BA_ "SignalType" SG_ 2154094592 IDATA_AnmTyp6Avl "BLN";
BA_ "PacketOrder" SG_ 2154094592 IDATA_AnmTyp6Avl 7;
BA_ "SignalLongName" SG_ 2154094592 IDATA_AnmTyp6Avl "Interior Dimming Animation Type Available : Animation Type 6 Available";
BA_ "GenSigSendOnInit" SG_ 2154094592 IDATA_AnmTyp5Avl 1;
BA_ "GenSigSendType" SG_ 2154094592 IDATA_AnmTyp5Avl 10;
BA_ "VNSigAllNodes" SG_ 2154094592 IDATA_AnmTyp5Avl 1;
BA_ "SignalType" SG_ 2154094592 IDATA_AnmTyp5Avl "BLN";
BA_ "PacketOrder" SG_ 2154094592 IDATA_AnmTyp5Avl 6;
BA_ "SignalLongName" SG_ 2154094592 IDATA_AnmTyp5Avl "Interior Dimming Animation Type Available : Animation Type 5 Available";
BA_ "GenSigSendOnInit" SG_ 2154094592 IDATA_AnmTyp4Avl 1;
BA_ "GenSigSendType" SG_ 2154094592 IDATA_AnmTyp4Avl 10;
BA_ "VNSigAllNodes" SG_ 2154094592 IDATA_AnmTyp4Avl 1;
BA_ "SignalType" SG_ 2154094592 IDATA_AnmTyp4Avl "BLN";
BA_ "PacketOrder" SG_ 2154094592 IDATA_AnmTyp4Avl 5;
BA_ "SignalLongName" SG_ 2154094592 IDATA_AnmTyp4Avl "Interior Dimming Animation Type Available : Animation Type 4 Available";
BA_ "GenSigSendOnInit" SG_ 2154094592 IDATA_AnmTyp3Avl 1;
BA_ "GenSigSendType" SG_ 2154094592 IDATA_AnmTyp3Avl 10;
BA_ "VNSigAllNodes" SG_ 2154094592 IDATA_AnmTyp3Avl 1;
BA_ "SignalType" SG_ 2154094592 IDATA_AnmTyp3Avl "BLN";
BA_ "PacketOrder" SG_ 2154094592 IDATA_AnmTyp3Avl 4;
BA_ "SignalLongName" SG_ 2154094592 IDATA_AnmTyp3Avl "Interior Dimming Animation Type Available : Animation Type 3 Available";
BA_ "GenSigSendOnInit" SG_ 2154094592 IDATA_AnmTyp2Avl 1;
BA_ "GenSigSendType" SG_ 2154094592 IDATA_AnmTyp2Avl 10;
BA_ "VNSigAllNodes" SG_ 2154094592 IDATA_AnmTyp2Avl 1;
BA_ "SignalType" SG_ 2154094592 IDATA_AnmTyp2Avl "BLN";
BA_ "PacketOrder" SG_ 2154094592 IDATA_AnmTyp2Avl 3;
BA_ "SignalLongName" SG_ 2154094592 IDATA_AnmTyp2Avl "Interior Dimming Animation Type Available : Animation Type 2 Available";
BA_ "GenSigSendOnInit" SG_ 2154094592 IDATA_AnmTyp1Avl 1;
BA_ "GenSigSendType" SG_ 2154094592 IDATA_AnmTyp1Avl 10;
BA_ "VNSigAllNodes" SG_ 2154094592 IDATA_AnmTyp1Avl 1;
BA_ "SignalType" SG_ 2154094592 IDATA_AnmTyp1Avl "BLN";
BA_ "PacketOrder" SG_ 2154094592 IDATA_AnmTyp1Avl 2;
BA_ "SignalLongName" SG_ 2154094592 IDATA_AnmTyp1Avl "Interior Dimming Animation Type Available : Animation Type 1 Available";
BA_ "GenSigSendOnInit" SG_ 2154094592 IDATA_OffAvl 1;
BA_ "GenSigSendType" SG_ 2154094592 IDATA_OffAvl 10;
BA_ "VNSigAllNodes" SG_ 2154094592 IDATA_OffAvl 1;
BA_ "SignalType" SG_ 2154094592 IDATA_OffAvl "BLN";
BA_ "PacketOrder" SG_ 2154094592 IDATA_OffAvl 1;
BA_ "SignalLongName" SG_ 2154094592 IDATA_OffAvl "Interior Dimming Animation Type Available : Off Available";
BA_ "GenSigSendType" SG_ 2154094592 AdjPdlMotInhbtd 10;
BA_ "VNSigAllNodes" SG_ 2154094592 AdjPdlMotInhbtd 1;
BA_ "SignalType" SG_ 2154094592 AdjPdlMotInhbtd "BLN";
BA_ "SignalLongName" SG_ 2154094592 AdjPdlMotInhbtd "Adjustable Pedal Motion Inhibited";
BA_ "GenSigSendOnInit" SG_ 2154094592 IntDimSeldClrTypStVal 1;
BA_ "GenSigSendType" SG_ 2154094592 IntDimSeldClrTypStVal 10;
BA_ "VNSigAllNodes" SG_ 2154094592 IntDimSeldClrTypStVal 1;
BA_ "SignalType" SG_ 2154094592 IntDimSeldClrTypStVal "ENM";
BA_ "SignalLongName" SG_ 2154094592 IntDimSeldClrTypStVal "Interior Dimming Selected Color Type Setting Value";
BA_ "GenSigSendOnInit" SG_ 2154094592 IntDimSeldAnmTypStVal 1;
BA_ "GenSigSendType" SG_ 2154094592 IntDimSeldAnmTypStVal 10;
BA_ "VNSigAllNodes" SG_ 2154094592 IntDimSeldAnmTypStVal 1;
BA_ "SignalType" SG_ 2154094592 IntDimSeldAnmTypStVal "ENM";
BA_ "SignalLongName" SG_ 2154094592 IntDimSeldAnmTypStVal "Interior Dimming Selected Animation Type Setting Value";
BA_ "GenSigSendOnInit" SG_ 2154094592 IDCTA_ClrTyp30Avl 1;
BA_ "GenSigSendType" SG_ 2154094592 IDCTA_ClrTyp30Avl 10;
BA_ "VNSigAllNodes" SG_ 2154094592 IDCTA_ClrTyp30Avl 1;
BA_ "SignalType" SG_ 2154094592 IDCTA_ClrTyp30Avl "BLN";
BA_ "PacketOrder" SG_ 2154094592 IDCTA_ClrTyp30Avl 31;
BA_ "SignalLongName" SG_ 2154094592 IDCTA_ClrTyp30Avl "Interior Dimming Color Type Available : Color Type 30 Available";
BA_ "GenSigSendOnInit" SG_ 2154094592 IDCTA_ClrTyp29Avl 1;
BA_ "GenSigSendType" SG_ 2154094592 IDCTA_ClrTyp29Avl 10;
BA_ "VNSigAllNodes" SG_ 2154094592 IDCTA_ClrTyp29Avl 1;
BA_ "SignalType" SG_ 2154094592 IDCTA_ClrTyp29Avl "BLN";
BA_ "PacketOrder" SG_ 2154094592 IDCTA_ClrTyp29Avl 30;
BA_ "SignalLongName" SG_ 2154094592 IDCTA_ClrTyp29Avl "Interior Dimming Color Type Available : Color Type 29 Available";
BA_ "GenSigSendOnInit" SG_ 2154094592 IDCTA_ClrTyp28Avl 1;
BA_ "GenSigSendType" SG_ 2154094592 IDCTA_ClrTyp28Avl 10;
BA_ "VNSigAllNodes" SG_ 2154094592 IDCTA_ClrTyp28Avl 1;
BA_ "SignalType" SG_ 2154094592 IDCTA_ClrTyp28Avl "BLN";
BA_ "PacketOrder" SG_ 2154094592 IDCTA_ClrTyp28Avl 29;
BA_ "SignalLongName" SG_ 2154094592 IDCTA_ClrTyp28Avl "Interior Dimming Color Type Available : Color Type 28 Available";
BA_ "GenSigSendOnInit" SG_ 2154094592 IDCTA_ClrTyp27Avl 1;
BA_ "GenSigSendType" SG_ 2154094592 IDCTA_ClrTyp27Avl 10;
BA_ "VNSigAllNodes" SG_ 2154094592 IDCTA_ClrTyp27Avl 1;
BA_ "SignalType" SG_ 2154094592 IDCTA_ClrTyp27Avl "BLN";
BA_ "PacketOrder" SG_ 2154094592 IDCTA_ClrTyp27Avl 28;
BA_ "SignalLongName" SG_ 2154094592 IDCTA_ClrTyp27Avl "Interior Dimming Color Type Available : Color Type 27 Available";
BA_ "GenSigSendOnInit" SG_ 2154094592 IDCTA_ClrTyp26Avl 1;
BA_ "GenSigSendType" SG_ 2154094592 IDCTA_ClrTyp26Avl 10;
BA_ "VNSigAllNodes" SG_ 2154094592 IDCTA_ClrTyp26Avl 1;
BA_ "SignalType" SG_ 2154094592 IDCTA_ClrTyp26Avl "BLN";
BA_ "PacketOrder" SG_ 2154094592 IDCTA_ClrTyp26Avl 27;
BA_ "SignalLongName" SG_ 2154094592 IDCTA_ClrTyp26Avl "Interior Dimming Color Type Available : Color Type 26 Available";
BA_ "GenSigSendOnInit" SG_ 2154094592 IDCTA_ClrTyp25Avl 1;
BA_ "GenSigSendType" SG_ 2154094592 IDCTA_ClrTyp25Avl 10;
BA_ "VNSigAllNodes" SG_ 2154094592 IDCTA_ClrTyp25Avl 1;
BA_ "SignalType" SG_ 2154094592 IDCTA_ClrTyp25Avl "BLN";
BA_ "PacketOrder" SG_ 2154094592 IDCTA_ClrTyp25Avl 26;
BA_ "SignalLongName" SG_ 2154094592 IDCTA_ClrTyp25Avl "Interior Dimming Color Type Available : Color Type 25 Available";
BA_ "GenSigSendOnInit" SG_ 2154094592 IDCTA_ClrTyp24Avl 1;
BA_ "GenSigSendType" SG_ 2154094592 IDCTA_ClrTyp24Avl 10;
BA_ "VNSigAllNodes" SG_ 2154094592 IDCTA_ClrTyp24Avl 1;
BA_ "SignalType" SG_ 2154094592 IDCTA_ClrTyp24Avl "BLN";
BA_ "PacketOrder" SG_ 2154094592 IDCTA_ClrTyp24Avl 25;
BA_ "SignalLongName" SG_ 2154094592 IDCTA_ClrTyp24Avl "Interior Dimming Color Type Available : Color Type 24 Available";
BA_ "GenSigSendOnInit" SG_ 2154094592 IDCTA_ClrTyp23Avl 1;
BA_ "GenSigSendType" SG_ 2154094592 IDCTA_ClrTyp23Avl 10;
BA_ "VNSigAllNodes" SG_ 2154094592 IDCTA_ClrTyp23Avl 1;
BA_ "SignalType" SG_ 2154094592 IDCTA_ClrTyp23Avl "BLN";
BA_ "PacketOrder" SG_ 2154094592 IDCTA_ClrTyp23Avl 24;
BA_ "SignalLongName" SG_ 2154094592 IDCTA_ClrTyp23Avl "Interior Dimming Color Type Available : Color Type 23 Available";
BA_ "GenSigSendOnInit" SG_ 2154094592 IDCTA_ClrTyp22Avl 1;
BA_ "GenSigSendType" SG_ 2154094592 IDCTA_ClrTyp22Avl 10;
BA_ "VNSigAllNodes" SG_ 2154094592 IDCTA_ClrTyp22Avl 1;
BA_ "SignalType" SG_ 2154094592 IDCTA_ClrTyp22Avl "BLN";
BA_ "PacketOrder" SG_ 2154094592 IDCTA_ClrTyp22Avl 23;
BA_ "SignalLongName" SG_ 2154094592 IDCTA_ClrTyp22Avl "Interior Dimming Color Type Available : Color Type 22 Available";
BA_ "GenSigSendOnInit" SG_ 2153979904 RtPrkLtFld 1;
BA_ "GenSigSendType" SG_ 2153979904 RtPrkLtFld 10;
BA_ "VNSigAllNodes" SG_ 2153979904 RtPrkLtFld 1;
BA_ "SignalType" SG_ 2153979904 RtPrkLtFld "BLN";
BA_ "SignalLongName" SG_ 2153979904 RtPrkLtFld "Right Park Light Failed";
BA_ "GenSigSendOnInit" SG_ 2153979904 RtLwBmFld 1;
BA_ "GenSigSendType" SG_ 2153979904 RtLwBmFld 10;
BA_ "VNSigAllNodes" SG_ 2153979904 RtLwBmFld 1;
BA_ "SignalType" SG_ 2153979904 RtLwBmFld "BLN";
BA_ "SignalLongName" SG_ 2153979904 RtLwBmFld "Right Low Beam Failed";
BA_ "GenSigSendOnInit" SG_ 2153979904 RtDytmRunLmpFld 1;
BA_ "GenSigSendType" SG_ 2153979904 RtDytmRunLmpFld 10;
BA_ "VNSigAllNodes" SG_ 2153979904 RtDytmRunLmpFld 1;
BA_ "SignalType" SG_ 2153979904 RtDytmRunLmpFld "BLN";
BA_ "SignalLongName" SG_ 2153979904 RtDytmRunLmpFld "Right Daytime Running Lamp Failed";
BA_ "GenSigSendOnInit" SG_ 2153979904 RtBrkLtFld 1;
BA_ "GenSigSendType" SG_ 2153979904 RtBrkLtFld 10;
BA_ "VNSigAllNodes" SG_ 2153979904 RtBrkLtFld 1;
BA_ "SignalType" SG_ 2153979904 RtBrkLtFld "BLN";
BA_ "SignalLongName" SG_ 2153979904 RtBrkLtFld "Right Brake Light Failed";
BA_ "GenSigSendOnInit" SG_ 2153979904 RRTrnIndLtFld 1;
BA_ "GenSigSendType" SG_ 2153979904 RRTrnIndLtFld 10;
BA_ "VNSigAllNodes" SG_ 2153979904 RRTrnIndLtFld 1;
BA_ "SignalType" SG_ 2153979904 RRTrnIndLtFld "BLN";
BA_ "SignalLongName" SG_ 2153979904 RRTrnIndLtFld "Rear Right Turn Indicator Light Failed";
BA_ "GenSigSendOnInit" SG_ 2153979904 RLTrnIndLtFld 1;
BA_ "GenSigSendType" SG_ 2153979904 RLTrnIndLtFld 10;
BA_ "VNSigAllNodes" SG_ 2153979904 RLTrnIndLtFld 1;
BA_ "SignalType" SG_ 2153979904 RLTrnIndLtFld "BLN";
BA_ "SignalLongName" SG_ 2153979904 RLTrnIndLtFld "Rear Left Turn Indicator Light Failed";
BA_ "GenSigSendOnInit" SG_ 2153979904 LicPltLtFld 1;
BA_ "GenSigSendType" SG_ 2153979904 LicPltLtFld 10;
BA_ "VNSigAllNodes" SG_ 2153979904 LicPltLtFld 1;
BA_ "SignalType" SG_ 2153979904 LicPltLtFld "BLN";
BA_ "SignalLongName" SG_ 2153979904 LicPltLtFld "License Plate Light Failed";
BA_ "GenSigSendOnInit" SG_ 2153979904 LftPrkLtFld 1;
BA_ "GenSigSendType" SG_ 2153979904 LftPrkLtFld 10;
BA_ "VNSigAllNodes" SG_ 2153979904 LftPrkLtFld 1;
BA_ "SignalType" SG_ 2153979904 LftPrkLtFld "BLN";
BA_ "SignalLongName" SG_ 2153979904 LftPrkLtFld "Left Park Light Failed";
BA_ "GenSigSendOnInit" SG_ 2153979904 LftLwBmFld 1;
BA_ "GenSigSendType" SG_ 2153979904 LftLwBmFld 10;
BA_ "VNSigAllNodes" SG_ 2153979904 LftLwBmFld 1;
BA_ "SignalType" SG_ 2153979904 LftLwBmFld "BLN";
BA_ "SignalLongName" SG_ 2153979904 LftLwBmFld "Left Low Beam Failed";
BA_ "GenSigSendOnInit" SG_ 2153979904 LftBrkLtFld 1;
BA_ "GenSigSendType" SG_ 2153979904 LftBrkLtFld 10;
BA_ "VNSigAllNodes" SG_ 2153979904 LftBrkLtFld 1;
BA_ "SignalType" SG_ 2153979904 LftBrkLtFld "BLN";
BA_ "SignalLongName" SG_ 2153979904 LftBrkLtFld "Left Brake Light Failed";
BA_ "GenSigSendOnInit" SG_ 2153979904 FRTrnIndLtFld 1;
BA_ "GenSigSendType" SG_ 2153979904 FRTrnIndLtFld 10;
BA_ "VNSigAllNodes" SG_ 2153979904 FRTrnIndLtFld 1;
BA_ "SignalType" SG_ 2153979904 FRTrnIndLtFld "BLN";
BA_ "SignalLongName" SG_ 2153979904 FRTrnIndLtFld "Front Right Turn Indicator Light Failed";
BA_ "GenSigSendOnInit" SG_ 2153979904 FLTrnIndLtFld 1;
BA_ "GenSigSendType" SG_ 2153979904 FLTrnIndLtFld 10;
BA_ "VNSigAllNodes" SG_ 2153979904 FLTrnIndLtFld 1;
BA_ "SignalType" SG_ 2153979904 FLTrnIndLtFld "BLN";
BA_ "SignalLongName" SG_ 2153979904 FLTrnIndLtFld "Front Left Turn Indicator Light Failed";
BA_ "GenSigSendOnInit" SG_ 2153979904 CHMSLFld 1;
BA_ "GenSigSendType" SG_ 2153979904 CHMSLFld 10;
BA_ "VNSigAllNodes" SG_ 2153979904 CHMSLFld 1;
BA_ "SignalType" SG_ 2153979904 CHMSLFld "BLN";
BA_ "SignalLongName" SG_ 2153979904 CHMSLFld "Center High Mounted Stop Light Failed";
BA_ "GenSigSendOnInit" SG_ 2153979904 LftDytmRunLmpFld 1;
BA_ "GenSigSendType" SG_ 2153979904 LftDytmRunLmpFld 10;
BA_ "VNSigAllNodes" SG_ 2153979904 LftDytmRunLmpFld 1;
BA_ "SignalType" SG_ 2153979904 LftDytmRunLmpFld "BLN";
BA_ "SignalLongName" SG_ 2153979904 LftDytmRunLmpFld "Left Daytime Running Lamp Failed";
BA_ "GenSigSendOnInit" SG_ 2153979904 RvsLtFld 1;
BA_ "GenSigSendType" SG_ 2153979904 RvsLtFld 10;
BA_ "VNSigAllNodes" SG_ 2153979904 RvsLtFld 1;
BA_ "SignalType" SG_ 2153979904 RvsLtFld "BLN";
BA_ "SignalLongName" SG_ 2153979904 RvsLtFld "Reverse Light Failed";
BA_ "GenSigSendOnInit" SG_ 2153979904 RFgLtFld 1;
BA_ "GenSigSendType" SG_ 2153979904 RFgLtFld 10;
BA_ "VNSigAllNodes" SG_ 2153979904 RFgLtFld 1;
BA_ "SignalType" SG_ 2153979904 RFgLtFld "BLN";
BA_ "SignalLongName" SG_ 2153979904 RFgLtFld "Rear Fog Light Failed";
BA_ "GenSigSendType" SG_ 2150154240 PsvEntVehIdExt 12;
BA_ "GenSigDeltaValue" SG_ 2150154240 PsvEntVehIdExt 1;
BA_ "VNSigAllNodes" SG_ 2150154240 PsvEntVehIdExt 1;
BA_ "SignalType" SG_ 2150154240 PsvEntVehIdExt "UNM";
BA_ "SignalLongName" SG_ 2150154240 PsvEntVehIdExt "Passive Entry Vehicle Identifier Extended";
BA_ "GenSigSendType" SG_ 2150154240 PsvEntChlngRply 12;
BA_ "GenSigDeltaValue" SG_ 2150154240 PsvEntChlngRply 1;
BA_ "VNSigAllNodes" SG_ 2150154240 PsvEntChlngRply 1;
BA_ "SignalType" SG_ 2150154240 PsvEntChlngRply "UNM";
BA_ "SignalLongName" SG_ 2150154240 PsvEntChlngRply "Passive Entry Challenge Reply";
BA_ "GenSigSendOnInit" SG_ 2151497728 TireLFPrs 1;
BA_ "GenSigSendType" SG_ 2151497728 TireLFPrs 12;
BA_ "GenSigDeltaValue" SG_ 2151497728 TireLFPrs 1;
BA_ "VNSigAllNodes" SG_ 2151497728 TireLFPrs 1;
BA_ "SignalType" SG_ 2151497728 TireLFPrs "UNM";
BA_ "SignalLongName" SG_ 2151497728 TireLFPrs "Tire Left Front Pressure";
BA_ "GenSigStartValue" SG_ 2151497728 TireLFPrs 255;
BA_ "GenSigSendOnInit" SG_ 2151497728 TireLFPrsStat 1;
BA_ "GenSigSendType" SG_ 2151497728 TireLFPrsStat 10;
BA_ "VNSigAllNodes" SG_ 2151497728 TireLFPrsStat 1;
BA_ "SignalType" SG_ 2151497728 TireLFPrsStat "ENM";
BA_ "SignalLongName" SG_ 2151497728 TireLFPrsStat "Tire Left Front Pressure Status";
BA_ "GenSigSendOnInit" SG_ 2151497728 TireLFPrsV 1;
BA_ "GenSigSendType" SG_ 2151497728 TireLFPrsV 10;
BA_ "VNSigAllNodes" SG_ 2151497728 TireLFPrsV 1;
BA_ "SignalType" SG_ 2151497728 TireLFPrsV "ENM";
BA_ "SignalLongName" SG_ 2151497728 TireLFPrsV "Tire Left Front Pressure Validity";
BA_ "GenSigSendOnInit" SG_ 2151497728 TireLRPrs 1;
BA_ "GenSigSendType" SG_ 2151497728 TireLRPrs 12;
BA_ "GenSigDeltaValue" SG_ 2151497728 TireLRPrs 1;
BA_ "VNSigAllNodes" SG_ 2151497728 TireLRPrs 1;
BA_ "SignalType" SG_ 2151497728 TireLRPrs "UNM";
BA_ "SignalLongName" SG_ 2151497728 TireLRPrs "Tire Left Rear Pressure";
BA_ "GenSigStartValue" SG_ 2151497728 TireLRPrs 255;
BA_ "GenSigSendOnInit" SG_ 2151497728 TireLRPrsStat 1;
BA_ "GenSigSendType" SG_ 2151497728 TireLRPrsStat 10;
BA_ "VNSigAllNodes" SG_ 2151497728 TireLRPrsStat 1;
BA_ "SignalType" SG_ 2151497728 TireLRPrsStat "ENM";
BA_ "SignalLongName" SG_ 2151497728 TireLRPrsStat "Tire Left Rear Pressure Status";
BA_ "GenSigSendOnInit" SG_ 2151497728 TireLRPrsV 1;
BA_ "GenSigSendType" SG_ 2151497728 TireLRPrsV 10;
BA_ "VNSigAllNodes" SG_ 2151497728 TireLRPrsV 1;
BA_ "SignalType" SG_ 2151497728 TireLRPrsV "ENM";
BA_ "SignalLongName" SG_ 2151497728 TireLRPrsV "Tire Left Rear Pressure Validity";
BA_ "GenSigSendOnInit" SG_ 2151497728 TireRFPrs 1;
BA_ "GenSigSendType" SG_ 2151497728 TireRFPrs 12;
BA_ "GenSigDeltaValue" SG_ 2151497728 TireRFPrs 1;
BA_ "VNSigAllNodes" SG_ 2151497728 TireRFPrs 1;
BA_ "SignalType" SG_ 2151497728 TireRFPrs "UNM";
BA_ "SignalLongName" SG_ 2151497728 TireRFPrs "Tire Right Front Pressure";
BA_ "GenSigStartValue" SG_ 2151497728 TireRFPrs 255;
BA_ "GenSigSendOnInit" SG_ 2151497728 TireRFPrsStat 1;
BA_ "GenSigSendType" SG_ 2151497728 TireRFPrsStat 10;
BA_ "VNSigAllNodes" SG_ 2151497728 TireRFPrsStat 1;
BA_ "SignalType" SG_ 2151497728 TireRFPrsStat "ENM";
BA_ "SignalLongName" SG_ 2151497728 TireRFPrsStat "Tire Right Front Pressure Status";
BA_ "GenSigSendOnInit" SG_ 2151497728 TireRFPrsV 1;
BA_ "GenSigSendType" SG_ 2151497728 TireRFPrsV 10;
BA_ "VNSigAllNodes" SG_ 2151497728 TireRFPrsV 1;
BA_ "SignalType" SG_ 2151497728 TireRFPrsV "ENM";
BA_ "SignalLongName" SG_ 2151497728 TireRFPrsV "Tire Right Front Pressure Validity";
BA_ "GenSigSendOnInit" SG_ 2151497728 TireRRPrs 1;
BA_ "GenSigSendType" SG_ 2151497728 TireRRPrs 12;
BA_ "GenSigDeltaValue" SG_ 2151497728 TireRRPrs 1;
BA_ "VNSigAllNodes" SG_ 2151497728 TireRRPrs 1;
BA_ "SignalType" SG_ 2151497728 TireRRPrs "UNM";
BA_ "SignalLongName" SG_ 2151497728 TireRRPrs "Tire Right Rear Pressure";
BA_ "GenSigStartValue" SG_ 2151497728 TireRRPrs 255;
BA_ "GenSigSendOnInit" SG_ 2151497728 TireRRPrsStat 1;
BA_ "GenSigSendType" SG_ 2151497728 TireRRPrsStat 10;
BA_ "VNSigAllNodes" SG_ 2151497728 TireRRPrsStat 1;
BA_ "SignalType" SG_ 2151497728 TireRRPrsStat "ENM";
BA_ "SignalLongName" SG_ 2151497728 TireRRPrsStat "Tire Right Rear Pressure Status";
BA_ "GenSigSendOnInit" SG_ 2151497728 TireRRPrsV 1;
BA_ "GenSigSendType" SG_ 2151497728 TireRRPrsV 10;
BA_ "VNSigAllNodes" SG_ 2151497728 TireRRPrsV 1;
BA_ "SignalType" SG_ 2151497728 TireRRPrsV "ENM";
BA_ "SignalLongName" SG_ 2151497728 TireRRPrsV "Tire Right Rear Pressure Validity";
BA_ "GenSigSendOnInit" SG_ 2151219200 RemStrtSt 2;
BA_ "GenSigSendType" SG_ 2151219200 RemStrtSt 10;
BA_ "VNSigAllNodes" SG_ 2151219200 RemStrtSt 1;
BA_ "SignalType" SG_ 2151219200 RemStrtSt "ENM";
BA_ "SignalLongName" SG_ 2151219200 RemStrtSt "Remote Start Status";
BA_ "GenSigSendType" SG_ 2151219200 RmVehStrRq 10;
BA_ "VNSigAllNodes" SG_ 2151219200 RmVehStrRq 1;
BA_ "SignalType" SG_ 2151219200 RmVehStrRq "ENM";
BA_ "SignalLongName" SG_ 2151219200 RmVehStrRq "Remote Vehicle Start Request";
BA_ "GenSigSendType" SG_ 2151235584 EhnSrvImmbComRst 10;
BA_ "VNSigAllNodes" SG_ 2151235584 EhnSrvImmbComRst 1;
BA_ "SignalType" SG_ 2151235584 EhnSrvImmbComRst "BLN";
BA_ "SignalLongName" SG_ 2151235584 EhnSrvImmbComRst "Enhanced Services Immobilization Command Reset";
BA_ "GenSigSendType" SG_ 2151235584 NmofPrgKFbExtd 12;
BA_ "GenSigDeltaValue" SG_ 2151235584 NmofPrgKFbExtd 1;
BA_ "VNSigAllNodes" SG_ 2151235584 NmofPrgKFbExtd 1;
BA_ "SignalType" SG_ 2151235584 NmofPrgKFbExtd "UNM";
BA_ "SignalLongName" SG_ 2151235584 NmofPrgKFbExtd "Number of Programmed Keyfobs Extended";
BA_ "GenSigSendType" SG_ 2151235584 AlcKyIIncmIndOn 10;
BA_ "VNSigAllNodes" SG_ 2151235584 AlcKyIIncmIndOn 1;
BA_ "SignalType" SG_ 2151235584 AlcKyIIncmIndOn "BLN";
BA_ "SignalLongName" SG_ 2151235584 AlcKyIIncmIndOn "Alco Key Incomplete Indication On";
BA_ "GenSigSendType" SG_ 2151235584 VehSecAuthnSesComp 10;
BA_ "VNSigAllNodes" SG_ 2151235584 VehSecAuthnSesComp 1;
BA_ "SignalType" SG_ 2151235584 VehSecAuthnSesComp "BLN";
BA_ "SignalLongName" SG_ 2151235584 VehSecAuthnSesComp "Vehicle Security Authentication Session Completed";
BA_ "GenSigSendType" SG_ 2151235584 VTDTmprDetected 10;
BA_ "VNSigAllNodes" SG_ 2151235584 VTDTmprDetected 1;
BA_ "SignalType" SG_ 2151235584 VTDTmprDetected "BLN";
BA_ "SignalLongName" SG_ 2151235584 VTDTmprDetected "Vehicle Theft Deterrent Tamper Detected";
BA_ "GenSigSendType" SG_ 2151235584 VehSecSysFldIO 10;
BA_ "VNSigAllNodes" SG_ 2151235584 VehSecSysFldIO 1;
BA_ "SignalType" SG_ 2151235584 VehSecSysFldIO "BLN";
BA_ "SignalLongName" SG_ 2151235584 VehSecSysFldIO "Vehicle Security System Failed Indication On";
BA_ "GenSigSendType" SG_ 2151235584 VehSecStrgColLckPwdV 10;
BA_ "VNSigAllNodes" SG_ 2151235584 VehSecStrgColLckPwdV 1;
BA_ "SignalType" SG_ 2151235584 VehSecStrgColLckPwdV "ENM";
BA_ "SignalLongName" SG_ 2151235584 VehSecStrgColLckPwdV "Vehicle Security Steering Column Lock Password Validity";
BA_ "GenSigSendType" SG_ 2151235584 VehSecStrgColLckPwd 12;
BA_ "GenSigDeltaValue" SG_ 2151235584 VehSecStrgColLckPwd 1;
BA_ "VNSigAllNodes" SG_ 2151235584 VehSecStrgColLckPwd 1;
BA_ "SignalType" SG_ 2151235584 VehSecStrgColLckPwd "UNM";
BA_ "SignalLongName" SG_ 2151235584 VehSecStrgColLckPwd "Vehicle Security Steering Column Lock Password";
BA_ "GenSigSendOnInit" SG_ 2151235584 VhSecNImmoIndRq 1;
BA_ "GenSigSendType" SG_ 2151235584 VhSecNImmoIndRq 10;
BA_ "VNSigAllNodes" SG_ 2151235584 VhSecNImmoIndRq 1;
BA_ "SignalType" SG_ 2151235584 VhSecNImmoIndRq "ENM";
BA_ "SignalLongName" SG_ 2151235584 VhSecNImmoIndRq "Vehicle Security Non Immobilizer Indication Request";
BA_ "GenSigSendType" SG_ 2151235584 StrgColLckCmd 10;
BA_ "VNSigAllNodes" SG_ 2151235584 StrgColLckCmd 1;
BA_ "SignalType" SG_ 2151235584 StrgColLckCmd "ENM";
BA_ "SignalLongName" SG_ 2151235584 StrgColLckCmd "Steering Column Lock Command";
BA_ "GenSigSendType" SG_ 2151235584 DrIdDevLrnd 10;
BA_ "VNSigAllNodes" SG_ 2151235584 DrIdDevLrnd 1;
BA_ "SignalType" SG_ 2151235584 DrIdDevLrnd "ENM";
BA_ "SignalLongName" SG_ 2151235584 DrIdDevLrnd "Driver Identification Device Learned";
BA_ "GenSigSendType" SG_ 2151235584 IllDrIdDevDtctd 10;
BA_ "VNSigAllNodes" SG_ 2151235584 IllDrIdDevDtctd 1;
BA_ "SignalType" SG_ 2151235584 IllDrIdDevDtctd "BLN";
BA_ "SignalLongName" SG_ 2151235584 IllDrIdDevDtctd "Illegitimate Driver Identification Device Detected";
BA_ "GenSigSendType" SG_ 2151235584 EhnSrvEngImmStat 10;
BA_ "VNSigAllNodes" SG_ 2151235584 EhnSrvEngImmStat 1;
BA_ "SignalType" SG_ 2151235584 EhnSrvEngImmStat "ENM";
BA_ "SignalLongName" SG_ 2151235584 EhnSrvEngImmStat "Enhanced Services Engine Immobilized Status";
BA_ "GenSigSendType" SG_ 2151235584 ClmSysBkupFlrIndOn 10;
BA_ "VNSigAllNodes" SG_ 2151235584 ClmSysBkupFlrIndOn 1;
BA_ "SignalType" SG_ 2151235584 ClmSysBkupFlrIndOn "BLN";
BA_ "SignalLongName" SG_ 2151235584 ClmSysBkupFlrIndOn "Column System Backup Failure Indication On";
BA_ "GenSigSendType" SG_ 2151235584 VehStatStAtv 10;
BA_ "VNSigAllNodes" SG_ 2151235584 VehStatStAtv 1;
BA_ "SignalType" SG_ 2151235584 VehStatStAtv "BLN";
BA_ "SignalLongName" SG_ 2151235584 VehStatStAtv "Vehicle Stationary Status Active";
BA_REL_ "GenSigSuprvResp" BU_SG_REL_ MSM_LS SG_ 2151432192 ACCHptcStVbnRqSeqN 1;
BA_REL_ "GenSigSuprvResp" BU_SG_REL_ MSM_LS SG_ 2151432192 ACCHptcStVbnReq 1;
BA_REL_ "GenSigSuprvResp" BU_SG_REL_ ECC_LS SG_ 2154807296 ESCMHiEleclLdReqAct 1;
BA_REL_ "GenSigSuprvResp" BU_SG_REL_ ECC_LS SG_ 2154807296 EASSI_UnsdRsrvd2 1;
BA_REL_ "GenSigSuprvResp" BU_SG_REL_ ECC_LS SG_ 2154807296 EASSI_StlDetd 1;
BA_REL_ "GenSigSuprvResp" BU_SG_REL_ ECC_LS SG_ 2154807296 EASSI_TrqDetd 1;
BA_REL_ "GenSigSuprvResp" BU_SG_REL_ ECC_LS SG_ 2154807296 EASSI_FuelReqOn 1;
BA_REL_ "GenSigSuprvResp" BU_SG_REL_ ECC_LS SG_ 2154807296 EASSI_StrtTyp 1;
BA_REL_ "GenSigSuprvResp" BU_SG_REL_ ECC_LS SG_ 2154807296 EASSI_StrtStpSt 1;
BA_REL_ "GenSigSuprvResp" BU_SG_REL_ ECC_LS SG_ 2154807296 EASSI_TorqDetdIndet 1;
BA_REL_ "GenSigSuprvResp" BU_SG_REL_ ECC_LS SG_ 2154807296 EngAutoStpNotProb 1;
BA_REL_ "GenSigSuprvResp" BU_SG_REL_ PTM_LS SG_ 2154078208 RRWndPosStat 1;
BA_REL_ "GenSigSuprvResp" BU_SG_REL_ PTM_LS SG_ 2154078208 PsWndPosStat 1;
BA_REL_ "GenSigSuprvResp" BU_SG_REL_ PTM_LS SG_ 2154078208 LRWndPosStat 1;
BA_REL_ "GenSigSuprvResp" BU_SG_REL_ PTM_LS SG_ 2154078208 DrvWndPosStat 1;
BA_REL_ "GenSigSuprvResp" BU_SG_REL_ PEPS_LS SG_ 2155413504 PsvLckngReqd 1;
BA_REL_ "GenSigSuprvResp" BU_SG_REL_ PEPS_LS SG_ 2155413504 PsvApprchVehId 1;
BA_REL_ "GenSigSuprvResp" BU_SG_REL_ SDM_LS SG_ 2150367232 LrnEnvIdSt 1;
BA_REL_ "GenSigSuprvResp" BU_SG_REL_ SDM_LS SG_ 2150367232 LrnEnvId 1;
BA_REL_ "GenSigSuprvResp" BU_SG_REL_ SDM_LS SG_ 2150367232 ImoId 1;
BA_REL_ "GenSigSuprvResp" BU_SG_REL_ SDM_LS SG_ 2150367232 ImoIdSt 1;
BA_REL_ "GenSigSuprvResp" BU_SG_REL_ SDM_LS SG_ 2151309312 InflRestId 1;
BA_REL_ "GenSigSuprvResp" BU_SG_REL_ VIS2_LS SG_ 2155347968 BrkSysMalFuncIndOn 1;
BA_REL_ "GenSigSuprvResp" BU_SG_REL_ ECC_LS SG_ 2150432768 EngManfldAirTempCrtd 1;
BA_REL_ "GenSigSuprvResp" BU_SG_REL_ ECC_LS SG_ 2155249664 RRHCSMInd3 1;
BA_REL_ "GenSigSuprvResp" BU_SG_REL_ BCM_LS SG_ 2155249664 RRHCSMInd3 1;
BA_REL_ "GenSigSuprvResp" BU_SG_REL_ ECC_LS SG_ 2155249664 RRHCSMInd2 1;
BA_REL_ "GenSigSuprvResp" BU_SG_REL_ BCM_LS SG_ 2155249664 RRHCSMInd2 1;
BA_REL_ "GenSigSuprvResp" BU_SG_REL_ ECC_LS SG_ 2155249664 RRHCSMInd1 1;
BA_REL_ "GenSigSuprvResp" BU_SG_REL_ BCM_LS SG_ 2155249664 RRHCSMInd1 1;
BA_REL_ "GenSigSuprvResp" BU_SG_REL_ ECC_LS SG_ 2155249664 RRHCSMIndReq 1;
BA_REL_ "GenSigSuprvResp" BU_SG_REL_ BCM_LS SG_ 2155249664 RRHCSMIndReq 1;
BA_REL_ "GenSigSuprvResp" BU_SG_REL_ ECC_LS SG_ 2155249664 RRHCSLSeatLev5 1;
BA_REL_ "GenSigSuprvResp" BU_SG_REL_ BCM_LS SG_ 2155249664 RRHCSLSeatLev5 1;
BA_REL_ "GenSigSuprvResp" BU_SG_REL_ ECC_LS SG_ 2155249664 RRHCSLSeatLev4 1;
BA_REL_ "GenSigSuprvResp" BU_SG_REL_ BCM_LS SG_ 2155249664 RRHCSLSeatLev4 1;
BA_REL_ "GenSigSuprvResp" BU_SG_REL_ ECC_LS SG_ 2155249664 RRHCSLSeatLev3 1;
BA_REL_ "GenSigSuprvResp" BU_SG_REL_ BCM_LS SG_ 2155249664 RRHCSLSeatLev3 1;
BA_REL_ "GenSigSuprvResp" BU_SG_REL_ ECC_LS SG_ 2155249664 RRHCSLSeatLev2 1;
BA_REL_ "GenSigSuprvResp" BU_SG_REL_ BCM_LS SG_ 2155249664 RRHCSLSeatLev2 1;
BA_REL_ "GenSigSuprvResp" BU_SG_REL_ ECC_LS SG_ 2155249664 RRHCSLSeatLev1 1;
BA_REL_ "GenSigSuprvResp" BU_SG_REL_ BCM_LS SG_ 2155249664 RRHCSLSeatLev1 1;
BA_REL_ "GenSigSuprvResp" BU_SG_REL_ ECC_LS SG_ 2155249664 RRHCSLIndReq 1;
BA_REL_ "GenSigSuprvResp" BU_SG_REL_ BCM_LS SG_ 2155249664 RRHCSLIndReq 1;
BA_REL_ "GenSigSuprvResp" BU_SG_REL_ ECC_LS SG_ 2155249664 RLHCSMInd3 1;
BA_REL_ "GenSigSuprvResp" BU_SG_REL_ BCM_LS SG_ 2155249664 RLHCSMInd3 1;
BA_REL_ "GenSigSuprvResp" BU_SG_REL_ ECC_LS SG_ 2155249664 RLHCSMInd2 1;
BA_REL_ "GenSigSuprvResp" BU_SG_REL_ BCM_LS SG_ 2155249664 RLHCSMInd2 1;
BA_REL_ "GenSigSuprvResp" BU_SG_REL_ ECC_LS SG_ 2155249664 RLHCSMInd1 1;
BA_REL_ "GenSigSuprvResp" BU_SG_REL_ BCM_LS SG_ 2155249664 RLHCSMInd1 1;
BA_REL_ "GenSigSuprvResp" BU_SG_REL_ ECC_LS SG_ 2155249664 RLHCSMIndReq 1;
BA_REL_ "GenSigSuprvResp" BU_SG_REL_ BCM_LS SG_ 2155249664 RLHCSMIndReq 1;
BA_REL_ "GenSigSuprvResp" BU_SG_REL_ ECC_LS SG_ 2155249664 RLHCSLSeatLev5 1;
BA_REL_ "GenSigSuprvResp" BU_SG_REL_ BCM_LS SG_ 2155249664 RLHCSLSeatLev5 1;
BA_REL_ "GenSigSuprvResp" BU_SG_REL_ ECC_LS SG_ 2155249664 RLHCSLSeatLev4 1;
BA_REL_ "GenSigSuprvResp" BU_SG_REL_ BCM_LS SG_ 2155249664 RLHCSLSeatLev4 1;
BA_REL_ "GenSigSuprvResp" BU_SG_REL_ ECC_LS SG_ 2155249664 RLHCSLSeatLev3 1;
BA_REL_ "GenSigSuprvResp" BU_SG_REL_ BCM_LS SG_ 2155249664 RLHCSLSeatLev3 1;
BA_REL_ "GenSigSuprvResp" BU_SG_REL_ ECC_LS SG_ 2155249664 RLHCSLSeatLev2 1;
BA_REL_ "GenSigSuprvResp" BU_SG_REL_ BCM_LS SG_ 2155249664 RLHCSLSeatLev2 1;
BA_REL_ "GenSigSuprvResp" BU_SG_REL_ ECC_LS SG_ 2155249664 RLHCSLSeatLev1 1;
BA_REL_ "GenSigSuprvResp" BU_SG_REL_ BCM_LS SG_ 2155249664 RLHCSLSeatLev1 1;
BA_REL_ "GenSigSuprvResp" BU_SG_REL_ ECC_LS SG_ 2155249664 RLHCSLIndReq 1;
BA_REL_ "GenSigSuprvResp" BU_SG_REL_ BCM_LS SG_ 2155249664 RLHCSLIndReq 1;
BA_REL_ "GenSigSuprvResp" BU_SG_REL_ SDM_LS SG_ 2155184128 CrsCntrlSwStCanSwAct 1;
BA_REL_ "GenSigVDAFailResp" BU_SG_REL_ SDM_LS SG_ 2155184128 CrsCntrlSwStCanSwAct 1;
BA_REL_ "GenSigVDAFailComment" BU_SG_REL_ SDM_LS SG_ 2155184128 CrsCntrlSwStCanSwAct "Engine Virtual Device Availability";
BA_REL_ "GenSigSuprvResp" BU_SG_REL_ SDM_LS SG_ 2155184128 CrsCntrlSwStSwDataIntgty 1;
BA_REL_ "GenSigVDAFailResp" BU_SG_REL_ SDM_LS SG_ 2155184128 CrsCntrlSwStSwDataIntgty 1;
BA_REL_ "GenSigVDAFailComment" BU_SG_REL_ SDM_LS SG_ 2155184128 CrsCntrlSwStSwDataIntgty "Engine Virtual Device Availability";
BA_REL_ "GenSigSuprvResp" BU_SG_REL_ SDM_LS SG_ 2155184128 CrsCntrlSwStSpdInSwAct 1;
BA_REL_ "GenSigVDAFailResp" BU_SG_REL_ SDM_LS SG_ 2155184128 CrsCntrlSwStSpdInSwAct 1;
BA_REL_ "GenSigVDAFailComment" BU_SG_REL_ SDM_LS SG_ 2155184128 CrsCntrlSwStSpdInSwAct "Engine Virtual Device Availability";
BA_REL_ "GenSigSuprvResp" BU_SG_REL_ SDM_LS SG_ 2155184128 CrsCntrlSwStSpDcSwAct 1;
BA_REL_ "GenSigVDAFailResp" BU_SG_REL_ SDM_LS SG_ 2155184128 CrsCntrlSwStSpDcSwAct 1;
BA_REL_ "GenSigVDAFailComment" BU_SG_REL_ SDM_LS SG_ 2155184128 CrsCntrlSwStSpDcSwAct "Engine Virtual Device Availability";
BA_REL_ "GenSigSuprvResp" BU_SG_REL_ SDM_LS SG_ 2155184128 CrsCntrlSwStSetSwAct 1;
BA_REL_ "GenSigVDAFailResp" BU_SG_REL_ SDM_LS SG_ 2155184128 CrsCntrlSwStSetSwAct 1;
BA_REL_ "GenSigVDAFailComment" BU_SG_REL_ SDM_LS SG_ 2155184128 CrsCntrlSwStSetSwAct "Engine Virtual Device Availability";
BA_REL_ "GenSigSuprvResp" BU_SG_REL_ SDM_LS SG_ 2155184128 CrsCntrlSwStResSwAct 1;
BA_REL_ "GenSigVDAFailResp" BU_SG_REL_ SDM_LS SG_ 2155184128 CrsCntrlSwStResSwAct 1;
BA_REL_ "GenSigVDAFailComment" BU_SG_REL_ SDM_LS SG_ 2155184128 CrsCntrlSwStResSwAct "Engine Virtual Device Availability";
BA_REL_ "GenSigSuprvResp" BU_SG_REL_ SDM_LS SG_ 2155184128 CrsCntrlSwStOnSwAct 1;
BA_REL_ "GenSigVDAFailResp" BU_SG_REL_ SDM_LS SG_ 2155184128 CrsCntrlSwStOnSwAct 1;
BA_REL_ "GenSigVDAFailComment" BU_SG_REL_ SDM_LS SG_ 2155184128 CrsCntrlSwStOnSwAct "Engine Virtual Device Availability";
BA_REL_ "GenSigSuprvResp" BU_SG_REL_ VIS2_LS SG_ 2155184128 CrsCntAtv 1;
BA_REL_ "GenSigSuprvResp" BU_SG_REL_ SDM_LS SG_ 2155184128 CrsCntAtv 1;
BA_REL_ "GenSigVDAFailResp" BU_SG_REL_ SDM_LS SG_ 2155184128 CrsCntAtv 1;
BA_REL_ "GenSigVDAFailComment" BU_SG_REL_ SDM_LS SG_ 2155184128 CrsCntAtv "Engine Virtual Device Availability";
BA_REL_ "GenSigSuprvResp" BU_SG_REL_ PEPS_LS SG_ 2154921984 RFRmtCntFobNm 1;
BA_REL_ "GenSigSuprvResp" BU_SG_REL_ PEPS_LS SG_ 2154921984 RFRmtCntrlFobFnc 1;
BA_REL_ "GenSigSuprvResp" BU_SG_REL_ PEPS_LS SG_ 2154921984 RFRmtCntFobBatLw 1;
BA_REL_ "GenSigSuprvResp" BU_SG_REL_ ECC_LS SG_ 2154962944 PassHCSMInd3 1;
BA_REL_ "GenSigSuprvResp" BU_SG_REL_ ECC_LS SG_ 2154962944 PassHCSMInd2 1;
BA_REL_ "GenSigSuprvResp" BU_SG_REL_ ECC_LS SG_ 2154962944 PassHCSMInd1 1;
BA_REL_ "GenSigSuprvResp" BU_SG_REL_ ECC_LS SG_ 2154962944 PassHCSMIndReq 1;
BA_REL_ "GenSigSuprvResp" BU_SG_REL_ ECC_LS SG_ 2154962944 PassHCSLSeatLev5 1;
BA_REL_ "GenSigSuprvResp" BU_SG_REL_ ECC_LS SG_ 2154962944 PassHCSLSeatLev4 1;
BA_REL_ "GenSigSuprvResp" BU_SG_REL_ ECC_LS SG_ 2154962944 PassHCSLSeatLev3 1;
BA_REL_ "GenSigSuprvResp" BU_SG_REL_ ECC_LS SG_ 2154962944 PassHCSLSeatLev2 1;
BA_REL_ "GenSigSuprvResp" BU_SG_REL_ ECC_LS SG_ 2154962944 PassHCSLSeatLev1 1;
BA_REL_ "GenSigSuprvResp" BU_SG_REL_ ECC_LS SG_ 2154962944 PassHCSLIndReq 1;
BA_REL_ "GenSigSuprvResp" BU_SG_REL_ ECC_LS SG_ 2154962944 DrvHCSMInd1 1;
BA_REL_ "GenSigSuprvResp" BU_SG_REL_ ECC_LS SG_ 2154962944 DrvHCSMIndReq 1;
BA_REL_ "GenSigSuprvResp" BU_SG_REL_ ECC_LS SG_ 2154962944 DrvHCSMInd3 1;
BA_REL_ "GenSigSuprvResp" BU_SG_REL_ ECC_LS SG_ 2154962944 DrvHCSMInd2 1;
BA_REL_ "GenSigSuprvResp" BU_SG_REL_ ECC_LS SG_ 2154962944 DrvHCSLSeatLev5 1;
BA_REL_ "GenSigSuprvResp" BU_SG_REL_ ECC_LS SG_ 2154962944 DrvHCSLSeatLev4 1;
BA_REL_ "GenSigSuprvResp" BU_SG_REL_ ECC_LS SG_ 2154962944 DrvHCSLSeatLev3 1;
BA_REL_ "GenSigSuprvResp" BU_SG_REL_ ECC_LS SG_ 2154962944 DrvHCSLSeatLev2 1;
BA_REL_ "GenSigSuprvResp" BU_SG_REL_ ECC_LS SG_ 2154962944 DrvHCSLSeatLev1 1;
BA_REL_ "GenSigSuprvResp" BU_SG_REL_ ECC_LS SG_ 2154962944 DrvHCSLIndReq 1;
BA_REL_ "GenSigSuprvResp" BU_SG_REL_ MSM_LS SG_ 2154905600 DrvSeatPrsMemID 1;
BA_REL_ "GenSigSuprvResp" BU_SG_REL_ MSM_LS SG_ 2154905600 DrId 1;
BA_REL_ "GenSigSuprvResp" BU_SG_REL_ EOCM_F_LS SG_ 2154905600 DrId 1;
BA_REL_ "GenSigSuprvResp" BU_SG_REL_ MSM_LS SG_ 2154094592 AdjPdlMotInhbtd 1;
BA_REL_ "GenSigSuprvResp" BU_SG_REL_ PTM_LS SG_ 2151219200 RemStrtSt 1;
BA_REL_ "GenSigSuprvResp" BU_SG_REL_ MSM_LS SG_ 2151219200 RemStrtSt 1;
BA_REL_ "GenSigSuprvResp" BU_SG_REL_ ECC_LS SG_ 2151219200 RemStrtSt 1;
BA_REL_ "GenSigSuprvResp" BU_SG_REL_ PEPS_LS SG_ 2151235584 NmofPrgKFbExtd 1;
VAL_ 2149761024 PsngStPerfMdCsCrStVal 7 "Auto" 6 "Performance Mode 6" 5 "Performance Mode 5" 4 "Performance Mode 4" 3 "Performance Mode 3" 2 "Performance Mode 2" 1 "Performance Mode 1" 0 "No Action" ;
VAL_ 2149761024 PsngStPerfMdCsStAvl 1 "true" 0 "false" ;
VAL_ 2149761024 ElvtdIdlCstCrStVal 0 "No Action" 1 "Off" 2 "On" ;
VAL_ 2149761024 ElvtdIdlCstStAvl 1 "true" 0 "false" ;
VAL_ 2149761024 TCTPIR_DrvNotfn 15 "Indication 15" 14 "Indication 14" 13 "Indication 13" 12 "Indication 12" 11 "Indication 11" 10 "Indication 10" 9 "Indication 9" 8 "Indication 8" 7 "Indication 7" 6 "Indication 6" 5 "Indication 5" 4 "Indication 4" 3 "Indication 3" 2 "Indication 2" 1 "Indication 1" 0 "No Indication" ;
VAL_ 2149761024 TrlrStabAstActIO 1 "true" 0 "false" ;
VAL_ 2149761024 PerfTrcCrnExStngVal 0 "No Action" 1 "Off" 2 "Setting 1" 3 "Setting 2" 4 "Setting 3" 5 "Setting 4" 6 "Setting 5" 7 "Setting 6" 8 "Setting 7" 9 "Setting 8" 10 "Setting 9" 11 "Setting 10" 12 "Setting 11" 13 "Setting 12" 14 "Setting 13" 15 "Setting 14" 16 "Setting 15" ;
VAL_ 2149761024 ActVehAccelV 1 "Invalid" 0 "Valid" ;
VAL_ 2151481344 HdUpDsplyUnblIO 1 "true" 0 "false" ;
VAL_ 2151481344 FSRACCFrstRsmPrssIO 1 "true" 0 "false" ;
VAL_ 2151481344 FrtRdrBlckdIO 1 "true" 0 "false" ;
VAL_ 2151481344 ShtToPrkBfExtngVehIO 1 "true" 0 "false" ;
VAL_ 2151481344 AutoBrkRlsIO 1 "true" 0 "false" ;
VAL_ 2155929600 DslExhFldDiagWrnIdRq 0 "No Indication" 1 "Warning Level 1" 2 "Warning Level 2" 3 "Warning Level 3" 4 "Warning Level 4" 5 "Warning Level 5" 6 "Warning Level 6" 7 "Warning Level 7" ;
VAL_ 2155929600 DslExFldTpWrngIndRq 15 "Warning Level 15" 14 "Warning Level 14" 13 "Warning Level 13" 12 "Warning Level 12" 11 "Warning Level 11" 10 "Warning Level 10" 9 "Warning Level 9" 8 "Warning Level 8" 7 "Warning Level 7" 6 "Warning Level 6" 5 "Warning Level 5" 4 "Warning Level 4" 3 "Warning Level 3" 2 "Warning Level 2" 1 "Warning Level 1" 0 "No Indication" ;
VAL_ 2155929600 DslExhFldQlyWrngIReq 15 "Warning Level 15" 14 "Warning Level 14" 13 "Warning Level 13" 12 "Warning Level 12" 11 "Warning Level 11" 10 "Warning Level 10" 9 "Warning Level 9" 8 "Warning Level 8" 7 "Warning Level 7" 6 "Warning Level 6" 5 "Warning Level 5" 4 "Warning Level 4" 3 "Warning Level 3" 2 "Warning Level 2" 1 "Warning Level 1" 0 "No Indication" ;
VAL_ 2155929600 DslExhFldWrngIdRqER 15 "Warning Level 15" 14 "Warning Level 14" 13 "Warning Level 13" 12 "Warning Level 12" 11 "Warning Level 11" 10 "Warning Level 10" 9 "Warning Level 9" 8 "Warning Level 8" 7 "Warning Level 7" 6 "Warning Level 6" 5 "Warning Level 5" 4 "Warning Level 4" 3 "Warning Level 3" 2 "Warning Level 2" 1 "Warning Level 1" 0 "No Indication" ;
VAL_ 2155929600 DslExFldCnWrngIndRq 15 "Warning Level 15" 14 "Warning Level 14" 13 "Warning Level 13" 12 "Warning Level 12" 11 "Warning Level 11" 10 "Warning Level 10" 9 "Warning Level 9" 8 "Warning Level 8" 7 "Warning Level 7" 6 "Warning Level 6" 5 "Warning Level 5" 4 "Warning Level 4" 3 "Warning Level 3" 2 "Warning Level 2" 1 "Warning Level 1" 0 "No Indication" ;
VAL_ 2155929600 DslExNxEmWrngIndRq 15 "Warning Level 15" 14 "Warning Level 14" 13 "Warning Level 13" 12 "Warning Level 12" 11 "Warning Level 11" 10 "Warning Level 10" 9 "Warning Level 9" 8 "Warning Level 8" 7 "Warning Level 7" 6 "Warning Level 6" 5 "Warning Level 5" 4 "Warning Level 4" 3 "Warning Level 3" 2 "Warning Level 2" 1 "Warning Level 1" 0 "No Indication" ;
VAL_ 2154807296 ESCMHiEleclLdReqAct 1 "true" 0 "false" ;
VAL_ 2154807296 EASSI_UnsdRsrvd2 1 "true" 0 "false" ;
VAL_ 2154807296 EASSI_StlDetd 1 "true" 0 "false" ;
VAL_ 2154807296 EASSI_TrqDetd 1 "true" 0 "false" ;
VAL_ 2154807296 EASSI_FuelReqOn 1 "true" 0 "false" ;
VAL_ 2154807296 EASSI_StrtTyp 7 "Type G" 6 "Type F" 5 "Type E" 4 "Type D" 3 "Type C" 2 "Type B" 1 "Type A" 0 "No Start" ;
VAL_ 2154807296 EASSI_StrtStpSt 3 "Engine Stopping" 2 "Engine Starting" 1 "Engine Running" 0 "Engine Off" ;
VAL_ 2154807296 EASSI_TorqDetdIndet 1 "true" 0 "false" ;
VAL_ 2154807296 EngAutoStpNotProb 1 "true" 0 "false" ;
VAL_ 2154807296 AFLMnu3CstStAvl 1 "true" 0 "false" ;
VAL_ 2154807296 AFLMnu2CstStAvl 1 "true" 0 "false" ;
VAL_ 2154807296 AFLGPSMnu2CstStAvl 1 "true" 0 "false" ;
VAL_ 2154807296 AFLGPSCstStAvl 1 "true" 0 "false" ;
VAL_ 2154807296 AFLGPSCstCrStVal 0 "No Value" 1 "Corner And Curve Lighting Only" 2 "Intelligent Light Distribution" 3 "GPS Assistance" 4 "Reserved1" 5 "Reserved2" 6 "Reserved3" 7 "Off" ;
VAL_ 2154807296 AFLCstStAvl 1 "true" 0 "false" ;
VAL_ 2154807296 AFLCstCrStVal 0 "No Value" 1 "Corner And Curve Lighting Only" 2 "Intelligent Light Distribution" 3 "Reserved1" 4 "Reserved2" 5 "Reserved3" 6 "Reserved4" 7 "Off" ;
VAL_ 2155364352 CstmrUsblSOCV 1 "Invalid" 0 "Valid" ;
VAL_ 2155364352 BattCntrlPrcssrVDA 1 "VirtualDeviceAvailable" 0 "VirtualDeviceUnavailable" ;
VAL_ 2155364352 JmpStrtStat 0 "Inactive" 1 "In Progress" 2 "Complete" 3 "Power Mode" 4 "Disabled" ;
VAL_ 2155364352 SvcHybridSysIO 1 "true" 0 "false" ;
VAL_ 2155364352 HybMdDisp 15 "Engine Charging Battery While Idle" 14 "Engine Charging Battery Moving" 13 "Engine Power Load Sharing" 12 "Battery Power Load Sharing" 11 "Undetermined" 10 "Charging With Engine On" 9 "Charging With Engine Off" 8 "Hybrid Power 4WD" 7 "Hybrid Power 2WD" 6 "Engine Power 4WD" 5 "Engine Power 2WD" 4 "Battery Power 4WD" 3 "Battery Power 2WD" 2 "Auto Stop" 1 "Engine Idle" 0 "Default / Accessory" ;
VAL_ 2155896832 AltFuelPHeatAct 1 "true" 0 "false" ;
VAL_ 2155896832 AltFuelMdReqDndIO 1 "true" 0 "false" ;
VAL_ 2155896832 AltFuelLvlLo 1 "true" 0 "false" ;
VAL_ 2155896832 AltFuelAccWrnngAct 1 "true" 0 "false" ;
VAL_ 2155896832 FuelAlcoholCompV 1 "Invalid" 0 "Valid" ;
VAL_ 2155896832 FuelAlchlCompAdptnPrg 1 "true" 0 "false" ;
VAL_ 2155896832 FuelMdStat 3 "Alternative Fuel Cut-off Active" 2 "Liquified Petroleum Gas Mode" 1 "Natural Gas Mode" 0 "Gasoline Mode" ;
VAL_ 2155896832 FlLvlTank2PctV 1 "Invalid" 0 "Valid" ;
VAL_ 2155175936 AdptCrsLKALDWSwAct 1 "City" 0 "Unknown" ;
VAL_ 2155175936 AdptCrsGapSwAct 2 "Increase Gap" 1 "Decrease Gap" 0 "No Activation" ;
VAL_ 2154078208 RRWndPosStat 6 "Fully Opened" 5 "Open More Than C" 4 "Position C" 3 "Posistion B" 2 "Posistion A" 1 "Open Less Than A" 0 "Fully Closed" ;
VAL_ 2154078208 PsWndPosStat 6 "Fully Opened" 5 "Open More Than C" 4 "Position C" 3 "Posistion B" 2 "Posistion A" 1 "Open Less Than A" 0 "Fully Closed" ;
VAL_ 2154078208 LRWndPosStat 6 "Fully Opened" 5 "Open More Than C" 4 "Position C" 3 "Posistion B" 2 "Posistion A" 1 "Open Less Than A" 0 "Fully Closed" ;
VAL_ 2154078208 DrvWndPosStat 6 "Fully Opened" 5 "Open More Than C" 4 "Position C" 3 "Posistion B" 2 "Posistion A" 1 "Open Less Than A" 0 "Fully Closed" ;
VAL_ 2155495424 RmStrHtdStEnRq 1 "true" 0 "false" ;
VAL_ 2155495424 RmStrCldStEnReq 1 "true" 0 "false" ;
VAL_ 2155413504 PsvLckngReqd 1 "true" 0 "false" ;
VAL_ 2155413504 DrvrDrKeyCylUlkSwAct 1 "true" 0 "false" ;
VAL_ 2155413504 DrvrDrKeyCylUlkSwActV 1 "Invalid" 0 "Valid" ;
VAL_ 2150367232 LrnEnvIdSt 1 "Info_valid" 0 "No_info" ;
VAL_ 2150367232 ImoIdSt 1 "Info valid" 0 "No info" ;
VAL_ 2150621184 KSARUID8 1 "Present" 0 "Not Present" ;
VAL_ 2150621184 KSARUID7 1 "Present" 0 "Not Present" ;
VAL_ 2150621184 KSARUID6 1 "Present" 0 "Not Present" ;
VAL_ 2150621184 KSARUID5 1 "Present" 0 "Not Present" ;
VAL_ 2150621184 KSARUID4 1 "Present" 0 "Not Present" ;
VAL_ 2150621184 KSARUID3 1 "Present" 0 "Not Present" ;
VAL_ 2150621184 KSARUID2 1 "Present" 0 "Not Present" ;
VAL_ 2150621184 KSARUID1 1 "Present" 0 "Not Present" ;
VAL_ 2154061824 WndOprAlwd 1 "true" 0 "false" ;
VAL_ 2154061824 RrDrUnlckIO 1 "true" 0 "false" ;
VAL_ 2154061824 RmtWndMvmntAtv 1 "true" 0 "false" ;
VAL_ 2154061824 RRWndNtNrmIndOn 1 "true" 0 "false" ;
VAL_ 2154061824 RLWndNtNrmIndOn 1 "true" 0 "false" ;
VAL_ 2154061824 DrWndNtNrmIndOn 1 "true" 0 "false" ;
VAL_ 2154061824 PsWndNtNrmIndOn 1 "true" 0 "false" ;
VAL_ 2154512384 RrClosRelSwActV 1 "Invalid" 0 "Valid" ;
VAL_ 2154512384 RrClosRelSwAct 1 "true" 0 "false" ;
VAL_ 2155347968 DrvrStPerfMdCsCrStVal 7 "Auto" 6 "Performance Mode 6" 5 "Performance Mode 5" 4 "Performance Mode 4" 3 "Performance Mode 3" 2 "Performance Mode 2" 1 "Performance Mode 1" 0 "No Action" ;
VAL_ 2155347968 DrvrStPerfMdCsStAvl 1 "true" 0 "false" ;
VAL_ 2155347968 ACCPerfMdCsCrStVal 7 "Auto" 6 "Performance Mode 6" 5 "Performance Mode 5" 4 "Performance Mode 4" 3 "Performance Mode 3" 2 "Performance Mode 2" 1 "Performance Mode 1" 0 "No Action" ;
VAL_ 2155347968 ACCPerfMdCsStAvl 1 "true" 0 "false" ;
VAL_ 2155347968 VehRollAngleV 1 "Invalid" 0 "Valid" ;
VAL_ 2155347968 ActVbnCtrlMlfIO 1 "true" 0 "false" ;
VAL_ 2155347968 HillDesCtrlRedVehSpIO 1 "true" 0 "false" ;
VAL_ 2155347968 FourWhlDrvIndReq 0 "No Indication" 1 "Indication 1" 2 "Indication 2" 3 "Indication 3" 4 "Indication 4" 5 "Indication 5" 6 "Indication 6" 7 "Indication 7" ;
VAL_ 2155347968 PedtrnProtVDA 1 "VirtualDeviceAvailable" 0 "VirtualDeviceUnavailable" ;
VAL_ 2155347968 EngRecDwnshftIO 1 "true" 0 "false" ;
VAL_ 2155347968 AppCltchAutSrtIO 1 "true" 0 "false" ;
VAL_ 2155347968 CPSUnblIO 1 "true" 0 "false" ;
VAL_ 2155347968 StBltTgtSetAvl 1 "true" 0 "false" ;
VAL_ 2155347968 StBltTgtCrtSetVal 0 "No Action" 1 "Low" 2 "Normal" 3 "Performance" 4 "Locked" ;
VAL_ 2155347968 PedtrnProtSysDisbld 1 "true" 0 "false" ;
VAL_ 2155347968 PedtrnProtSysDpl 1 "true" 0 "false" ;
VAL_ 2155347968 SrvPedtrnProtSysIO 1 "true" 0 "false" ;
VAL_ 2155347968 CPSOffIO 1 "true" 0 "false" ;
VAL_ 2155347968 SecAxlTmpInhIO 1 "true" 0 "false" ;
VAL_ 2155347968 CPSFldIO 1 "true" 0 "false" ;
VAL_ 2155347968 CPSAlrtOnlIO 1 "true" 0 "false" ;
VAL_ 2155347968 RrAxlTmpInhIO 1 "true" 0 "false" 1 "true" 0 "false" ;
VAL_ 2155347968 TirePrsLowIO 1 "true" 0 "false" ;
VAL_ 2155347968 EPBSysStatIndReq 3 "Flash Rate 2 Indication" 2 "Flash Rate 1 Indication" 1 "Continuous Indication" 0 "No Indication" ;
VAL_ 2155347968 EngOilStrvtnIO 1 "true" 0 "false" ;
VAL_ 2155347968 SrvSuspSysIO 1 "true" 0 "false" ;
VAL_ 2155347968 ServAdpCrsCtrlIndOn 1 "true" 0 "false" ;
VAL_ 2155347968 EngRecmndUpshftIO 1 "true" 0 "false" ;
VAL_ 2155347968 BrkSysMalFuncIndOn 1 "true" 0 "false" ;
VAL_ 2155347968 SecAxlNonEmMalfIO 1 "true" 0 "false" ;
VAL_ 2155347968 BrkFldLvlLw 1 "true" 0 "false" ;
VAL_ 2155347968 ACCUnavlbleDTWthrIO 1 "true" 0 "false" ;
VAL_ 2155347968 ACCTmpUnavlbleIO 1 "true" 0 "false" ;
VAL_ 2155347968 EngEmsRelMalfIndReq 4 "Flashing 0.5 Hertz Indication" 3 "Flashing 2 Hertz Indication" 2 "Flashing 1 Hertz Indication" 1 "No Indication" 0 "Continuous Indication" ;
VAL_ 2155347968 DrShftCntrlReqDndIO 1 "true" 0 "false" ;
VAL_ 2155347968 BrkPadWrnIO 1 "true" 0 "false" ;
VAL_ 2155347968 RrAxlMalfIO 1 "true" 0 "false" 1 "true" 0 "false" ;
VAL_ 2155347968 EPBSysWrnIndReq 3 "Flash Rate #2 Indication" 2 "Flash Rate #1 Indication" 1 "Continuous Indication" 0 "No Indication" ;
VAL_ 2155347968 CompOvrhtIndOn 1 "true" 0 "false" ;
VAL_ 2155347968 BrkFldLvlLwV 1 "Invalid" 0 "Valid" ;
VAL_ 2155347968 ACCSnsClnRqdIO 1 "true" 0 "false" ;
VAL_ 2155347968 TrnsSkpShftIO 1 "true" 0 "false" ;
VAL_ 2150432768 CbnHtrWrmUpIO 1 "true" 0 "false" ;
VAL_ 2150432768 EngManfldAirTempCrtdV 1 "Invalid" 0 "Valid" ;
VAL_ 2150432768 GrdBrkgAct 1 "true" 0 "false" ;
VAL_ 2150432768 FuelFltLifRstPerf 1 "true" 0 "false" ;
VAL_ 2150432768 EngShtdwnPndgIO 1 "true" 0 "false" ;
VAL_ 2150432768 GenFldDutCycV 1 "Invalid" 0 "Valid" ;
VAL_ 2150432768 TransOilTempSensPres 1 "true" 0 "false" ;
VAL_ 2150432768 TrnsNEmsRltMalfActv 1 "true" 0 "false" ;
VAL_ 2150432768 TrnEmsMlfAtv 1 "true" 0 "false" ;
VAL_ 2150432768 TrnsThrmlMngmntStat 2 "Driver Intervention Requested" 1 "Countermeasures Active" 0 "Normal" ;
VAL_ 2150432768 PTHiElecLdReqd 1 "true" 0 "false" ;
VAL_ 2154938368 FobProgMdStat 2 "Complete" 1 "Active" 0 "Inactive" ;
VAL_ 2155266048 RRHCSeatSw3Act 1 "true" 0 "false" ;
VAL_ 2155266048 RRHCSeatSw2Act 1 "true" 0 "false" ;
VAL_ 2155266048 RRHCSeatSw1Act 1 "true" 0 "false" ;
VAL_ 2155266048 RLHCSeatSw3Act 1 "true" 0 "false" ;
VAL_ 2155266048 RLHCSeatSw2Act 1 "true" 0 "false" ;
VAL_ 2155266048 RLHCSeatSw1Act 1 "true" 0 "false" ;
VAL_ 2155249664 RRHCSMInd3 1 "true" 0 "false" ;
VAL_ 2155249664 RRHCSMInd2 1 "true" 0 "false" ;
VAL_ 2155249664 RRHCSMInd1 1 "true" 0 "false" ;
VAL_ 2155249664 RRHCSMIndReq 3 "Flash Rate #2 Indication" 2 "Flash Rate #1 Indication" 1 "Continuous Indication" 0 "Off" ;
VAL_ 2155249664 RRHCSLSeatLev5 1 "true" 0 "false" ;
VAL_ 2155249664 RRHCSLSeatLev4 1 "true" 0 "false" ;
VAL_ 2155249664 RRHCSLSeatLev3 1 "true" 0 "false" ;
VAL_ 2155249664 RRHCSLSeatLev2 1 "true" 0 "false" ;
VAL_ 2155249664 RRHCSLSeatLev1 1 "true" 0 "false" ;
VAL_ 2155249664 RRHCSLIndReq 3 "Flash Rate #2 Indication" 2 "Flash Rate #1 Indication" 1 "Continuous Indication" 0 "Off" ;
VAL_ 2155249664 RLHCSMInd3 1 "true" 0 "false" ;
VAL_ 2155249664 RLHCSMInd2 1 "true" 0 "false" ;
VAL_ 2155249664 RLHCSMInd1 1 "true" 0 "false" ;
VAL_ 2155249664 RLHCSMIndReq 3 "Flash Rate #2 Indication" 2 "Flash Rate #1 Indication" 1 "Continuous Indication" 0 "Off" ;
VAL_ 2155249664 RLHCSLSeatLev5 1 "true" 0 "false" ;
VAL_ 2155249664 RLHCSLSeatLev4 1 "true" 0 "false" ;
VAL_ 2155249664 RLHCSLSeatLev3 1 "true" 0 "false" ;
VAL_ 2155249664 RLHCSLSeatLev2 1 "true" 0 "false" ;
VAL_ 2155249664 RLHCSLSeatLev1 1 "true" 0 "false" ;
VAL_ 2155249664 RLHCSLIndReq 3 "Flash Rate #2 Indication" 2 "Flash Rate #1 Indication" 1 "Continuous Indication" 0 "Off" ;
VAL_ 2155184128 SmPhRmFunCstCurStVal 7 "Unused and Reserved 5" 6 "Unused and Reserved 4" 5 "Unused and Reserved 3" 4 "Unused and Reserved 2" 3 "Unused and Reserved 1" 2 "On" 1 "Off" 0 "No Action" ;
VAL_ 2155184128 SmPhRmFunCstStAval 1 "true" 0 "false" ;
VAL_ 2155184128 RrStRmndrIO 1 "true" 0 "false" ;
VAL_ 2155184128 RrStRmndrCstCurrSetVal 2 "On" 1 "Off" 0 "No Action" ;
VAL_ 2155184128 RrStRmndrCstSetAvail 1 "true" 0 "false" ;
VAL_ 2155184128 IdlRecmndToClEngIO 1 "true" 0 "false" ;
VAL_ 2155184128 TrnsShftLvrLckStat 0 "Locked" 1 "Unlocked" ;
VAL_ 2155184128 CrsSpdLmtrSwStat 9 "Between Ranges" 8 "Short to Power" 7 "Open/Short to Ground" 6 "Cancel" 5 "Cruise On/Off" 4 "SL/SW On/Off/GAP" 3 "Set" 2 "Resume" 1 "No Activation" 0 "Indeterminate" ;
VAL_ 2155184128 CrsCntrlSwStCanSwAct 1 "true" 0 "false" ;
VAL_ 2155184128 CrsCntrlSwStSwDataIntgty 3 "Illegal Range" 2 "Failure Detected" 1 "Data Invalid" 0 "Data Valid" ;
VAL_ 2155184128 CrsCntrlSwStSpdInSwAct 1 "true" 0 "false" ;
VAL_ 2155184128 CrsCntrlSwStSpDcSwAct 1 "true" 0 "false" ;
VAL_ 2155184128 CrsCntrlSwStSetSwAct 1 "true" 0 "false" ;
VAL_ 2155184128 CrsCntrlSwStResSwAct 1 "true" 0 "false" ;
VAL_ 2155184128 CrsCntrlSwStOnSwAct 1 "true" 0 "false" ;
VAL_ 2155184128 CrsCntAtv 1 "true" 0 "false" ;
VAL_ 2154921984 RFRmtCntFobNm 5 "Remote Control Fob #5" 4 "Remote Control Fob #4" 3 "Remote Control Fob #3" 2 "Remote Control Fob #2" 1 "Remote Control Fob #1" 0 "No Fob" ;
VAL_ 2154921984 RFRmtCntrlFobFnc 31 "Charge Termination" 30 "Pwr Top Control Start Motion Contrl" 29 "Pwr Top Control Stop Motion Control" 28 "Comfort Close 2" 27 "Comfort Open 2" 26 "Connectivity Request" 25 "Comfort Close" 24 "Comfort Open" 23 "Right Sliding Dr Stop Motion Contrl" 22 "Left Sliding Dr Stop Motion Control" 21 "Pwr Rr Closure Start Motion Control" 20 "Pwr Rr Closure Stop Motion Control" 19 "All Door Double Lock" 18 "Pwr Rr Closure Stop While Opening" 17 "Pwr Rr Closure Stop While Closing" 16 "Power Rear Closure Open Control" 15 "Power Rear Closure Close Control" 14 "Locator Alarm Control" 13 "Fob Programmed" 12 "Engine Stop" 11 "Engine Run" 10 "Power Top Control" 9 "Power Window Control" 8 "Fuel Door Control" 7 "Panic Alarm Control" 6 "Right Sliding Door Control" 5 "Left Sliding Door Control" 4 "Rear Closure Control" 3 "All Door Unlock" 2 "Driver Door Unlock" 1 "Lock" 0 "No Activation" ;
VAL_ 2154921984 RFRmtCntFobBatLw 1 "true" 0 "false" ;
VAL_ 2154921984 FobPogLimRchdIndOn 1 "true" 0 "false" ;
VAL_ 2154962944 PassHCSMInd3 1 "true" 0 "false" ;
VAL_ 2154962944 PassHCSMInd2 1 "true" 0 "false" ;
VAL_ 2154962944 PassHCSMInd1 1 "true" 0 "false" ;
VAL_ 2154962944 PassHCSMIndReq 3 "Flash Rate #2 Indication" 2 "Flash Rate #1 Indication" 1 "Continuous Indication" 0 "Off" ;
VAL_ 2154962944 PassHCSLSeatLev5 1 "true" 0 "false" ;
VAL_ 2154962944 PassHCSLSeatLev4 1 "true" 0 "false" ;
VAL_ 2154962944 PassHCSLSeatLev3 1 "true" 0 "false" ;
VAL_ 2154962944 PassHCSLSeatLev2 1 "true" 0 "false" ;
VAL_ 2154962944 PassHCSLSeatLev1 1 "true" 0 "false" ;
VAL_ 2154962944 PassHCSLIndReq 0 "Off" 3 "Flash Rate #2 Indication" 2 "Flash Rate #1 Indication" 1 "Continuous Indication" ;
VAL_ 2154962944 DrvHCSMInd1 1 "true" 0 "false" ;
VAL_ 2154962944 DrvHCSMIndReq 3 "Flash Rate #2 Indication" 2 "Flash Rate #1 Indication" 1 "Continuous Indication" 0 "Off" ;
VAL_ 2154962944 DrvHCSMInd3 1 "true" 0 "false" ;
VAL_ 2154962944 DrvHCSMInd2 1 "true" 0 "false" ;
VAL_ 2154962944 DrvHCSLSeatLev5 1 "true" 0 "false" ;
VAL_ 2154962944 DrvHCSLSeatLev4 1 "true" 0 "false" ;
VAL_ 2154962944 DrvHCSLSeatLev3 1 "true" 0 "false" ;
VAL_ 2154962944 DrvHCSLSeatLev2 1 "true" 0 "false" ;
VAL_ 2154962944 DrvHCSLSeatLev1 1 "true" 0 "false" ;
VAL_ 2154962944 DrvHCSLIndReq 3 "Flash Rate #2 Indication" 2 "Flash Rate #1 Indication" 1 "Continuous Indication" 0 "Off" ;
VAL_ 2156232704 ACSAlarm9 2 "Expired" 1 "Active" 0 "Inactive" ;
VAL_ 2156232704 ACSAlarm8 2 "Expired" 1 "Active" 0 "Inactive" ;
VAL_ 2156232704 ACSAlarm7 2 "Expired" 1 "Active" 0 "Inactive" ;
VAL_ 2156232704 ACSAlarm6 2 "Expired" 1 "Active" 0 "Inactive" ;
VAL_ 2156232704 ACSAlarm5 2 "Expired" 1 "Active" 0 "Inactive" ;
VAL_ 2156232704 ACSAlarm4 2 "Expired" 1 "Active" 0 "Inactive" ;
VAL_ 2156232704 ACSAlarm3 2 "Expired" 1 "Active" 0 "Inactive" ;
VAL_ 2156232704 ACSAlarm2 2 "Expired" 1 "Active" 0 "Inactive" ;
VAL_ 2156232704 ACSAlarm15 2 "Expired" 1 "Active" 0 "Inactive" ;
VAL_ 2156232704 ACSAlarm14 2 "Expired" 1 "Active" 0 "Inactive" ;
VAL_ 2156232704 ACSAlarm13 2 "Expired" 1 "Active" 0 "Inactive" ;
VAL_ 2156232704 ACSAlarm12 2 "Expired" 1 "Active" 0 "Inactive" ;
VAL_ 2156232704 ACSAlarm11 2 "Expired" 1 "Active" 0 "Inactive" ;
VAL_ 2156232704 ACSAlarm10 2 "Expired" 1 "Active" 0 "Inactive" ;
VAL_ 2156232704 ACSAlarm1 2 "Expired" 1 "Active" 0 "Inactive" ;
VAL_ 2156232704 ACSAlarm0 2 "Expired" 1 "Active" 0 "Inactive" ;
VAL_ 2154987520 WrlsChrgSysChrgStat 7 "Unused and Reserved 2" 6 "Unused and Reserved 1" 5 "WCS Overtemp Shutdown" 4 "Foreign Object Detected" 0 "WCS Not Present" 1 "Charging Inactive" 2 "Charging Active" 3 "Charging Complete" ;
VAL_ 2154987520 HdStV 1 "Invalid" 0 "Valid" ;
VAL_ 2154987520 HdSt 2 "Open" 1 "Ajar" 0 "Closed" ;
VAL_ 2154840064 CmpsZnNvrSet 1 "true" 0 "false" ;
VAL_ 2154840064 CmpsSatrtd 1 "true" 0 "false" ;
VAL_ 2154840064 CmpsDecZone 15 "Zone 15" 14 "Zone 14" 13 "Zone 13" 12 "Zone 12" 11 "Zone 11" 10 "Zone 10" 9 "Zone 9" 8 "Zone 8" 7 "Zone 7" 6 "Zone 6" 5 "Zone 5" 4 "Zone 4" 3 "Zone 3" 2 "Zone 2" 1 "Zone 1" 0 "Unknown" ;
VAL_ 2154840064 CmpsOctHdingDataSrc 1 "Calculated Value" 0 "Stored Value" ;
VAL_ 2154840064 CmpsOctHding 7 "NW (North West)" 6 "W (West)" 5 "SW (South West)" 4 "S (South)" 3 "SE (South East)" 2 "E (East)" 1 "NE (North East)" 0 "N (North)" ;
VAL_ 2154840064 CmpsModManCalInPrc 1 "true" 0 "false" ;
VAL_ 2154840064 CmpsModFltPrs 1 "true" 0 "false" ;
VAL_ 2154905600 DrvSeatPrsMemID 0 "Memory #1" 1 "Memory #2" 2 "Memory #3" 3 "Memory #4" 4 "Memory #5" 5 "Memory #6" 6 "Memory #7" 7 "Unknown" ;
VAL_ 2154905600 DrId 7 "Unknown" 6 "Driver #7" 5 "Driver #6" 4 "Driver #5" 3 "Driver #4" 2 "Driver #3" 1 "Driver #2" 0 "Driver #1" ;
VAL_ 2151841792 HtdFrntWSSt 1 "ON" 0 "OFF" ;
VAL_ 2151841792 WSWprAct 1 "true" 0 "false" ;
VAL_ 2151841792 RnSnsOffIO 1 "true" 0 "false" ;
VAL_ 2151841792 RnSnsActIO 1 "true" 0 "false" ;
VAL_ 2151841792 TurnWprIntIO 1 "true" 0 "false" ;
VAL_ 2154094592 IDCTA_ClrTyp21Avl 1 "true" 0 "false" ;
VAL_ 2154094592 IDCTA_ClrTyp20Avl 1 "true" 0 "false" ;
VAL_ 2154094592 IDCTA_ClrTyp19Avl 1 "true" 0 "false" ;
VAL_ 2154094592 IDCTA_ClrTyp18Avl 1 "true" 0 "false" ;
VAL_ 2154094592 IDCTA_ClrTyp17Avl 1 "true" 0 "false" ;
VAL_ 2154094592 IDCTA_ClrTyp16Avl 1 "true" 0 "false" ;
VAL_ 2154094592 IDCTA_ClrTyp15Avl 1 "true" 0 "false" ;
VAL_ 2154094592 IDCTA_ClrTyp14Avl 1 "true" 0 "false" ;
VAL_ 2154094592 IDCTA_ClrTyp13Avl 1 "true" 0 "false" ;
VAL_ 2154094592 IDCTA_ClrTyp12Avl 1 "true" 0 "false" ;
VAL_ 2154094592 IDCTA_ClrTyp11Avl 1 "true" 0 "false" ;
VAL_ 2154094592 IDCTA_ClrTyp10Avl 1 "true" 0 "false" ;
VAL_ 2154094592 IDCTA_ClrTyp9Avl 1 "true" 0 "false" ;
VAL_ 2154094592 IDCTA_ClrTyp8Avl 1 "true" 0 "false" ;
VAL_ 2154094592 IDCTA_ClrTyp7Avl 1 "true" 0 "false" ;
VAL_ 2154094592 IDCTA_ClrTyp6Avl 1 "true" 0 "false" ;
VAL_ 2154094592 IDCTA_ClrTyp5Avl 1 "true" 0 "false" ;
VAL_ 2154094592 IDCTA_ClrTyp4Avl 1 "true" 0 "false" ;
VAL_ 2154094592 IDCTA_ClrTyp3Avl 1 "true" 0 "false" ;
VAL_ 2154094592 IDCTA_ClrTyp2Avl 1 "true" 0 "false" ;
VAL_ 2154094592 IDCTA_ClrTyp1Avl 1 "true" 0 "false" ;
VAL_ 2154094592 IDCTA_OffAvl 1 "true" 0 "false" ;
VAL_ 2154094592 IDATA_AnmTyp14Avl 1 "true" 0 "false" ;
VAL_ 2154094592 IDATA_AnmTyp13Avl 1 "true" 0 "false" ;
VAL_ 2154094592 IDATA_AnmTyp12Avl 1 "true" 0 "false" ;
VAL_ 2154094592 IDATA_AnmTyp11Avl 1 "true" 0 "false" ;
VAL_ 2154094592 IDATA_AnmTyp10Avl 1 "true" 0 "false" ;
VAL_ 2154094592 IDATA_AnmTyp9Avl 1 "true" 0 "false" ;
VAL_ 2154094592 IDATA_AnmTyp8Avl 1 "true" 0 "false" ;
VAL_ 2154094592 IDATA_AnmTyp7Avl 1 "true" 0 "false" ;
VAL_ 2154094592 IDATA_AnmTyp6Avl 0 "false" 1 "true" ;
VAL_ 2154094592 IDATA_AnmTyp5Avl 1 "true" 0 "false" ;
VAL_ 2154094592 IDATA_AnmTyp4Avl 1 "true" 0 "false" ;
VAL_ 2154094592 IDATA_AnmTyp3Avl 1 "true" 0 "false" ;
VAL_ 2154094592 IDATA_AnmTyp2Avl 1 "true" 0 "false" ;
VAL_ 2154094592 IDATA_AnmTyp1Avl 1 "true" 0 "false" ;
VAL_ 2154094592 IDATA_OffAvl 1 "true" 0 "false" ;
VAL_ 2154094592 AdjPdlMotInhbtd 1 "true" 0 "false" ;
VAL_ 2154094592 IntDimSeldClrTypStVal 31 "Color Type 30" 30 "Color Type 29" 29 "Color Type 28" 28 "Color Type 27" 27 "Color Type 26" 26 "Color Type 25" 25 "Color Type 24" 24 "Color Type 23" 23 "Color Type 22" 22 "Color Type 21" 21 "Color Type 20" 20 "Color Type 19" 19 "Color Type 18" 18 "Color Type 17" 17 "Color Type 16" 16 "Color Type 15" 15 "Color Type 14" 14 "Color Type 13" 13 "Color Type 12" 12 "Color Type 11" 11 "Color Type 10" 10 "Color Type 9" 9 "Color Type 8" 8 "Color Type 7" 7 "Color Type 6" 6 "Color Type 5" 5 "Color Type 4" 4 "Color Type 3" 3 "Color Type 2" 2 "Color Type 1" 1 "Off" 0 "No Action" ;
VAL_ 2154094592 IntDimSeldAnmTypStVal 15 "Animation Type 14" 14 "Animation Type 13" 13 "Animation Type 12" 12 "Animation Type 11" 11 "Animation Type 10" 10 "Animation Type 9" 9 "Animation Type 8" 8 "Animation Type 7" 7 "Animation Type 6" 6 "Animation Type 5" 5 "Animation Type 4" 4 "Animation Type 3" 3 "Animation Type 2" 2 "Animation Type 1" 1 "Off" 0 "No Action" ;
VAL_ 2154094592 IDCTA_ClrTyp30Avl 1 "true" 0 "false" ;
VAL_ 2154094592 IDCTA_ClrTyp29Avl 1 "true" 0 "false" ;
VAL_ 2154094592 IDCTA_ClrTyp28Avl 1 "true" 0 "false" ;
VAL_ 2154094592 IDCTA_ClrTyp27Avl 1 "true" 0 "false" ;
VAL_ 2154094592 IDCTA_ClrTyp26Avl 1 "true" 0 "false" ;
VAL_ 2154094592 IDCTA_ClrTyp25Avl 1 "true" 0 "false" ;
VAL_ 2154094592 IDCTA_ClrTyp24Avl 1 "true" 0 "false" ;
VAL_ 2154094592 IDCTA_ClrTyp23Avl 1 "true" 0 "false" ;
VAL_ 2154094592 IDCTA_ClrTyp22Avl 1 "true" 0 "false" ;
VAL_ 2153979904 RtPrkLtFld 1 "true" 0 "false" ;
VAL_ 2153979904 RtLwBmFld 1 "true" 0 "false" ;
VAL_ 2153979904 RtDytmRunLmpFld 1 "true" 0 "false" ;
VAL_ 2153979904 RtBrkLtFld 1 "true" 0 "false" ;
VAL_ 2153979904 RRTrnIndLtFld 1 "true" 0 "false" ;
VAL_ 2153979904 RLTrnIndLtFld 1 "true" 0 "false" ;
VAL_ 2153979904 LicPltLtFld 1 "true" 0 "false" ;
VAL_ 2153979904 LftPrkLtFld 1 "true" 0 "false" ;
VAL_ 2153979904 LftLwBmFld 1 "true" 0 "false" ;
VAL_ 2153979904 LftBrkLtFld 1 "true" 0 "false" ;
VAL_ 2153979904 FRTrnIndLtFld 1 "true" 0 "false" ;
VAL_ 2153979904 FLTrnIndLtFld 1 "true" 0 "false" ;
VAL_ 2153979904 CHMSLFld 1 "true" 0 "false" ;
VAL_ 2153979904 LftDytmRunLmpFld 1 "true" 0 "false" ;
VAL_ 2153979904 RvsLtFld 1 "true" 0 "false" ;
VAL_ 2153979904 RFgLtFld 1 "true" 0 "false" ;
VAL_ 2151497728 TireLFPrsStat 5 "High" 4 "Low - Extended Mobility" 3 "Low" 2 "Low - Service Now" 1 "Nominal" 0 "Unknown" ;
VAL_ 2151497728 TireLFPrsV 1 "Invalid" 0 "Valid" ;
VAL_ 2151497728 TireLRPrsStat 5 "High" 4 "Low - Extended Mobility" 3 "Low" 2 "Low - Service Now" 1 "Nominal" 0 "Unknown" ;
VAL_ 2151497728 TireLRPrsV 1 "Invalid" 0 "Valid" ;
VAL_ 2151497728 TireRFPrsStat 5 "High" 4 "Low - Extended Mobility" 3 "Low" 2 "Low - Service Now" 1 "Nominal" 0 "Unknown" ;
VAL_ 2151497728 TireRFPrsV 1 "Invalid" 0 "Valid" ;
VAL_ 2151497728 TireRRPrsStat 5 "High" 4 "Low - Extended Mobility" 3 "Low" 2 "Low - Service Now" 1 "Nominal" 0 "Unknown" ;
VAL_ 2151497728 TireRRPrsV 1 "Invalid" 0 "Valid" ;
VAL_ 2151219200 RemStrtSt 1 "Active" 0 "Inactive" ;
VAL_ 2151219200 RmVehStrRq 1 "Remote Start Requested" 0 "Remote Start Not Requested" ;
VAL_ 2151235584 EhnSrvImmbComRst 1 "true" 0 "false" ;
VAL_ 2151235584 AlcKyIIncmIndOn 1 "true" 0 "false" ;
VAL_ 2151235584 VehSecAuthnSesComp 1 "true" 0 "false" ;
VAL_ 2151235584 VTDTmprDetected 1 "true" 0 "false" ;
VAL_ 2151235584 VehSecSysFldIO 1 "true" 0 "false" ;
VAL_ 2151235584 VehSecStrgColLckPwdV 1 "Invalid" 0 "Valid" ;
VAL_ 2151235584 VhSecNImmoIndRq 2 "Flashing Indication" 1 "Continuous Indication" 0 "No Indication" ;
VAL_ 2151235584 StrgColLckCmd 3 "Failure Code Retrieval Required" 2 "Lock" 1 "Unlock" 0 "No Command" ;
VAL_ 2151235584 DrIdDevLrnd 1 "Learned" 0 "Not Learned" ;
VAL_ 2151235584 IllDrIdDevDtctd 1 "true" 0 "false" ;
VAL_ 2151235584 EhnSrvEngImmStat 1 "Immobilized" 0 "Not Immobilized" ;
VAL_ 2151235584 ClmSysBkupFlrIndOn 1 "true" 0 "false" ;
VAL_ 2151235584 VehStatStAtv 1 "true" 0 "false" ;
SIG_GROUP_ 2149761024 TrnsCltchThrmlProtIndR 1 : TCTPIR_TnsEsClCDwT TCTPIR_TnsEsClTmpD TCTPIR_DrvNotfn;
SIG_GROUP_ 2155929600 DslExFldWrngVSpdLmt 1 : DEFWVSL_S3SpdLmt DEFWVSL_S2SpdLmt DEFWVSL_S1SpdLmt;
SIG_GROUP_ 2154807296 EngAutoStrtStpInfo 1 : EASSI_UnsdRsrvd2 EASSI_StlDetd EASSI_TrqDetd EASSI_FuelReqOn EASSI_StrtTyp EASSI_StrtStpSt EASSI_TorqDetdIndet;
SIG_GROUP_ 2150621184 KylsStrAuthRslt 1 : KSARUID8 KSARUID7 KSARUID6 KSARUID5 KSARUID4 KSARUID3 KSARUID2 KSARUID1;
SIG_GROUP_ 2155249664 RRHCSModeIndCtrl 1 : RRHCSMInd3 RRHCSMInd2 RRHCSMInd1 RRHCSMIndReq;
SIG_GROUP_ 2155249664 RRHCSeatLevIndCtrl 1 : RRHCSLSeatLev5 RRHCSLSeatLev4 RRHCSLSeatLev3 RRHCSLSeatLev2 RRHCSLSeatLev1 RRHCSLIndReq;
SIG_GROUP_ 2155249664 RLHCSModeIndCtrl 1 : RLHCSMInd3 RLHCSMInd2 RLHCSMInd1 RLHCSMIndReq;
SIG_GROUP_ 2155249664 RLHCSeatLevIndCtrl 1 : RLHCSLSeatLev5 RLHCSLSeatLev4 RLHCSLSeatLev3 RLHCSLSeatLev2 RLHCSLSeatLev1 RLHCSLIndReq;
SIG_GROUP_ 2155184128 CrsCntrlSwStat 1 : CrsCntrlSwStCanSwAct CrsCntrlSwStSwDataIntgty CrsCntrlSwStSpdInSwAct CrsCntrlSwStSpDcSwAct CrsCntrlSwStSetSwAct CrsCntrlSwStResSwAct CrsCntrlSwStOnSwAct;
SIG_GROUP_ 2154921984 RFAFnc 1 : RFRmtCntFobNm RFRmtCntrlFobFnc RFRmtCntFobBatLw;
SIG_GROUP_ 2154962944 PassHCSModeIndCtrl 1 : PassHCSMInd3 PassHCSMInd2 PassHCSMInd1 PassHCSMIndReq;
SIG_GROUP_ 2154962944 PassHCSeatLevIndCtrl 1 : PassHCSLSeatLev5 PassHCSLSeatLev4 PassHCSLSeatLev3 PassHCSLSeatLev2 PassHCSLSeatLev1 PassHCSLIndReq;
SIG_GROUP_ 2154962944 DrvHCSModeIndCtrl 1 : DrvHCSMInd1 DrvHCSMIndReq DrvHCSMInd3 DrvHCSMInd2;
SIG_GROUP_ 2154962944 DrvHCSLevIndCtrl 1 : DrvHCSLSeatLev5 DrvHCSLSeatLev4 DrvHCSLSeatLev3 DrvHCSLSeatLev2 DrvHCSLSeatLev1 DrvHCSLIndReq;
SIG_GROUP_ 2156232704 AlrmClkStat 1 : ACSAlarm9 ACSAlarm8 ACSAlarm7 ACSAlarm6 ACSAlarm5 ACSAlarm4 ACSAlarm3 ACSAlarm2 ACSAlarm15 ACSAlarm14 ACSAlarm13 ACSAlarm12 ACSAlarm11 ACSAlarm10 ACSAlarm1 ACSAlarm0;
SIG_GROUP_ 2154094592 IntDimClrTypAvl 1 : IDCTA_ClrTyp30Avl IDCTA_ClrTyp29Avl IDCTA_ClrTyp28Avl IDCTA_ClrTyp27Avl IDCTA_ClrTyp26Avl IDCTA_ClrTyp25Avl IDCTA_ClrTyp24Avl IDCTA_ClrTyp23Avl IDCTA_ClrTyp22Avl IDCTA_ClrTyp21Avl IDCTA_ClrTyp20Avl IDCTA_ClrTyp19Avl IDCTA_ClrTyp18Avl IDCTA_ClrTyp17Avl IDCTA_ClrTyp16Avl IDCTA_ClrTyp15Avl IDCTA_ClrTyp14Avl IDCTA_ClrTyp13Avl IDCTA_ClrTyp12Avl IDCTA_ClrTyp11Avl IDCTA_ClrTyp10Avl IDCTA_ClrTyp9Avl IDCTA_ClrTyp8Avl IDCTA_ClrTyp7Avl IDCTA_ClrTyp6Avl IDCTA_ClrTyp5Avl IDCTA_ClrTyp4Avl IDCTA_ClrTyp3Avl IDCTA_ClrTyp2Avl IDCTA_ClrTyp1Avl IDCTA_OffAvl;
SIG_GROUP_ 2154094592 IntDimAnmTypAvl 1 : IDATA_AnmTyp14Avl IDATA_AnmTyp13Avl IDATA_AnmTyp12Avl IDATA_AnmTyp11Avl IDATA_AnmTyp10Avl IDATA_AnmTyp9Avl IDATA_AnmTyp8Avl IDATA_AnmTyp7Avl IDATA_AnmTyp6Avl IDATA_AnmTyp5Avl IDATA_AnmTyp4Avl IDATA_AnmTyp3Avl IDATA_AnmTyp2Avl IDATA_AnmTyp1Avl IDATA_OffAvl;
